VERSION ""

NS_ :

BS_:

BU_: FileEditor Browser FileServer

BO_ 2362179326 PD: 14 Vector__XXX
 SG_ MinimumProductPressure m195 : 32|32@1- (0.1,0) [-2147483648|2147483647] "Pa" Vector__XXX
 SG_ MaximumProductPressure m196 : 32|32@1- (0.1,0) [-2147483648|2147483647] "Pa" Vector__XXX
 SG_ SetpointPumpOutputPressure m197 : 32|32@1- (0.1,0) [-2147483648|2147483647] "Pa" Vector__XXX
 SG_ ActualPumpOutputPressure m198 : 32|32@1- (0.1,0) [-2147483648|2147483647] "Pa" Vector__XXX
 SG_ MinimumPumpOutputPressure m199 : 32|32@1- (0.1,0) [-2147483648|2147483647] "Pa" Vector__XXX
 SG_ MaximumPumpOutputPressure m200 : 32|32@1- (0.1,0) [-2147483648|2147483647] "Pa" Vector__XXX
 SG_ SetpointTankAgitationPressure m201 : 32|32@1- (0.1,0) [-2147483648|2147483647] "Pa" Vector__XXX
 SG_ ActualTankAgitationPressure m202 : 32|32@1- (0.1,0) [-2147483648|2147483647] "Pa" Vector__XXX
 SG_ MinimumTankAgitationPressure m203 : 32|32@1- (0.1,0) [-2147483648|2147483647] "Pa" Vector__XXX
 SG_ MaximumTankAgitationPressure m204 : 32|32@1- (0.1,0) [-2147483648|2147483647] "Pa" Vector__XXX
 SG_ SCTurnOnTime_ m205 : 32|32@1- (1,0) [-2147483648|2147483647] "ms" Vector__XXX
 SG_ SCTurnOffTime m206 : 32|32@1- (1,0) [-2147483648|2147483647] "ms" Vector__XXX
 SG_ WindSpeed m207 : 32|32@1- (1,0) [0|100000000] "mm/s" Vector__XXX
 SG_ WindDirection m208 : 32|32@1- (1,0) [0|359] "°" Vector__XXX
 SG_ AirHumidity m209 : 32|32@1- (1,0) [0|100] "%" Vector__XXX
 SG_ SkyConditions m210 : 32|32@1- (1,0) [-2147483648|2147483647] "" Vector__XXX
 SG_ LastBaleFlakesPerBale m211 : 32|32@1- (1,0) [0|1000] "Amount/Count" Vector__XXX
 SG_ LastBaleAverageMoisture m212 : 32|32@1- (1,0) [0|100000000] "ppm" Vector__XXX
 SG_ LastBaleAverageStrokesPerFlake m213 : 32|32@1- (1,0) [0|1000] "Amount/Count" Vector__XXX
 SG_ LifetimeBaleCount m214 : 32|32@1- (1,0) [0|2147483647] "Amount/Count" Vector__XXX
 SG_ LifetimeWorkingHours m215 : 32|32@1- (0.05,0) [0|2147483647] "h" Vector__XXX
 SG_ ActualBaleHydraulicPressure m216 : 32|32@1- (1,0) [0|2147483647] "Pa" Vector__XXX
 SG_ LastBaleAverageHydraulicPressure m217 : 32|32@1- (1,0) [0|2147483647] "Pa" Vector__XXX
 SG_ SetpointBaleCompressionPlungerLo m218 : 32|32@1- (1,0) [0|2000] "" Vector__XXX
 SG_ ActualBaleCompressionPlungerLoad m219 : 32|32@1- (1,0) [0|2000] "" Vector__XXX
 SG_ LastBaleAverageBaleCompressionPl m220 : 32|32@1- (1,0) [0|2000] "" Vector__XXX
 SG_ LastBaleAppliedPreservative m221 : 32|32@1- (1,0) [0|2147483647] "ml" Vector__XXX
 SG_ LastBaleTagNumber m222 : 32|32@1- (1,0) [0|2147483647] "" Vector__XXX
 SG_ LastBaleMass m223 : 32|32@1- (1,0) [0|2147483647] "g" Vector__XXX
 SG_ DeltaT m224 : 32|32@1- (1,0) [0|1000000] "mK" Vector__XXX
 SG_ SetpointWorkingLength m225 : 32|32@1- (1,0) [-2147483648|2147483647] "mm" Vector__XXX
 SG_ ActualWorkingLength m226 : 32|32@1- (1,0) [-2147483648|2147483647] "mm" Vector__XXX
 SG_ MinimumWorkingLength m227 : 32|32@1- (1,0) [-2147483648|2147483647] "mm" Vector__XXX
 SG_ MaximumWorkingLength m228 : 32|32@1- (1,0) [-2147483648|2147483647] "mm" Vector__XXX
 SG_ ActualNetWeight m229 : 32|32@1- (1,0) [-2147483648|2147483647] "g" Vector__XXX
 SG_ NetWeightState m230 : 32|32@1- (1,0) [0|3] "" Vector__XXX
 SG_ SetpointNetWeight m231 : 32|32@1- (1,0) [-2147483648|2147483647] "g" Vector__XXX
 SG_ ActualGrossWeight m232 : 32|32@1- (1,0) [-2147483648|2147483647] "g" Vector__XXX
 SG_ GrossWeightState m233 : 32|32@1- (1,0) [0|3] "" Vector__XXX
 SG_ MinimumGrossWeight m234 : 32|32@1- (1,0) [-2147483648|2147483647] "g" Vector__XXX
 SG_ MaximumGrossWeight m235 : 32|32@1- (1,0) [-2147483648|2147483647] "g" Vector__XXX
 SG_ ThreshingEngagementTotalTime m236 : 32|32@1- (1,0) [0|2147483647] "s" Vector__XXX
 SG_ ActualHeaderWorkingHeightStatus m237 : 32|32@1- (1,0) [0|3] "" Vector__XXX
 SG_ ActualHeaderRotationalSpeedStatu m238 : 32|32@1- (1,0) [0|3] "" Vector__XXX
 SG_ YieldHoldStatus m239 : 32|32@1- (1,0) [0|3] "" Vector__XXX
 SG_ ActualUnLoadingSystemStatus m240 : 32|32@1- (1,0) [0|771] "" Vector__XXX
 SG_ CropTemperature m241 : 32|32@1- (1,0) [0|1000000] "mK" Vector__XXX
 SG_ SetpointSieveClearance m242 : 32|32@1- (1,0) [0|2147483647] "mm" Vector__XXX
 SG_ ActualSieveClearance m243 : 32|32@1- (1,0) [0|2147483647] "mm" Vector__XXX
 SG_ MinimumSieveClearance m244 : 32|32@1- (1,0) [0|2147483647] "mm" Vector__XXX
 SG_ MaximumSieveClearance m245 : 32|32@1- (1,0) [0|2147483647] "mm" Vector__XXX
 SG_ SetpointChafferClearance m246 : 32|32@1- (1,0) [0|2147483647] "mm" Vector__XXX
 SG_ ActualChafferClearance m247 : 32|32@1- (1,0) [0|2147483647] "mm" Vector__XXX
 SG_ MinimumChafferClearance m248 : 32|32@1- (1,0) [0|2147483647] "mm" Vector__XXX
 SG_ MaximumChafferClearance m249 : 32|32@1- (1,0) [0|2147483647] "mm" Vector__XXX
 SG_ SetpointConcaveClearance m250 : 32|32@1- (1,0) [0|2147483647] "mm" Vector__XXX
 SG_ ActualConcaveClearance m251 : 32|32@1- (1,0) [0|2147483647] "mm" Vector__XXX
 SG_ MinimumConcaveClearance m252 : 32|32@1- (1,0) [0|2147483647] "mm" Vector__XXX
 SG_ MaximumConcaveClearance m253 : 32|32@1- (1,0) [0|2147483647] "mm" Vector__XXX
 SG_ SetpointSeparationFanRotationalS m254 : 32|32@1- (0.001,0) [0|2147483647] "1/s" Vector__XXX
 SG_ ActualSeparationFanRotationalSpe m255 : 32|32@1- (0.001,0) [0|2147483647] "1/s" Vector__XXX
 SG_ MinimumSeparationFanRotationalSp m256 : 32|32@1- (0.001,0) [0|2147483647] "1/s" Vector__XXX
 SG_ MaximumSeparationFanRotationalSp m257 : 32|32@1- (0.001,0) [0|2147483647] "1/s" Vector__XXX
 SG_ HydraulicOilTemperature m258 : 32|32@1- (1,0) [0|2000000] "mK" Vector__XXX
 SG_ YieldLagIgnoreTime m259 : 32|32@1- (1,0) [0|2147483647] "ms" Vector__XXX
 SG_ YieldLeadIgnoreTime m260 : 32|32@1- (1,0) [0|2147483647] "ms" Vector__XXX
 SG_ AverageYieldMassPerTime m261 : 32|32@1- (1,0) [0|2147483647] "mg/s" Vector__XXX
 SG_ AverageCropMoisture m262 : 32|32@1- (1,0) [0|2147483647] "ppm" Vector__XXX
 SG_ AverageYieldMassPerArea m263 : 32|32@1- (1,0) [0|2147483647] "mg/m²" Vector__XXX
 SG_ ConnectorPivotXOffset m264 : 32|32@1- (1,0) [-2147483648|2147483647] "mm" Vector__XXX
 SG_ RemainingArea m265 : 32|32@1- (1,0) [0|2147483647] "m²" Vector__XXX
 SG_ LifetimeApplicationTotalMass m266 : 32|32@1- (1,0) [0|2147483647] "kg" Vector__XXX
 SG_ LifetimeApplicationTotalCount m267 : 32|32@1- (1,0) [0|2147483647] "" Vector__XXX
 SG_ LifetimeYieldTotalVolume m268 : 32|32@1- (1,0) [0|2147483647] "L" Vector__XXX
 SG_ LifetimeYieldTotalMass m269 : 32|32@1- (1,0) [0|2147483647] "kg" Vector__XXX
 SG_ LifetimeYieldTotalCount m270 : 32|32@1- (1,0) [0|2147483647] "" Vector__XXX
 SG_ LifetimeTotalArea m271 : 32|32@1- (1,0) [0|2147483647] "m²" Vector__XXX
 SG_ LifetimeTotalDistance m272 : 32|32@1- (1,0) [0|2147483647] "m" Vector__XXX
 SG_ LifetimeIneffectiveTotalDistance m273 : 32|32@1- (1,0) [0|2147483647] "m" Vector__XXX
 SG_ LifetimeEffectiveTotalTime m274 : 32|32@1- (1,0) [0|2147483647] "s" Vector__XXX
 SG_ LifetimeIneffectiveTotalTime m275 : 32|32@1- (1,0) [0|2147483647] "s" Vector__XXX
 SG_ LifetimeFuelConsumption m276 : 32|32@1- (0.5,0) [0|2147483647] "L" Vector__XXX
 SG_ LifetimeAverageFuelConsumptionPe m277 : 32|32@1- (1,0) [0|2147483647] "mm³/s" Vector__XXX
 SG_ LifetimeAverageFuelConsumpt_0000 m278 : 32|32@1- (1,0) [0|2147483647] "mm³/m²" Vector__XXX
 SG_ LifetimeYieldTotalDryMass m279 : 32|32@1- (1,0) [0|2147483647] "kg" Vector__XXX
 SG_ LifetimeYieldTotalSeedCottonMass m280 : 32|32@1- (1,0) [0|2147483647] "" Vector__XXX
 SG_ LifetimeYieldTotalLintCottonMass m281 : 32|32@1- (1,0) [0|2147483647] "kg" Vector__XXX
 SG_ LifetimeThreshingEngagementTotal m282 : 32|32@1- (1,0) [0|2147483647] "s" Vector__XXX
 SG_ PrecutTotalCount m283 : 32|32@1- (1,0) [0|2147483647] "" Vector__XXX
 SG_ UncutTotalCount m284 : 32|32@1- (1,0) [0|2147483647] "" Vector__XXX
 SG_ LifetimePrecutTotalCount m285 : 32|32@1- (1,0) [0|2147483647] "" Vector__XXX
 SG_ LifetimeUncutTotalCount m286 : 32|32@1- (1,0) [0|2147483647] "" Vector__XXX
 SG_ SetpointWorkState m289 : 32|32@1- (1,0) [0|3] "" Vector__XXX
 SG_ SetpointCondensedWorkState1to16 m290 : 32|32@1+ (1,0) [0|4294967295] "" Vector__XXX
 SG_ SetpointCondensedWorkState17to32 m291 : 32|32@1+ (1,0) [0|4294967295] "" Vector__XXX
 SG_ SetpointCondensedWorkState33to48 m292 : 32|32@1+ (1,0) [0|4294967295] "" Vector__XXX
 SG_ SetpointCondensedWorkState49to64 m293 : 32|32@1+ (1,0) [0|4294967295] "" Vector__XXX
 SG_ SetpointCondensedWorkState65to80 m294 : 32|32@1+ (1,0) [0|4294967295] "" Vector__XXX
 SG_ SetpointCondensedWorkState81to96 m295 : 32|32@1+ (1,0) [0|4294967295] "" Vector__XXX
 SG_ SetpointCondensedWorkState97to11 m296 : 32|32@1+ (1,0) [0|4294967295] "" Vector__XXX
 SG_ SetpointCondensedWorkState113to1 m297 : 32|32@1+ (1,0) [0|4294967295] "" Vector__XXX
 SG_ SetpointCondensedWorkState129to1 m298 : 32|32@1+ (1,0) [0|4294967295] "" Vector__XXX
 SG_ SetpointCondensedWorkState145to1 m299 : 32|32@1+ (1,0) [0|4294967295] "" Vector__XXX
 SG_ SetpointCondensedWorkState161to1 m300 : 32|32@1+ (1,0) [0|4294967295] "" Vector__XXX
 SG_ SetpointCondensedWorkState177to1 m301 : 32|32@1+ (1,0) [0|4294967295] "" Vector__XXX
 SG_ SetpointCondensedWorkState193to2 m302 : 32|32@1+ (1,0) [0|4294967295] "" Vector__XXX
 SG_ SetpointCondensedWorkState209to2 m303 : 32|32@1+ (1,0) [0|4294967295] "" Vector__XXX
 SG_ SetpointCondensedWorkState225to2 m304 : 32|32@1+ (1,0) [0|4294967295] "" Vector__XXX
 SG_ SetpointCondensedWorkState241to2 m305 : 32|32@1+ (1,0) [0|4294967295] "" Vector__XXX
 SG_ TrueRotationPointXOffset m306 : 32|32@1- (1,0) [-2147483648|2147483647] "mm" Vector__XXX
 SG_ TrueRotationPointYOffset m307 : 32|32@1- (1,0) [-2147483648|2147483647] "mm" Vector__XXX
 SG_ ActualPercentageApplicationRate m308 : 32|32@1- (1,0) [0|2147483647] "ppm" Vector__XXX
 SG_ MinimumPercentageApplicationRate m309 : 32|32@1- (1,0) [0|2147483647] "ppm" Vector__XXX
 SG_ MaximumPercentageApplicationRate m310 : 32|32@1- (1,0) [0|2147483647] "ppm" Vector__XXX
 SG_ RelativeYieldPotential m311 : 32|32@1- (1,0) [0|2147483647] "ppm" Vector__XXX
 SG_ MinimumRelativeYieldPotential m312 : 32|32@1- (1,0) [0|2147483647] "ppm" Vector__XXX
 SG_ MaximumRelativeYieldPotential m313 : 32|32@1- (1,0) [0|2147483647] "ppm" Vector__XXX
 SG_ ActualPercentageCropDryMatter m314 : 32|32@1- (1,0) [0|2147483647] "ppm" Vector__XXX
 SG_ AveragePercentageCropDryMatter m315 : 32|32@1- (1,0) [0|2147483647] "ppm" Vector__XXX
 SG_ EffectiveTotalFuelConsumption m316 : 32|32@1- (1,0) [0|2147483647] "ml" Vector__XXX
 SG_ IneffectiveTotalFuelConsumption m317 : 32|32@1- (1,0) [0|2147483647] "ml" Vector__XXX
 SG_ EffectiveTotalDieselExhaustFluid m318 : 32|32@1- (1,0) [0|2147483647] "ml" Vector__XXX
 SG_ IneffectiveTotalDieselExhaustFlu m319 : 32|32@1- (1,0) [0|2147483647] "ml" Vector__XXX
 SG_ LastLoadedWeight m320 : 32|32@1- (1,0) [0|2147483647] "g" Vector__XXX
 SG_ LastUnloadedWeight m321 : 32|32@1- (1,0) [0|2147483647] "g" Vector__XXX
 SG_ PGNBasedData m57342 : 32|32@1- (1,0) [-2147483648|2147483647] "" Vector__XXX
 SG_ RequestDefaultProcessData m57343 : 32|32@1- (1,0) [0|0] "" Vector__XXX
 SG_ ObjectIdOfFaultyObject m9 : 32|16@1+ (1,0) [0|65535] "" Vector__XXX
 SG_ ErrorCodeProcessData1 m13 : 32|1@1+ (1,0) [0|1] "" Vector__XXX
 SG_ StatusTotalsActive m14 : 32|1@1+ (1,0) [0|1] "" Vector__XXX
 SG_ Status_TotalsActive m15 : 32|1@1+ (1,0) [0|1] "" Vector__XXX
 SG_ DateFormatCmd m2 : 32|8@1+ (1,0) [0|255] "" Vector__XXX
 SG_ DataDictionaryVersion m0 : 32|32@1- (1,0) [0|21474800] "" Vector__XXX
 SG_ PeerControlCommand m9M : 32|4@1+ (1,0) [0|5] "" Vector__XXX
 SG_ DecimalSymbolCmd m2 : 30|2@1+ (1,0) [0|3] "" Vector__XXX
 SG_ TimeFormatCmd m2 : 28|2@1+ (1,0) [0|3] "" Vector__XXX
 SG_ ImplementSectionControl m1 : 28|1@1+ (1,0) [0|1] "" Vector__XXX
 SG_ PeerControlAssignment m1 : 27|1@1+ (1,0) [0|1] "" Vector__XXX
 SG_ TC_GEO_DefinitionPositionBasedCo m1 : 26|1@1+ (1,0) [0|1] "" Vector__XXX
 SG_ TimeAndPositionForDataLogging m1 : 25|1@1+ (1,0) [0|1] "" Vector__XXX
 SG_ Documentation m1 : 24|1@1+ (1,0) [0|1] "" Vector__XXX
 SG_ ErrorCodeChangeDesignator m13 : 24|8@1+ (1,0) [0|0] "" Vector__XXX
 SG_ DesignatorLength m12 : 24|8@1+ (1,0) [0|255] "bytes" Vector__XXX
 SG_ ErrorDetailObjectPoolDelete m11 : 16|8@1- (1,0) [0|255] "" Vector__XXX
 SG_ DDI_TI m4 : 16|16@1+ (1,0) [0|65535] "" Vector__XXX
 SG_ DDI_DI m5 : 16|16@1+ (1,0) [0|65535] "" Vector__XXX
 SG_ ErrorDDI m13 : 16|16@1+ (1,0) [0|65535] "" Vector__XXX
 SG_ ParentObjectIdOfFaultyObject m9 : 16|16@1+ (1,0) [0|65535] "" Vector__XXX
 SG_ ReceivedDataSize m7 : 16|32@1+ (1,0) [0|4294967295] "bytes" Vector__XXX
 SG_ DDI m2M : 16|16@1+ (1,0) [0|65535] "" Vector__XXX
 SG_ BootTimeTC m1 : 16|8@1+ (1,0) [0|255] "s" Vector__XXX
 SG_ PeerControlDDI m9 : 16|16@1+ (1,0) [0|65535] "" Vector__XXX
 SG_ ErrorCodeObjPoolActiveResp4 m9 : 11|1@1+ (1,0) [0|0] "" Vector__XXX
 SG_ LanguageCodeCmd m2 : 8|16@1+ (1,0) [0|16383] "" Vector__XXX
 SG_ ErrorCodeObjPoolActiveResp3 m9 : 10|1@1+ (1,0) [0|0] "" Vector__XXX
 SG_ ErrorCodeObjPoolActiveResp2 m9 : 9|1@1+ (1,0) [0|0] "" Vector__XXX
 SG_ StructureLabel m0 : 8|56@1+ (1,0) [0|0] "" Vector__XXX
 SG_ VersionNumberISO11783Part10 m1 : 8|8@1- (1,0) [0|255] "" Vector__XXX
 SG_ RequestTransferDataSize m4 : 8|32@1+ (1,0) [0|4294967295] "bytes" Vector__XXX
 SG_ Status m5 : 8|8@1+ (1,0) [0|1] "" Vector__XXX
 SG_ ErrorCodeObjPoolTransfer m7 : 8|8@1+ (1,0) [0|3] "" Vector__XXX
 SG_ ActivateDeactivateCommand m8 : 8|8@1+ (1,0) [0|255] "" Vector__XXX
 SG_ ErrorCodeObjectPoolDelete m11 : 8|8@1+ (1,0) [0|0] "" Vector__XXX
 SG_ ObjectIdToChange m12 : 8|16@1+ (1,0) [0|65535] "" Vector__XXX
 SG_ ObjectIdChanged m13 : 8|16@1+ (1,0) [0|65535] "" Vector__XXX
 SG_ ErrorCodeObjPoolActiveResp1 m9 : 8|1@1+ (1,0) [0|0] "" Vector__XXX
 SG_ TechnicalDataMsgType m0M : 4|4@1+ (1,0) [0|15] "" Vector__XXX
 SG_ DeviceDescriptionMsgType m1M : 4|4@1+ (1,0) [0|15] "" Vector__XXX
 SG_ ElementNumber m2 : 4|12@1+ (1,0) [0|4095] "" Vector__XXX
 SG_ ErrorElementNumber m13 : 4|12@1+ (1,0) [0|4095] "" Vector__XXX
 SG_ Command M : 0|4@1+ (1,0) [0|15] "" Vector__XXX
 SG_ NumberOfControlChannels m1 : 56|8@1+ (1,0) [0|255] "" Vector__XXX

BO_ 2565799678 ACL: 8 Vector__XXX
 SG_ ReservedBit : 48|1@1+ (1,0) [0|0] "" Vector__XXX
 SG_ ArbitraryAddressCapable : 63|1@1+ (1,0) [0|1] "" Vector__XXX
 SG_ IndustryGroup M : 60|3@1+ (1,0) [0|7] "" Vector__XXX
 SG_ VehicleSystemInstance : 56|4@1+ (1,0) [0|15] "" Vector__XXX
 SG_ VehicleSystem m0 : 49|7@1+ (1,0) [0|127] "" Vector__XXX
 SG_ VehicleSystem5 m5 : 49|7@1+ (1,0) [0|127] "" Vector__XXX
 SG_ VehicleSystem4 m4 : 49|7@1+ (1,0) [0|127] "" Vector__XXX
 SG_ VehicleSystem3 m3 : 49|7@1+ (1,0) [0|127] "" Vector__XXX
 SG_ VehicleSystem2 m2 : 49|7@1+ (1,0) [0|127] "" Vector__XXX
 SG_ VehicleSystem1 m1 : 49|7@1+ (1,0) [0|127] "" Vector__XXX
 SG_ Function : 40|8@1+ (1,0) [0|255] "" Vector__XXX
 SG_ FunctionInstance : 35|5@1+ (1,0) [0|31] "" Vector__XXX
 SG_ ECUInstance : 32|3@1+ (1,0) [0|7] "" Vector__XXX
 SG_ ManufacturerCode : 21|11@1+ (1,0) [0|2047] "" Vector__XXX
 SG_ IdentityNumber : 0|21@1+ (1,0) [0|2097152] "" Vector__XXX

BO_ 2566838526 CA: 9 Vector__XXX
 SG_ AddressAssignment : 64|8@1+ (1,0) [0|255] "" Vector__XXX
 SG_ ArbitraryAddressCapable : 63|1@1+ (1,0) [0|1] "" Vector__XXX
 SG_ IndustryGroup M : 60|3@1+ (1,0) [0|7] "" Vector__XXX
 SG_ VehicleSystemInstance : 56|4@1+ (1,0) [0|15] "" Vector__XXX
 SG_ VehicleSystem1 m1 : 49|7@1+ (1,0) [0|127] "" Vector__XXX
 SG_ VehicleSystem2 m2 : 49|7@1+ (1,0) [0|127] "" Vector__XXX
 SG_ VehicleSystem3 m3 : 49|7@1+ (1,0) [0|127] "" Vector__XXX
 SG_ VehicleSystem4 m4 : 49|7@1+ (1,0) [0|127] "" Vector__XXX
 SG_ VehicleSystem5 m5 : 49|7@1+ (1,0) [0|127] "" Vector__XXX
 SG_ VehicleSystem m0 : 49|7@1+ (1,0) [0|127] "" Vector__XXX
 SG_ Function : 40|8@1+ (1,0) [0|255] "" Vector__XXX
 SG_ FunctionInstance : 35|5@1+ (1,0) [0|31] "" Vector__XXX
 SG_ ECUInstance : 32|3@1+ (1,0) [0|7] "" Vector__XXX
 SG_ ManufacturerCode : 21|11@1+ (1,0) [0|2047] "" Vector__XXX
 SG_ IdentityNumber : 0|21@1+ (1,0) [0|2097152] "" Vector__XXX

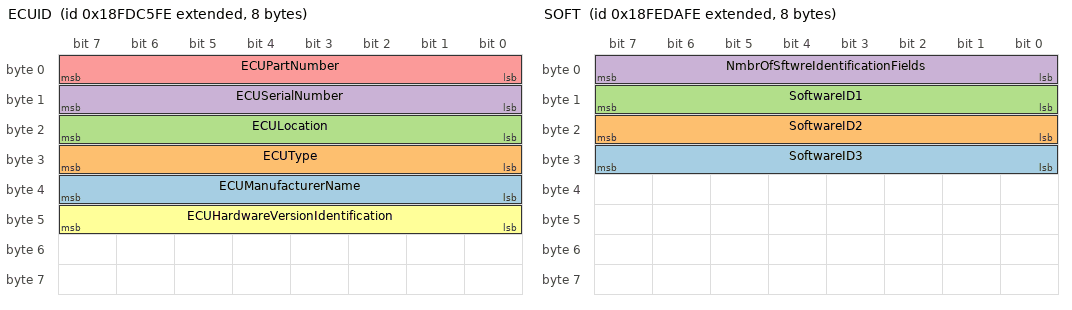
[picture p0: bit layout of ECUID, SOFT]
BO_ 2566768126 ECUID: 8 Vector__XXX
 SG_ ECUManufacturerName : 32|8@1+ (1,0) [0|255] "" Vector__XXX
 SG_ ECUType : 24|8@1+ (1,0) [0|255] "" Vector__XXX
 SG_ ECULocation : 16|8@1+ (1,0) [0|255] "" Vector__XXX
 SG_ ECUSerialNumber : 8|8@1+ (1,0) [0|255] "" Vector__XXX
 SG_ ECUPartNumber : 0|8@1+ (1,0) [0|255] "" Vector__XXX
 SG_ ECUHardwareVersionIdentification : 40|8@1+ (1,0) [0|255] "" Vector__XXX

BO_ 2566839038 SOFT: 8 Vector__XXX
 SG_ SoftwareID3 : 24|8@1+ (1,0) [0|255] "" Vector__XXX
 SG_ SoftwareID2 : 16|8@1+ (1,0) [0|255] "" Vector__XXX
 SG_ SoftwareID1 : 8|8@1+ (1,0) [0|255] "" Vector__XXX
 SG_ NmbrOfSftwreIdentificationFields : 0|8@1+ (1,0) [0|250] "steps" Vector__XXX

BO_ 2566834942 DM1: 22 Vector__XXX
 SG_ DTC5 : 144|32@1+ (1,0) [0|4294967295] "" Vector__XXX
 SG_ DTC4 : 112|32@1+ (1,0) [0|4294967295] "" Vector__XXX
 SG_ DTC3 : 80|32@1+ (1,0) [0|4294967295] "" Vector__XXX
 SG_ DTC2 : 48|32@1+ (1,0) [0|4294967295] "" Vector__XXX
 SG_ DTC1 : 16|32@1+ (1,0) [0|4294967295] "" Vector__XXX

BO_ 2566835198 DM2: 22 Vector__XXX
 SG_ DTC5 : 144|32@1+ (1,0) [0|4294967295] "" Vector__XXX
 SG_ DTC4 : 112|32@1+ (1,0) [0|4294967295] "" Vector__XXX
 SG_ DTC3 : 80|32@1+ (1,0) [0|4294967295] "" Vector__XXX
 SG_ DTC2 : 48|32@1+ (1,0) [0|4294967295] "" Vector__XXX
 SG_ DTC1 : 16|32@1+ (1,0) [0|4294967295] "" Vector__XXX

BO_ 2566734590 ICC: 8 Vector__XXX
 SG_ CertLaboratoryType_FirstDef m0 : 9|3@1+ (1,0) [0|7] "" Vector__XXX
 SG_ TestProtocolRevision_MSBits m1 : 11|2@1+ (1,0) [0|0] "" Vector__XXX
 SG_ MessageRevision M : 47|1@1+ (1,0) [0|0] "" Vector__XXX
 SG_ CertificationReferenceNumber : 48|16@1+ (1,0) [0|65535] "" Vector__XXX
 SG_ CertTypeTaskController m0 : 39|1@1+ (1,0) [0|1] "" Vector__XXX
 SG_ CertTypeTCWorkingSetMaster m0 : 38|1@1+ (1,0) [0|1] "" Vector__XXX
 SG_ CertTypeTCWorkingSetMember m0 : 37|1@1+ (1,0) [0|1] "" Vector__XXX
 SG_ CertTypeFileServer m0 : 36|1@1+ (1,0) [0|1] "" Vector__XXX
 SG_ CertTypeGPSReceiver m0 : 35|1@1+ (1,0) [0|1] "" Vector__XXX
 SG_ CertTypeMinimumECU m0 : 31|1@1+ (1,0) [0|1] "" Vector__XXX
 SG_ CertTypeTECUClass1 m0 : 30|1@1+ (1,0) [0|1] "" Vector__XXX
 SG_ CertTypeTECUClass2 m0 : 29|1@1+ (1,0) [0|1] "" Vector__XXX
 SG_ CertTypeTECUClass3 m0 : 28|1@1+ (1,0) [0|1] "" Vector__XXX
 SG_ CertTypeClass3ECU m0 : 27|1@1+ (1,0) [0|1] "" Vector__XXX
 SG_ CertTypeVirtualTerminal m0 : 26|1@1+ (1,0) [0|1] "" Vector__XXX
 SG_ CertTypeVTWorkingSetMaster m0 : 25|1@1+ (1,0) [0|1] "" Vector__XXX
 SG_ CertTypeVTWorkingSetMember m0 : 24|1@1+ (1,0) [0|1] "" Vector__XXX
 SG_ CertificationLaboratoryID : 13|11@1+ (1,0) [0|2047] "" Vector__XXX
 SG_ CertLaboratoryType_SecondDef m1 : 9|2@1+ (1,0) [0|3] "" Vector__XXX
 SG_ TestProtocolRevision : 6|3@1+ (1,0) [0|7] "" Vector__XXX
 SG_ TestProtocolPublicationYear : 0|6@1+ (1,2000) [2000|2061] "year" Vector__XXX

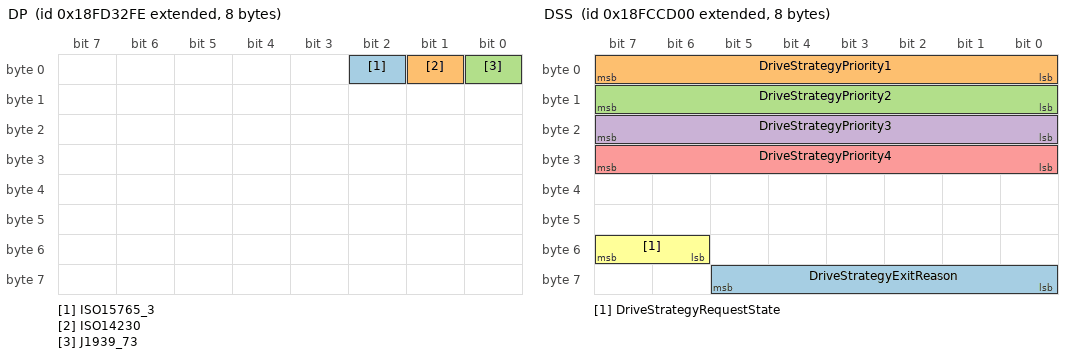
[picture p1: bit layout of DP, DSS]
BO_ 2566730494 DP: 8 Vector__XXX
 SG_ ISO15765_3 : 2|1@1+ (1,0) [0|1] "" Vector__XXX
 SG_ ISO14230 : 1|1@1+ (1,0) [0|1] "" Vector__XXX
 SG_ J1939_73 : 0|1@1+ (1,0) [0|1] "" Vector__XXX

BO_ 2566835454 DM3: 0 Vector__XXX

BO_ 2365391616 IOS: 8 Vector__XXX
 SG_ ImplementOperatingStateCmd : 56|2@1+ (1,0) [0|3] "" Vector__XXX

BO_ 2365391614 AISO: 8 Vector__XXX
 SG_ StopAllImplOpTransitionNum : 48|8@1+ (1,0) [0|0] "" Vector__XXX
 SG_ StopAllImplOpSwitchState : 56|2@1- (1,0) [0|3] "" Vector__XXX

BO_ 2559835902 NM: 8 Vector__XXX
 SG_ ManufacturerCodeQualifierFlag m0 : 8|1@1+ (1,0) [0|1] "" Vector__XXX
 SG_ ECUInstanceQualifierFlag m0 : 9|1@1+ (1,0) [0|1] "" Vector__XXX
 SG_ FunctionInstanceQualifierFlag m0 : 10|1@1+ (1,0) [0|1] "" Vector__XXX
 SG_ FunctionQualifierFlag m0 : 11|1@1+ (1,0) [0|1] "" Vector__XXX
 SG_ VehicleSystemQualifierFlag m0 : 12|1@1+ (1,0) [0|1] "" Vector__XXX
 SG_ VehicleSystemInstanceQualifierFl m0 : 13|1@1+ (1,0) [0|1] "" Vector__XXX
 SG_ IndustryGroupQualifierFlag m0 : 14|1@1+ (1,0) [0|1] "" Vector__XXX
 SG_ ArbitraryAddressCapableQualifier m0 : 15|1@1+ (1,0) [0|1] "" Vector__XXX
 SG_ NMControlModeIndicator M : 16|4@1+ (1,0) [0|15] "" Vector__XXX
 SG_ CommandManufacturerCode m0 : 21|11@1+ (1,0) [0|2047] "" Vector__XXX
 SG_ CommandECUInstance m0 : 32|3@1+ (1,0) [0|7] "" Vector__XXX
 SG_ CommandFunctionInstance m0 : 35|5@1+ (1,0) [0|31] "" Vector__XXX
 SG_ CommandFunction m0 : 40|8@1+ (1,0) [0|255] "" Vector__XXX
 SG_ CommandVehicleSystem m0 : 49|7@1+ (1,0) [0|127] "" Vector__XXX
 SG_ CommandIndustryGroup m0 : 60|3@1+ (1,0) [0|7] "" Vector__XXX
 SG_ CommandVehicleSystemInstance m0 : 56|4@1+ (1,0) [0|15] "" Vector__XXX
 SG_ CommandArbitraryAddressCapable m0 : 63|1@1+ (1,0) [0|1] "" Vector__XXX
 SG_ ErrorCode m4 : 0|8@1+ (1,0) [0|0] "" Vector__XXX
 SG_ NameChecksum m0 : 0|8@1+ (1,0) [0|0] "" Vector__XXX

BO_ 2566843646 VI: 8 Vector__XXX
 SG_ VehicleIdentificationNumber : 0|8@1+ (1,0) [0|255] "per byte" Vector__XXX

BO_ 2566704384 DSS: 8 Vector__XXX
 SG_ DriveStrategyExitReason : 56|6@1+ (1,0) [0|63] "" Vector__XXX
 SG_ DriveStrategyPriority1 : 0|8@1+ (1,0) [0|255] "" Vector__XXX
 SG_ DriveStrategyPriority2 : 8|8@1+ (1,0) [0|255] "" Vector__XXX
 SG_ DriveStrategyPriority3 : 16|8@1+ (1,0) [0|255] "" Vector__XXX
 SG_ DriveStrategyPriority4 : 24|8@1+ (1,0) [0|255] "" Vector__XXX
 SG_ DriveStrategyRequestState : 54|2@1+ (1,0) [0|3] "" Vector__XXX

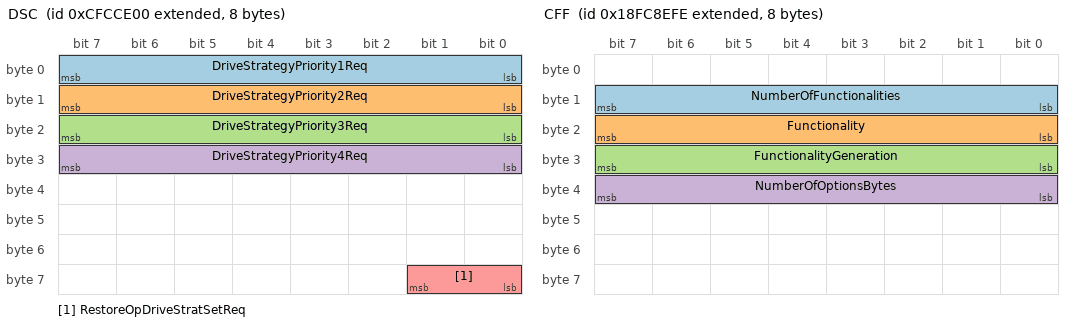
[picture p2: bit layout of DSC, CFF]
BO_ 2365378048 DSC: 8 Vector__XXX
 SG_ DriveStrategyPriority1Req : 0|8@1+ (1,0) [0|255] "" Vector__XXX
 SG_ DriveStrategyPriority2Req : 8|8@1+ (1,0) [0|255] "" Vector__XXX
 SG_ DriveStrategyPriority3Req : 16|8@1+ (1,0) [0|255] "" Vector__XXX
 SG_ DriveStrategyPriority4Req : 24|8@1+ (1,0) [0|255] "" Vector__XXX
 SG_ RestoreOpDriveStratSetReq : 56|2@1+ (1,0) [0|3] "" Vector__XXX

BO_ 2566688510 CFF: 8 Vector__XXX
 SG_ NumberOfFunctionalities : 8|8@1- (1,0) [1|255] "" Vector__XXX
 SG_ Functionality : 16|8@1- (1,0) [0|255] "" Vector__XXX
 SG_ FunctionalityGeneration : 24|8@1- (1,0) [1|255] "" Vector__XXX
 SG_ NumberOfOptionsBytes : 32|8@1- (1,0) [0|255] "" Vector__XXX

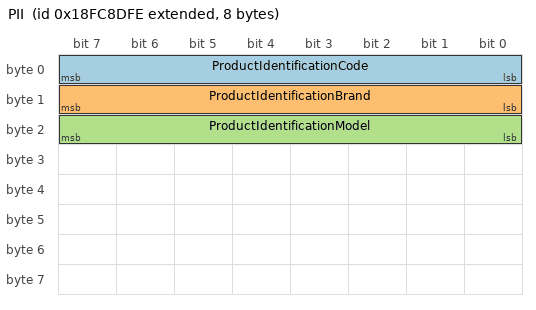
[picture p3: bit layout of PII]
BO_ 2566688254 PII: 8 Vector__XXX
 SG_ ProductIdentificationCode : 0|8@1- (1,0) [0|0] "" Vector__XXX
 SG_ ProductIdentificationBrand : 8|8@1- (1,0) [0|0] "" Vector__XXX
 SG_ ProductIdentificationModel : 16|8@1- (1,0) [0|0] "" Vector__XXX

CM_ SG_ 2362179326 MinimumProductPressure "Minimun Product Pressure in the product flow system at the point of dispensing. ";
CM_ SG_ 2362179326 MaximumProductPressure "Maximum Product Pressure in the product flow system at the point of dispensing.";
CM_ SG_ 2362179326 SetpointPumpOutputPressure "Setpoint Pump Output Pressure to adjust the  pressure at the output of the solution pump.";
CM_ SG_ 2362179326 ActualPumpOutputPressure "Actual Pump Output Pressure measured at the output of the solution pump.";
CM_ SG_ 2362179326 MinimumPumpOutputPressure "Minimum Pump Output Pressure for the output pressure of the solution pump.";
CM_ SG_ 2362179326 MaximumPumpOutputPressure "Maximum Pump Output Pressure for the output pressure of the solution pump.";
CM_ SG_ 2362179326 SetpointTankAgitationPressure "Setpoint Tank Agitation Pressure to adjust the pressure for a stir system in a tank.";
CM_ SG_ 2362179326 ActualTankAgitationPressure "Actual Tank Agitation Pressure measured by the tank stir system.";
CM_ SG_ 2362179326 MinimumTankAgitationPressure "Minimun Tank Agitation Pressure for a stir system in a tank.";
CM_ SG_ 2362179326 MaximumTankAgitationPressure "Maximun Tank Agitation Pressure for a stir system in a tank.";
CM_ SG_ 2362179326 SCTurnOnTime_ "The Section Control Turn On Time defines the overall time lapse 
between the moment the TC sends a turn on section command 
to the working set and the moment this section 
is physically turned on and the product is applied.";
CM_ SG_ 2362179326 SCTurnOffTime "The Section Control Turn Off Time defines the overall time lapse 
between the moment the TC sends a turn off section command 
to the working set and the moment this section is physically turned off.";
CM_ SG_ 2362179326 WindSpeed "Wind speed measured in the treated field 
at the beginning of operations 
or on the application implement during operations.";
CM_ SG_ 2362179326 WindDirection "Wind direction measured in the treated field 
at the beginning of operations 
or on the application implement during operations.";
CM_ SG_ 2362179326 AirHumidity "Ambient humidty measured by a weather station 
in a treated field or on the application implement.";
CM_ SG_ 2362179326 SkyConditions "This DDE is used to define the current sky conditions during operation.";
CM_ SG_ 2362179326 LastBaleFlakesPerBale "The number of flakes in the most recently produced bale.";
CM_ SG_ 2362179326 LastBaleAverageMoisture "The average moisture in the most recently produced bale.";
CM_ SG_ 2362179326 LastBaleAverageStrokesPerFlake "The number of baler plunger compression strokes per flake 
that has entered the bale compression chamber. 
This value is the average valid for the most recently produced bale.";
CM_ SG_ 2362179326 LifetimeBaleCount "The number of bales produced by a machine over its entire lifetime.";
CM_ SG_ 2362179326 LifetimeWorkingHours "The number of working hours of a device element over its entire lifetime.";
CM_ SG_ 2362179326 ActualBaleHydraulicPressure "The actual value of the hydraulic pressure applied 
to the sides of the bale in the bale compression chamber.";
CM_ SG_ 2362179326 LastBaleAverageHydraulicPressure "The average actual value of the hydraulic pressure applied 
to the sides of the bale in the bale compression chamber.";
CM_ SG_ 2362179326 SetpointBaleCompressionPlungerLo "The setpoint bale compression plunger load as a unitless number.";
CM_ SG_ 2362179326 ActualBaleCompressionPlungerLoad "The actual bale compression plunger load as a unitless number.";
CM_ SG_ 2362179326 LastBaleAverageBaleCompressionPl "The average bale compression plunger load for the most recently produced bale.";
CM_ SG_ 2362179326 LastBaleAppliedPreservative "The total preservative applied to the most recently produced bale.";
CM_ SG_ 2362179326 LastBaleTagNumber "The Last Bale Tag Number as a decimal number in the range of 0 to 4294967295.";
CM_ SG_ 2362179326 LastBaleMass "The mass of the bale that has most recently been produced.";
CM_ SG_ 2362179326 DeltaT "The difference between dry bulb temperature and wet bulb temperature measured 
by a weather station in a treated field or on the application equipment.";
CM_ SG_ 2362179326 SetpointWorkingLength "This is the desired working length of the device element during operation.";
CM_ SG_ 2362179326 ActualWorkingLength "Actual Working Length of a Device Element.";
CM_ SG_ 2362179326 MinimumWorkingLength "This is the minimum working length of the device element during operation.";
CM_ SG_ 2362179326 MaximumWorkingLength "This is the maximum working length of the device element during operation.";
CM_ SG_ 2362179326 ActualNetWeight "The Actual Net Weight is the current measured mass by a weighing system.";
CM_ SG_ 2362179326 NetWeightState "The Net Weight State indicates whether the current 
Actual Net Weight value is a reliable value or not.";
CM_ SG_ 2362179326 SetpointNetWeight "The Setpoint Net Weight value is used to prompt 
the weighing system to perform a tare procedure.";
CM_ SG_ 2362179326 ActualGrossWeight "The Actual Gross Weight is the overall 
measured mass by a weighing system.";
CM_ SG_ 2362179326 GrossWeightState "The Gross Weight State indicates whether the current 
Actual Gross Weight value is a reliable value or not.";
CM_ SG_ 2362179326 MinimumGrossWeight "The Minimum Gross Weight may represent the minimum value 
of the effective range of the weighing system.";
CM_ SG_ 2362179326 MaximumGrossWeight "Maximum Gross Weight may represent the maximum value 
of the effective range of the weighing system.";
CM_ SG_ 2362179326 ThreshingEngagementTotalTime "Accumulated time while the threshing mechanism is engaged";
CM_ SG_ 2362179326 ActualHeaderWorkingHeightStatus "Actual status of the header being above or below 
the threshold height for the in-work state.";
CM_ SG_ 2362179326 ActualHeaderRotationalSpeedStatu "Actual status of the header rotational speed 
being above or below the threshold for in-work state.";
CM_ SG_ 2362179326 YieldHoldStatus "Status indicator for the yield measurement system. ";
CM_ SG_ 2362179326 ActualUnLoadingSystemStatus "Actual status of the Unloading and/or Loading system.";
CM_ SG_ 2362179326 CropTemperature "Temperature of harvested crop";
CM_ SG_ 2362179326 SetpointSieveClearance "Setpoint separation distance between Sieve elements";
CM_ SG_ 2362179326 ActualSieveClearance "Actual separation distance between Sieve elements";
CM_ SG_ 2362179326 MinimumSieveClearance "Minimal separation distance between Sieve elements";
CM_ SG_ 2362179326 MaximumSieveClearance "Maximum separation distance between Sieve elements.";
CM_ SG_ 2362179326 SetpointChafferClearance "Setpoint separation distance between Chaffer elements.";
CM_ SG_ 2362179326 ActualChafferClearance "Actual separation distance between Chaffer elements.";
CM_ SG_ 2362179326 MinimumChafferClearance "Minimum separation distance between Chaffer elements.";
CM_ SG_ 2362179326 MaximumChafferClearance "Maximum separation distance between Chaffer elements.";
CM_ SG_ 2362179326 SetpointConcaveClearance "Setpoint separation distance between Concave elements.";
CM_ SG_ 2362179326 ActualConcaveClearance "Actual separation distance between Concave elements.";
CM_ SG_ 2362179326 MinimumConcaveClearance "Minimum separation distance between Concave elements.";
CM_ SG_ 2362179326 MaximumConcaveClearance "Maximum separation distance between Concave elements.";
CM_ SG_ 2362179326 SetpointSeparationFanRotationalS "Setpoint rotational speed of the fan used 
for separating product material from non product material.";
CM_ SG_ 2362179326 ActualSeparationFanRotationalSpe "Actual rotational speed of the fan used 
for separating product material from non product material.";
CM_ SG_ 2362179326 MinimumSeparationFanRotationalSp "Minimum rotational speed of the fan used 
for separating product material from non product material.";
CM_ SG_ 2362179326 MaximumSeparationFanRotationalSp "Maximum rotational speed of the fan used 
for separating product material from non product material.";
CM_ SG_ 2362179326 HydraulicOilTemperature "Temperature of fluid in the hydraulic system.";
CM_ SG_ 2362179326 YieldLagIgnoreTime "Amount of time to ignore yield data, 
starting at the transition from the in-work to the out-of-work state. 
During this time, the yield sensor provides 
inconsistent or unreliable crop flow data.";
CM_ SG_ 2362179326 YieldLeadIgnoreTime "Amount of time to ignore yield data, 
starting at the transition from the out-of-work to the in-work state. 
During this time, the yield sensor provides 
inconsistent or unreliable crop flow data.";
CM_ SG_ 2362179326 AverageYieldMassPerTime "Average Yield expressed as mass per unit time, 
not corrected for the reference moisture percentage DDI 184. 
This value is the average for a Task and may be reported as a total.";
CM_ SG_ 2362179326 AverageCropMoisture "Average Moisture of the harvested crop. 
This value is the average for a Task and may be reported as a total.";
CM_ SG_ 2362179326 AverageYieldMassPerArea "This Average Yield Mass Per Area is the mass that includes the average crop moisture (DDI 262) i";
CM_ SG_ 2362179326 ConnectorPivotXOffset "X direction offset of a connector pivot point relative to DRP";
CM_ SG_ 2362179326 RemainingArea "Remaining Area of a field";
CM_ SG_ 2362179326 LifetimeApplicationTotalMass "Entire Application Total Count of the device lifetime";
CM_ SG_ 2362179326 LifetimeApplicationTotalCount "Entire Application Total Count of the device lifetime";
CM_ SG_ 2362179326 LifetimeYieldTotalVolume "Entire Yield Total Volume of the device lifetime";
CM_ SG_ 2362179326 LifetimeYieldTotalMass "Entire Yield Total Mass of the device lifetime";
CM_ SG_ 2362179326 LifetimeYieldTotalCount "Entire Yield Total Count of the device lifetime";
CM_ SG_ 2362179326 LifetimeTotalArea "Entire Total Area of the device lifetime";
CM_ SG_ 2362179326 LifetimeTotalDistance "Entire Total Area of the device lifetime";
CM_ SG_ 2362179326 LifetimeIneffectiveTotalDistance "Entire Ineffective Total Distance of the device lifetime";
CM_ SG_ 2362179326 LifetimeEffectiveTotalTime "Entire Ineffective Total Distance of the device lifetime";
CM_ SG_ 2362179326 LifetimeIneffectiveTotalTime "Entire Ineffective Total Time of the device lifetime";
CM_ SG_ 2362179326 LifetimeFuelConsumption "Entire Fuel Consumption of the device lifetime";
CM_ SG_ 2362179326 LifetimeAverageFuelConsumptionPe "Entire Average Fuel Consumption per Time of the device lifetime";
CM_ SG_ 2362179326 LifetimeAverageFuelConsumpt_0000 "Entire Average Fuel Consumption per Area of the device lifetime";
CM_ SG_ 2362179326 LifetimeYieldTotalDryMass "Entire Yield Total Dry Mass of the device lifetime";
CM_ SG_ 2362179326 LifetimeYieldTotalSeedCottonMass "Entire Yield Total Seed Cotton Mass of the device lifetime";
CM_ SG_ 2362179326 LifetimeYieldTotalLintCottonMass "Entire Yield Total Lint Cotton Mass of the device lifetime";
CM_ SG_ 2362179326 LifetimeThreshingEngagementTotal "Entire Threshing Engagement Total Time of the device lifetime";
CM_ SG_ 2362179326 PrecutTotalCount "The total number of pre-cutted product units produced by a device during an operation";
CM_ SG_ 2362179326 UncutTotalCount "The total number of un-cutted product units produced by a device during an operation";
CM_ SG_ 2362179326 LifetimePrecutTotalCount "Entire Precut Total Count of the device lifetime";
CM_ SG_ 2362179326 LifetimeUncutTotalCount "Entire Uncut Total Count of the device lifetime";
CM_ SG_ 2362179326 SetpointWorkState "The Setpoint Work State DDI is the control command counterparts to the Work State DDI (141)";
CM_ SG_ 2362179326 SetpointCondensedWorkState1to16 "The Setpoint Condensed Work State DDIs are the control command counterparts to the Condensed Work States DDIs (161 – 176)";
CM_ SG_ 2362179326 SetpointCondensedWorkState17to32 "The Setpoint Condensed Work State DDIs are the control command counterparts to the Condensed Work States DDIs (161 – 176)";
CM_ SG_ 2362179326 SetpointCondensedWorkState33to48 "The Setpoint Condensed Work State DDIs are the control command counterparts to the Condensed Work States DDIs (161 – 176)";
CM_ SG_ 2362179326 SetpointCondensedWorkState49to64 "The Setpoint Condensed Work State DDIs are the control command counterparts to the Condensed Work States DDIs (161 – 176)";
CM_ SG_ 2362179326 SetpointCondensedWorkState65to80 "The Setpoint Condensed Work State DDIs are the control command counterparts to the Condensed Work States DDIs (161 – 176)";
CM_ SG_ 2362179326 SetpointCondensedWorkState81to96 "The Setpoint Condensed Work State DDIs are the control command counterparts to the Condensed Work States DDIs (161 – 176)";
CM_ SG_ 2362179326 SetpointCondensedWorkState97to11 "The Setpoint Condensed Work State DDIs are the control command counterparts to the Condensed Work States DDIs (161 – 176)";
CM_ SG_ 2362179326 SetpointCondensedWorkState113to1 "The Setpoint Condensed Work State DDIs are the control command counterparts to the Condensed Work States DDIs (161 – 176)";
CM_ SG_ 2362179326 SetpointCondensedWorkState129to1 "The Setpoint Condensed Work State DDIs are the control command counterparts to the Condensed Work States DDIs (161 – 176)";
CM_ SG_ 2362179326 SetpointCondensedWorkState145to1 "The Setpoint Condensed Work State DDIs are the control command counterparts to the Condensed Work States DDIs (161 – 176)";
CM_ SG_ 2362179326 SetpointCondensedWorkState161to1 "The Setpoint Condensed Work State DDIs are the control command counterparts to the Condensed Work States DDIs (161 – 176)";
CM_ SG_ 2362179326 SetpointCondensedWorkState177to1 "The Setpoint Condensed Work State DDIs are the control command counterparts to the Condensed Work States DDIs (161 – 176)";
CM_ SG_ 2362179326 SetpointCondensedWorkState193to2 "The Setpoint Condensed Work State DDIs are the control command counterparts to the Condensed Work States DDIs (161 – 176)";
CM_ SG_ 2362179326 SetpointCondensedWorkState209to2 "The Setpoint Condensed Work State DDIs are the control command counterparts to the Condensed Work States DDIs (161 – 176)";
CM_ SG_ 2362179326 SetpointCondensedWorkState225to2 "The Setpoint Condensed Work State DDIs are the control command counterparts to the Condensed Work States DDIs (161 – 176)";
CM_ SG_ 2362179326 SetpointCondensedWorkState241to2 "The Setpoint Condensed Work State DDIs are the control command counterparts to the Condensed Work States DDIs (161 – 176)";
CM_ SG_ 2362179326 TrueRotationPointXOffset "X direction offset of the device rotation point relative to the DRP";
CM_ SG_ 2362179326 TrueRotationPointYOffset "Y direction offset of the device rotation point relative to the DRP";
CM_ SG_ 2362179326 ActualPercentageApplicationRate "Actual Application Rate expressed as percentage";
CM_ SG_ 2362179326 MinimumPercentageApplicationRate "Actual Application Rate expressed as percentage";
CM_ SG_ 2362179326 MaximumPercentageApplicationRate "Maximum Application Rate expressed as percentage";
CM_ SG_ 2362179326 RelativeYieldPotential "Relative yield potential provided by a FMIS or a sensor or entered by the operator for a certain task expressed as percentage";
CM_ SG_ 2362179326 MinimumRelativeYieldPotential "Minimum potential yield expressed as percentage";
CM_ SG_ 2362179326 MaximumRelativeYieldPotential "Maximum potential yield expressed as percentage";
CM_ SG_ 2362179326 ActualPercentageCropDryMatter "Actual Percentage Crop Dry Matter expressed as parts per million";
CM_ SG_ 2362179326 AveragePercentageCropDryMatter "Average Percentage Crop Dry Matter expressed as parts per million";
CM_ SG_ 2362179326 EffectiveTotalFuelConsumption "Accumulated total fuel consumption in working position";
CM_ SG_ 2362179326 IneffectiveTotalFuelConsumption "Accumulated total fuel consumption in non working position";
CM_ SG_ 2362179326 EffectiveTotalDieselExhaustFluid "Accumulated total Diesel Exhaust Fluid consumption in working position";
CM_ SG_ 2362179326 IneffectiveTotalDieselExhaustFlu "Accumulated total Diesel Exhaust Fluid consumption in non working position";
CM_ SG_ 2362179326 LastLoadedWeight "Last loaded Weight value specified as mass";
CM_ SG_ 2362179326 LastUnloadedWeight "Last unloaded Weight value specified as mass";
CM_ SG_ 2362179326 PGNBasedData "This DDI is used in the XML files to identify PGN based data";
CM_ SG_ 2362179326 RequestDefaultProcessData "Request Default Process Data.";
CM_ SG_ 2362179326 DataDictionaryVersion "This DDE is used to specify which version of the Data Dictionary is being used.";
CM_ SG_ 2362179326 DDI_TI "Data Dictionary Identifier";
CM_ SG_ 2362179326 DDI_DI "Data Dictionary Identifier";
CM_ SG_ 2362179326 ErrorDDI "Data Dictionary Identifier";
CM_ SG_ 2362179326 DDI "Data Dictionary Identifier";
CM_ SG_ 2362179326 BootTimeTC "Maximum number of seconds from a power cycle to transmission of first Task Controller Status message";
CM_ SG_ 2362179326 PeerControlDDI "Data Dictionary Identifier";
CM_ SG_ 2362179326 ElementNumber "Device Element Number";
CM_ SG_ 2362179326 ErrorElementNumber "Device Element Number";
CM_ SG_ 2362179326 Command "Process Data Command";
CM_ SG_ 2362179326 NumberOfControlChannels "Number of control channels for position based control";
CM_ BO_ 2565799678 "Address Claimed";
CM_ SG_ 2565799678 ReservedBit "The reserved bit shall be set to zero.";
CM_ BO_ 2566838526 "Commanded Address";
CM_ SG_ 2566838526 AddressAssignment "The source address that is to be assigned to the CA that has the NAME corresponding to the one conveyed in the first eight bytes of this Commanded Address message.";
CM_ BO_ 2566768126 "ECU Identification Information";
CM_ SG_ 2566768126 ECULocation "The location of the ECU within a network.";
CM_ SG_ 2566768126 ECUSerialNumber "The serial number of the physical ECU.";
CM_ SG_ 2566768126 ECUPartNumber "The part number of the physical ECU.";
CM_ SG_ 2566768126 ECUHardwareVersionIdentification "The part number of the physical ECU.";
CM_ BO_ 2566839038 "Software Identification";
CM_ SG_ 2566839038 SoftwareID3 "Software ID";
CM_ SG_ 2566839038 SoftwareID2 "Software ID";
CM_ SG_ 2566839038 SoftwareID1 "Software ID";
CM_ SG_ 2566839038 NmbrOfSftwreIdentificationFields "Number of software identification designators represented in the software identification parameter group.";
CM_ BO_ 2566834942 "Active diagnostic trouble codes";
CM_ SG_ 2566834942 DTC5 "Diagnostic Trouble Code";
CM_ SG_ 2566834942 DTC4 "Diagnostic Trouble Code";
CM_ SG_ 2566834942 DTC3 "Diagnostic Trouble Code";
CM_ SG_ 2566834942 DTC2 "Diagnostic Trouble Code";
CM_ SG_ 2566834942 DTC1 "Diagnostic Trouble Code";
CM_ BO_ 2566835198 "Previously active diagnostic trouble codes";
CM_ SG_ 2566835198 DTC5 "Diagnostic Trouble Code";
CM_ SG_ 2566835198 DTC4 "Diagnostic Trouble Code";
CM_ SG_ 2566835198 DTC3 "Diagnostic Trouble Code";
CM_ SG_ 2566835198 DTC2 "Diagnostic Trouble Code";
CM_ SG_ 2566835198 DTC1 "Diagnostic Trouble Code";
CM_ BO_ 2566734590 "ISOBUS compliance certification";
CM_ SG_ 2566734590 CertLaboratoryType_FirstDef "Approving body for the certification laboratory.";
CM_ SG_ 2566734590 MessageRevision "This parameter distinguishes the format of the ISOBUS Compliance Certification message in the second 
edition from the format in the third and later editions.";
CM_ SG_ 2566734590 CertificationReferenceNumber "ISOBUS Compliance certification reference number";
CM_ SG_ 2566734590 CertTypeTaskController "ISOBUS Compliance certification type - Task Controller";
CM_ SG_ 2566734590 CertTypeTCWorkingSetMaster "ISOBUS Compliance certification type - TC working set master";
CM_ SG_ 2566734590 CertTypeTCWorkingSetMember "ISOBUS Compliance certification type - TC working set member";
CM_ SG_ 2566734590 CertTypeFileServer "ISOBUS Compliance certification type - File server";
CM_ SG_ 2566734590 CertTypeGPSReceiver "ISOBUS Compliance certification type - GPS receiver";
CM_ SG_ 2566734590 CertTypeMinimumECU "ISOBUS Compliance certification type - Minimum ECU";
CM_ SG_ 2566734590 CertTypeTECUClass1 "ISOBUS Compliance certification type - TECU Class 1";
CM_ SG_ 2566734590 CertTypeTECUClass2 "ISOBUS Compliance certification type - TECU Class 2";
CM_ SG_ 2566734590 CertTypeTECUClass3 "ISOBUS Compliance certification type - TECU Class 3";
CM_ SG_ 2566734590 CertTypeClass3ECU "ISOBUS Compliance certification type - Class 3 ECU";
CM_ SG_ 2566734590 CertTypeVirtualTerminal "ISOBUS Compliance certification type - Virtual terminal";
CM_ SG_ 2566734590 CertTypeVTWorkingSetMaster "ISOBUS Compliance certification type - VT working set master";
CM_ SG_ 2566734590 CertTypeVTWorkingSetMember "ISOBUS Compliance certification type - VT working set member";
CM_ SG_ 2566734590 CertificationLaboratoryID "ISOBUS Compliance certification laboratory ID";
CM_ SG_ 2566734590 CertLaboratoryType_SecondDef "Approving body for the certification laboratory.";
CM_ SG_ 2566734590 TestProtocolRevision "ISOBUS compliance certificate revision";
CM_ SG_ 2566734590 TestProtocolPublicationYear "ISOBUS compliance certification year";
CM_ BO_ 2566730494 "ECU diagnostic protocol";
CM_ SG_ 2566730494 ISO15765_3 "ISO 15765-3 (UDS on CAN)";
CM_ SG_ 2566730494 ISO14230 "ISO 14230 (KWP 2000 over K line)";
CM_ SG_ 2566730494 J1939_73 "J1939-73";
CM_ BO_ 2566835454 "Diagnostic data clear/reset of previously active DTCs.";
CM_ BO_ 2365391616 "Implement operating state command";
CM_ BO_ 2365391614 " All implements stop operations switch state";
CM_ SG_ 2365391614 StopAllImplOpTransitionNum "This parameter indicates the number of transitions from Permit (01) to Stop (00) since power up of 
the Stop all implement operations parameter. The parameter resets to zero on the next transition after 
reporting the maximum value.";
CM_ BO_ 2566843646 "Byte: 1-n Vehicle Identification Number 
Delimiter (ASCII “*”)";
CM_ SG_ 2566843646 VehicleIdentificationNumber "Vehicle Identification Number (VIN) as assigned by the vehicle manufacturer.";
CM_ BO_ 2566704384 "Message sent from the tractor to the implement to indicate the current status, of the drive strategy priority 
structure, which indicates the priority of the multiple powertrain functions. ";
CM_ SG_ 2566704384 DriveStrategyExitReason "Parameter used to indicate why the drive strategy subsystem cannot currently accept remote commands or 
has most recently stopped accepting remote commands.";
CM_ SG_ 2566704384 DriveStrategyPriority1 "This parameter indicates the current Tractor drive strategy priority structure, which determines the balance 
between  fuel  economy/consumption  and  the  torque  reserve  of  the  engine.  This  parameter  indicates  the 
highest priority. ";
CM_ SG_ 2566704384 DriveStrategyPriority2 "This parameter indicates the current Tractor drive strategy priority structure, which determines the balance 
between  fuel  economy/consumption  and  the  torque  reserve  of  the  engine.  This  parameter  indicates 
 the second to highest priority. ";
CM_ SG_ 2566704384 DriveStrategyPriority3 "This parameter indicates the current Tractor drive strategy priority structure, which determines the balance 
between  fuel  economy/consumption  and  the  torque  reserve  of  the  engine.  This  parameter  indicates 
 the third to highest priority. ";
CM_ SG_ 2566704384 DriveStrategyPriority4 "This parameter indicates the current Tractor drive strategy priority structure, which determines the balance 
between  fuel  economy/consumption  and  the  torque  reserve  of  the  engine.  This  parameter  indicates  the 
lowest priority. ";
CM_ SG_ 2566704384 DriveStrategyRequestState "This  parmeter  reports  the  tractor's  state  associated  with  Drive  Strategy  requests  that  are 
transient/temporary/one-shot.";
CM_ SG_ 2365378048 DriveStrategyPriority1Req "This parameter used to request an alteration to the tractor drive strategy priority structure, which determines 
the  balance  between  fuel  economy/consumption  and  the  torque  reserve  of  the  engine - the highest priority request.";
CM_ SG_ 2365378048 DriveStrategyPriority2Req "This parameter used to request an alteration to the tractor drive strategy priority structure, which determines 
the  balance  between  fuel  economy/consumption  and  the  torque  reserve  of  the  engine - the second to highest priority request.";
CM_ SG_ 2365378048 DriveStrategyPriority3Req "This parameter used to request an alteration to the tractor drive strategy priority structure, which determines 
the  balance  between  fuel  economy/consumption  and  the  torque  reserve  of  the  engine - the third to highest priority request.";
CM_ SG_ 2365378048 DriveStrategyPriority4Req "This parameter used to request an alteration to the tractor drive strategy priority structure, which determines 
the  balance  between  fuel  economy/consumption  and  the  torque  reserve  of  the  engine - the lowest priority request.  ";
CM_ SG_ 2365378048 RestoreOpDriveStratSetReq "This parameter requests the drive strategy subsystem to restore the settings for drive strategy to the state 
before automation was ended. ";
CM_ BO_ 2566688510 "This message identifies all the functionalities, functionality generation and functionality options, supported by 
control functions.";
CM_ SG_ 2566688510 Functionality "This parameter reports which functionalities are supported by a control function connected to the ISO 11783 
network. ";
CM_ SG_ 2566688510 FunctionalityGeneration "This parameter reports the generation of the functionality provided by a control function connected to the ISO 11783 network.";
CM_ SG_ 2566688510 NumberOfOptionsBytes "This parameter reports the number of bytes that follow to report which options are supported by a functionality 
provided  by  a  control  function  connected  to  the  ISO  11783  network.";
CM_ BO_ 2566688254 "Product Identification Information: Each control function of a product shall respond with the same product identification information when it 
receives the Request PGN message for this PGN.";
CM_ SG_ 2566688254 ProductIdentificationCode "The Product Identification Code as assigned by the manufacturer correspondents with the number on the type 
plate of a product.";
CM_ SG_ 2566688254 ProductIdentificationBrand "Specifies  the  brand  of  a  product.  
The  combination  of  the  Product Identification Code and the Product Identification Brand shall make the product unique in the world.";
CM_ SG_ 2566688254 ProductIdentificationModel "The Product Identification Model specifies a unique product within a Brand. ";
BA_DEF_ SG_  "DDI" INT 0 65535;
BA_DEF_ BO_  "SingleFrame" INT 0 1;
BA_DEF_ BO_  "VFrameFormat" ENUM  "StandardCAN","ExtendedCAN","reserved","J1939PG","vector_leerstring";
BA_DEF_ BO_  "GenMsgSendType" ENUM  "cyclic","NotUsed","IfActive","NotUsed","NotUsed","NotUsed","NotUsed","NotUsed","noMsgSendType","vector_leerstring";
BA_DEF_ BO_  "GenMsgCycleTime" INT 0 3600000;
BA_DEF_ BO_  "GenMsgRequestable" INT 0 1;
BA_DEF_ BO_  "GenMsgCycleTimeFast" INT 0 3600000;
BA_DEF_ SG_  "SPN" INT 0 524287;
BA_DEF_ SG_  "GenSigSendType" ENUM  "Cyclic","OnWrite","OnWriteWithRepetition","OnChange","OnChangeWithRepetition","IfActive","IfActiveWithRepetition","NoSigSendType";
BA_DEF_ SG_  "SigType" ENUM  "Default","Range","RangeSigned","ASCII","Discrete","Control","ReferencePGN","DTC","StringDelimiter","StringLength","StringLengthControl","MessageCounter","MessageChecksum";
BA_DEF_ SG_  "GenSigStartValue" INT -2147483648 2147483647;
BA_DEF_ SG_  "SystemSignalLongSymbol" STRING ;
BA_DEF_DEF_  "DDI" 0;
BA_DEF_DEF_  "SingleFrame" 1;
BA_DEF_DEF_  "VFrameFormat" "J1939PG";
BA_DEF_DEF_  "GenMsgSendType" "noMsgSendType";
BA_DEF_DEF_  "GenMsgCycleTime" 0;
BA_DEF_DEF_  "GenMsgRequestable" 1;
BA_DEF_DEF_  "GenMsgCycleTimeFast" 0;
BA_DEF_DEF_  "SPN" 0;
BA_DEF_DEF_  "GenSigSendType" "NoSigSendType";
BA_DEF_DEF_  "SigType" "Default";
BA_DEF_DEF_  "GenSigStartValue" 0;
BA_DEF_DEF_  "SystemSignalLongSymbol" "";
BA_ "GenMsgCycleTime" BO_ 2566704384 500;
BA_ "GenMsgSendType" BO_ 2566704384 0;
BA_ "GenMsgCycleTimeFast" BO_ 2365378048 100;
BA_ "GenMsgCycleTime" BO_ 2365378048 500;
BA_ "GenMsgSendType" BO_ 2365378048 0;
BA_ "DDI" SG_ 2362179326 MinimumProductPressure 195;
BA_ "DDI" SG_ 2362179326 MaximumProductPressure 196;
BA_ "DDI" SG_ 2362179326 SetpointPumpOutputPressure 197;
BA_ "DDI" SG_ 2362179326 ActualPumpOutputPressure 198;
BA_ "DDI" SG_ 2362179326 MinimumPumpOutputPressure 199;
BA_ "DDI" SG_ 2362179326 MaximumPumpOutputPressure 200;
BA_ "DDI" SG_ 2362179326 SetpointTankAgitationPressure 201;
BA_ "DDI" SG_ 2362179326 ActualTankAgitationPressure 202;
BA_ "DDI" SG_ 2362179326 MinimumTankAgitationPressure 203;
BA_ "DDI" SG_ 2362179326 MaximumTankAgitationPressure 204;
BA_ "DDI" SG_ 2362179326 SCTurnOnTime_ 205;
BA_ "DDI" SG_ 2362179326 SCTurnOffTime 206;
BA_ "DDI" SG_ 2362179326 WindSpeed 207;
BA_ "DDI" SG_ 2362179326 WindDirection 208;
BA_ "DDI" SG_ 2362179326 AirHumidity 209;
BA_ "DDI" SG_ 2362179326 SkyConditions 210;
BA_ "DDI" SG_ 2362179326 LastBaleFlakesPerBale 211;
BA_ "DDI" SG_ 2362179326 LastBaleAverageMoisture 212;
BA_ "DDI" SG_ 2362179326 LastBaleAverageStrokesPerFlake 213;
BA_ "DDI" SG_ 2362179326 LifetimeBaleCount 214;
BA_ "DDI" SG_ 2362179326 LifetimeWorkingHours 215;
BA_ "DDI" SG_ 2362179326 ActualBaleHydraulicPressure 216;
BA_ "DDI" SG_ 2362179326 LastBaleAverageHydraulicPressure 217;
BA_ "DDI" SG_ 2362179326 SetpointBaleCompressionPlungerLo 218;
BA_ "SystemSignalLongSymbol" SG_ 2362179326 SetpointBaleCompressionPlungerLo "SetpointBaleCompressionPlungerLoad";
BA_ "DDI" SG_ 2362179326 ActualBaleCompressionPlungerLoad 219;
BA_ "DDI" SG_ 2362179326 LastBaleAverageBaleCompressionPl 220;
BA_ "SystemSignalLongSymbol" SG_ 2362179326 LastBaleAverageBaleCompressionPl "LastBaleAverageBaleCompressionPlungerLoad";
BA_ "DDI" SG_ 2362179326 LastBaleAppliedPreservative 221;
BA_ "DDI" SG_ 2362179326 LastBaleTagNumber 222;
BA_ "DDI" SG_ 2362179326 LastBaleMass 223;
BA_ "DDI" SG_ 2362179326 DeltaT 224;
BA_ "DDI" SG_ 2362179326 SetpointWorkingLength 225;
BA_ "DDI" SG_ 2362179326 ActualWorkingLength 226;
BA_ "DDI" SG_ 2362179326 MinimumWorkingLength 227;
BA_ "DDI" SG_ 2362179326 MaximumWorkingLength 228;
BA_ "DDI" SG_ 2362179326 ActualNetWeight 229;
BA_ "DDI" SG_ 2362179326 NetWeightState 230;
BA_ "DDI" SG_ 2362179326 SetpointNetWeight 231;
BA_ "DDI" SG_ 2362179326 ActualGrossWeight 232;
BA_ "DDI" SG_ 2362179326 GrossWeightState 233;
BA_ "DDI" SG_ 2362179326 MinimumGrossWeight 234;
BA_ "DDI" SG_ 2362179326 MaximumGrossWeight 235;
BA_ "DDI" SG_ 2362179326 ThreshingEngagementTotalTime 236;
BA_ "DDI" SG_ 2362179326 ActualHeaderWorkingHeightStatus 237;
BA_ "DDI" SG_ 2362179326 ActualHeaderRotationalSpeedStatu 238;
BA_ "SystemSignalLongSymbol" SG_ 2362179326 ActualHeaderRotationalSpeedStatu "ActualHeaderRotationalSpeedStatus";
BA_ "DDI" SG_ 2362179326 YieldHoldStatus 239;
BA_ "DDI" SG_ 2362179326 ActualUnLoadingSystemStatus 240;
BA_ "DDI" SG_ 2362179326 CropTemperature 241;
BA_ "DDI" SG_ 2362179326 SetpointSieveClearance 242;
BA_ "DDI" SG_ 2362179326 ActualSieveClearance 243;
BA_ "DDI" SG_ 2362179326 MinimumSieveClearance 244;
BA_ "DDI" SG_ 2362179326 MaximumSieveClearance 245;
BA_ "DDI" SG_ 2362179326 SetpointChafferClearance 246;
BA_ "DDI" SG_ 2362179326 ActualChafferClearance 247;
BA_ "DDI" SG_ 2362179326 MinimumChafferClearance 248;
BA_ "DDI" SG_ 2362179326 MaximumChafferClearance 249;
BA_ "DDI" SG_ 2362179326 SetpointConcaveClearance 250;
BA_ "DDI" SG_ 2362179326 ActualConcaveClearance 251;
BA_ "DDI" SG_ 2362179326 MinimumConcaveClearance 252;
BA_ "DDI" SG_ 2362179326 MaximumConcaveClearance 253;
BA_ "DDI" SG_ 2362179326 SetpointSeparationFanRotationalS 254;
BA_ "SystemSignalLongSymbol" SG_ 2362179326 SetpointSeparationFanRotationalS "SetpointSeparationFanRotationalSpeed";
BA_ "DDI" SG_ 2362179326 ActualSeparationFanRotationalSpe 255;
BA_ "SystemSignalLongSymbol" SG_ 2362179326 ActualSeparationFanRotationalSpe "ActualSeparationFanRotationalSpeed";
BA_ "DDI" SG_ 2362179326 MinimumSeparationFanRotationalSp 256;
BA_ "SystemSignalLongSymbol" SG_ 2362179326 MinimumSeparationFanRotationalSp "MinimumSeparationFanRotationalSpeed";
BA_ "DDI" SG_ 2362179326 MaximumSeparationFanRotationalSp 257;
BA_ "SystemSignalLongSymbol" SG_ 2362179326 MaximumSeparationFanRotationalSp "MaximumSeparationFanRotationalSpeed";
BA_ "DDI" SG_ 2362179326 HydraulicOilTemperature 258;
BA_ "DDI" SG_ 2362179326 YieldLagIgnoreTime 259;
BA_ "DDI" SG_ 2362179326 YieldLeadIgnoreTime 260;
BA_ "DDI" SG_ 2362179326 AverageYieldMassPerTime 261;
BA_ "DDI" SG_ 2362179326 AverageCropMoisture 262;
BA_ "DDI" SG_ 2362179326 AverageYieldMassPerArea 263;
BA_ "DDI" SG_ 2362179326 ConnectorPivotXOffset 264;
BA_ "DDI" SG_ 2362179326 RemainingArea 265;
BA_ "DDI" SG_ 2362179326 LifetimeApplicationTotalMass 266;
BA_ "DDI" SG_ 2362179326 LifetimeApplicationTotalCount 267;
BA_ "DDI" SG_ 2362179326 LifetimeYieldTotalVolume 268;
BA_ "DDI" SG_ 2362179326 LifetimeYieldTotalMass 269;
BA_ "DDI" SG_ 2362179326 LifetimeYieldTotalCount 270;
BA_ "DDI" SG_ 2362179326 LifetimeTotalArea 271;
BA_ "DDI" SG_ 2362179326 LifetimeTotalDistance 272;
BA_ "DDI" SG_ 2362179326 LifetimeIneffectiveTotalDistance 273;
BA_ "DDI" SG_ 2362179326 LifetimeEffectiveTotalTime 274;
BA_ "DDI" SG_ 2362179326 LifetimeIneffectiveTotalTime 275;
BA_ "DDI" SG_ 2362179326 LifetimeFuelConsumption 276;
BA_ "DDI" SG_ 2362179326 LifetimeAverageFuelConsumptionPe 277;
BA_ "SystemSignalLongSymbol" SG_ 2362179326 LifetimeAverageFuelConsumptionPe "LifetimeAverageFuelConsumptionPerTime";
BA_ "DDI" SG_ 2362179326 LifetimeAverageFuelConsumpt_0000 278;
BA_ "SystemSignalLongSymbol" SG_ 2362179326 LifetimeAverageFuelConsumpt_0000 "LifetimeAverageFuelConsumptionPerArea";
BA_ "DDI" SG_ 2362179326 LifetimeYieldTotalDryMass 279;
BA_ "DDI" SG_ 2362179326 LifetimeYieldTotalSeedCottonMass 280;
BA_ "DDI" SG_ 2362179326 LifetimeYieldTotalLintCottonMass 281;
BA_ "DDI" SG_ 2362179326 LifetimeThreshingEngagementTotal 282;
BA_ "SystemSignalLongSymbol" SG_ 2362179326 LifetimeThreshingEngagementTotal "LifetimeThreshingEngagementTotalTime";
BA_ "DDI" SG_ 2362179326 PrecutTotalCount 283;
BA_ "DDI" SG_ 2362179326 UncutTotalCount 284;
BA_ "DDI" SG_ 2362179326 LifetimePrecutTotalCount 285;
BA_ "DDI" SG_ 2362179326 LifetimeUncutTotalCount 286;
BA_ "DDI" SG_ 2362179326 SetpointWorkState 289;
BA_ "DDI" SG_ 2362179326 SetpointCondensedWorkState1to16 290;
BA_ "DDI" SG_ 2362179326 SetpointCondensedWorkState17to32 291;
BA_ "DDI" SG_ 2362179326 SetpointCondensedWorkState33to48 292;
BA_ "DDI" SG_ 2362179326 SetpointCondensedWorkState49to64 293;
BA_ "DDI" SG_ 2362179326 SetpointCondensedWorkState65to80 294;
BA_ "DDI" SG_ 2362179326 SetpointCondensedWorkState81to96 295;
BA_ "DDI" SG_ 2362179326 SetpointCondensedWorkState97to11 296;
BA_ "SystemSignalLongSymbol" SG_ 2362179326 SetpointCondensedWorkState97to11 "SetpointCondensedWorkState97to112";
BA_ "DDI" SG_ 2362179326 SetpointCondensedWorkState113to1 297;
BA_ "SystemSignalLongSymbol" SG_ 2362179326 SetpointCondensedWorkState113to1 "SetpointCondensedWorkState113to128";
BA_ "DDI" SG_ 2362179326 SetpointCondensedWorkState129to1 298;
BA_ "SystemSignalLongSymbol" SG_ 2362179326 SetpointCondensedWorkState129to1 "SetpointCondensedWorkState129to144";
BA_ "DDI" SG_ 2362179326 SetpointCondensedWorkState145to1 299;
BA_ "SystemSignalLongSymbol" SG_ 2362179326 SetpointCondensedWorkState145to1 "SetpointCondensedWorkState145to160";
BA_ "DDI" SG_ 2362179326 SetpointCondensedWorkState161to1 300;
BA_ "SystemSignalLongSymbol" SG_ 2362179326 SetpointCondensedWorkState161to1 "SetpointCondensedWorkState161to176";
BA_ "DDI" SG_ 2362179326 SetpointCondensedWorkState177to1 301;
BA_ "SystemSignalLongSymbol" SG_ 2362179326 SetpointCondensedWorkState177to1 "SetpointCondensedWorkState177to192";
BA_ "DDI" SG_ 2362179326 SetpointCondensedWorkState193to2 302;
BA_ "SystemSignalLongSymbol" SG_ 2362179326 SetpointCondensedWorkState193to2 "SetpointCondensedWorkState193to208";
BA_ "DDI" SG_ 2362179326 SetpointCondensedWorkState209to2 303;
BA_ "SystemSignalLongSymbol" SG_ 2362179326 SetpointCondensedWorkState209to2 "SetpointCondensedWorkState209to224";
BA_ "DDI" SG_ 2362179326 SetpointCondensedWorkState225to2 304;
BA_ "SystemSignalLongSymbol" SG_ 2362179326 SetpointCondensedWorkState225to2 "SetpointCondensedWorkState225to240";
BA_ "DDI" SG_ 2362179326 SetpointCondensedWorkState241to2 305;
BA_ "SystemSignalLongSymbol" SG_ 2362179326 SetpointCondensedWorkState241to2 "SetpointCondensedWorkState241to256";
BA_ "DDI" SG_ 2362179326 TrueRotationPointXOffset 306;
BA_ "DDI" SG_ 2362179326 TrueRotationPointYOffset 307;
BA_ "DDI" SG_ 2362179326 ActualPercentageApplicationRate 308;
BA_ "DDI" SG_ 2362179326 MinimumPercentageApplicationRate 309;
BA_ "DDI" SG_ 2362179326 MaximumPercentageApplicationRate 310;
BA_ "DDI" SG_ 2362179326 RelativeYieldPotential 311;
BA_ "DDI" SG_ 2362179326 MinimumRelativeYieldPotential 312;
BA_ "DDI" SG_ 2362179326 MaximumRelativeYieldPotential 313;
BA_ "DDI" SG_ 2362179326 ActualPercentageCropDryMatter 314;
BA_ "DDI" SG_ 2362179326 AveragePercentageCropDryMatter 315;
BA_ "DDI" SG_ 2362179326 EffectiveTotalFuelConsumption 316;
BA_ "DDI" SG_ 2362179326 IneffectiveTotalFuelConsumption 317;
BA_ "DDI" SG_ 2362179326 EffectiveTotalDieselExhaustFluid 318;
BA_ "SystemSignalLongSymbol" SG_ 2362179326 EffectiveTotalDieselExhaustFluid "EffectiveTotalDieselExhaustFluidConsumption";
BA_ "DDI" SG_ 2362179326 IneffectiveTotalDieselExhaustFlu 319;
BA_ "SystemSignalLongSymbol" SG_ 2362179326 IneffectiveTotalDieselExhaustFlu "IneffectiveTotalDieselExhaustFluidConsumption";
BA_ "DDI" SG_ 2362179326 LastLoadedWeight 320;
BA_ "DDI" SG_ 2362179326 LastUnloadedWeight 321;
BA_ "DDI" SG_ 2362179326 PGNBasedData 57342;
BA_ "DDI" SG_ 2362179326 RequestDefaultProcessData 57343;
BA_ "SPN" SG_ 2362179326 DateFormatCmd 2412;
BA_ "SigType" SG_ 2362179326 DateFormatCmd 1;
BA_ "SPN" SG_ 2362179326 DecimalSymbolCmd 2411;
BA_ "SigType" SG_ 2362179326 DecimalSymbolCmd 4;
BA_ "SPN" SG_ 2362179326 TimeFormatCmd 2413;
BA_ "SigType" SG_ 2362179326 TimeFormatCmd 4;
BA_ "GenSigStartValue" SG_ 2362179326 ImplementSectionControl 1;
BA_ "GenSigStartValue" SG_ 2362179326 PeerControlAssignment 1;
BA_ "GenSigStartValue" SG_ 2362179326 TC_GEO_DefinitionPositionBasedCo 1;
BA_ "SystemSignalLongSymbol" SG_ 2362179326 TC_GEO_DefinitionPositionBasedCo "TC_GEO_DefinitionPositionBasedControl";
BA_ "GenSigStartValue" SG_ 2362179326 TimeAndPositionForDataLogging 1;
BA_ "GenSigStartValue" SG_ 2362179326 Documentation 1;
BA_ "GenSigStartValue" SG_ 2362179326 BootTimeTC 255;
BA_ "SPN" SG_ 2362179326 LanguageCodeCmd 2410;
BA_ "SigType" SG_ 2362179326 LanguageCodeCmd 3;
BA_ "GenSigStartValue" SG_ 2362179326 NumberOfControlChannels 255;
BA_ "SPN" SG_ 2565799678 ArbitraryAddressCapable 2844;
BA_ "SPN" SG_ 2565799678 IndustryGroup 2846;
BA_ "SPN" SG_ 2565799678 VehicleSystemInstance 2843;
BA_ "SPN" SG_ 2565799678 Function 2841;
BA_ "SPN" SG_ 2565799678 FunctionInstance 2839;
BA_ "SPN" SG_ 2565799678 ECUInstance 2840;
BA_ "SigType" SG_ 2565799678 ManufacturerCode 1;
BA_ "SPN" SG_ 2565799678 ManufacturerCode 2838;
BA_ "SPN" SG_ 2565799678 IdentityNumber 2837;
BA_ "SigType" SG_ 2566838526 AddressAssignment 1;
BA_ "SPN" SG_ 2566838526 AddressAssignment 2847;
BA_ "SPN" SG_ 2566838526 ArbitraryAddressCapable 2844;
BA_ "SPN" SG_ 2566838526 IndustryGroup 2846;
BA_ "SPN" SG_ 2566838526 VehicleSystemInstance 2843;
BA_ "SPN" SG_ 2566838526 Function 2841;
BA_ "SPN" SG_ 2566838526 FunctionInstance 2839;
BA_ "SPN" SG_ 2566838526 ECUInstance 2840;
BA_ "SigType" SG_ 2566838526 ManufacturerCode 1;
BA_ "SPN" SG_ 2566838526 ManufacturerCode 2838;
BA_ "SPN" SG_ 2566838526 IdentityNumber 2837;
BA_ "SPN" SG_ 2566768126 ECUManufacturerName 4304;
BA_ "SigType" SG_ 2566768126 ECUManufacturerName 8;
BA_ "SigType" SG_ 2566768126 ECUType 8;
BA_ "SPN" SG_ 2566768126 ECUType 2904;
BA_ "SigType" SG_ 2566768126 ECULocation 8;
BA_ "SPN" SG_ 2566768126 ECULocation 2903;
BA_ "SigType" SG_ 2566768126 ECUSerialNumber 8;
BA_ "SPN" SG_ 2566768126 ECUSerialNumber 2902;
BA_ "SigType" SG_ 2566768126 ECUPartNumber 8;
BA_ "SPN" SG_ 2566768126 ECUPartNumber 2901;
BA_ "SigType" SG_ 2566768126 ECUHardwareVersionIdentification 8;
BA_ "SigType" SG_ 2566839038 SoftwareID3 8;
BA_ "SPN" SG_ 2566839038 SoftwareID3 234;
BA_ "SigType" SG_ 2566839038 SoftwareID2 8;
BA_ "SPN" SG_ 2566839038 SoftwareID2 234;
BA_ "SigType" SG_ 2566839038 SoftwareID1 8;
BA_ "SPN" SG_ 2566839038 SoftwareID1 234;
BA_ "SigType" SG_ 2566839038 NmbrOfSftwreIdentificationFields 1;
BA_ "SPN" SG_ 2566839038 NmbrOfSftwreIdentificationFields 965;
BA_ "SigType" SG_ 2566834942 DTC5 7;
BA_ "SigType" SG_ 2566834942 DTC4 7;
BA_ "SigType" SG_ 2566834942 DTC3 7;
BA_ "SigType" SG_ 2566834942 DTC2 7;
BA_ "SigType" SG_ 2566834942 DTC1 7;
BA_ "SigType" SG_ 2566835198 DTC5 7;
BA_ "SigType" SG_ 2566835198 DTC4 7;
BA_ "SigType" SG_ 2566835198 DTC3 7;
BA_ "SigType" SG_ 2566835198 DTC2 7;
BA_ "SigType" SG_ 2566835198 DTC1 7;
BA_ "SPN" SG_ 2566734590 CertLaboratoryType_FirstDef 4315;
BA_ "SPN" SG_ 2566734590 MessageRevision 7446;
BA_ "SPN" SG_ 2566734590 CertificationReferenceNumber 4330;
BA_ "SPN" SG_ 2566734590 CertTypeTaskController 4325;
BA_ "SPN" SG_ 2566734590 CertTypeTCWorkingSetMaster 4326;
BA_ "SPN" SG_ 2566734590 CertTypeTCWorkingSetMember 4327;
BA_ "SPN" SG_ 2566734590 CertTypeFileServer 4328;
BA_ "SPN" SG_ 2566734590 CertTypeGPSReceiver 4329;
BA_ "SPN" SG_ 2566734590 CertTypeMinimumECU 4317;
BA_ "SPN" SG_ 2566734590 CertTypeTECUClass1 4318;
BA_ "SPN" SG_ 2566734590 CertTypeTECUClass2 4319;
BA_ "SPN" SG_ 2566734590 CertTypeTECUClass3 4320;
BA_ "SPN" SG_ 2566734590 CertTypeClass3ECU 4321;
BA_ "SPN" SG_ 2566734590 CertTypeVirtualTerminal 4322;
BA_ "SPN" SG_ 2566734590 CertTypeVTWorkingSetMaster 4323;
BA_ "SPN" SG_ 2566734590 CertTypeVTWorkingSetMember 4324;
BA_ "SPN" SG_ 2566734590 CertificationLaboratoryID 4316;
BA_ "SPN" SG_ 2566734590 CertLaboratoryType_SecondDef 4315;
BA_ "SPN" SG_ 2566734590 TestProtocolRevision 4314;
BA_ "SPN" SG_ 2566734590 TestProtocolPublicationYear 4313;
BA_ "SPN" SG_ 2365391616 ImplementOperatingStateCmd 5139;
BA_ "SPN" SG_ 2365391614 StopAllImplOpTransitionNum 7443;
BA_ "SPN" SG_ 2365391614 StopAllImplOpSwitchState 5140;
BA_ "SystemSignalLongSymbol" SG_ 2559835902 VehicleSystemInstanceQualifierFl "VehicleSystemInstanceQualifierFlag";
BA_ "SystemSignalLongSymbol" SG_ 2559835902 ArbitraryAddressCapableQualifier "ArbitraryAddressCapableQualifierFlag";
BA_ "SigType" SG_ 2566843646 VehicleIdentificationNumber 8;
BA_ "SPN" SG_ 2566843646 VehicleIdentificationNumber 237;
BA_ "SPN" SG_ 2566704384 DriveStrategyExitReason 5732;
BA_ "SPN" SG_ 2566704384 DriveStrategyPriority1 5727;
BA_ "SPN" SG_ 2566704384 DriveStrategyPriority2 5728;
BA_ "SPN" SG_ 2566704384 DriveStrategyPriority3 5729;
BA_ "SPN" SG_ 2566704384 DriveStrategyPriority4 5730;
BA_ "SPN" SG_ 2566704384 DriveStrategyRequestState 5731;
BA_ "SPN" SG_ 2365378048 DriveStrategyPriority1Req 5733;
BA_ "SPN" SG_ 2365378048 DriveStrategyPriority2Req 5734;
BA_ "SPN" SG_ 2365378048 DriveStrategyPriority3Req 5735;
BA_ "SPN" SG_ 2365378048 DriveStrategyPriority4Req 5736;
BA_ "SPN" SG_ 2365378048 RestoreOpDriveStratSetReq 5737;
BA_ "GenSigStartValue" SG_ 2566688510 NumberOfFunctionalities 1;
BA_ "GenSigStartValue" SG_ 2566688510 FunctionalityGeneration 1;
BA_ "SPN" SG_ 2566688254 ProductIdentificationCode 6699;
BA_ "SigType" SG_ 2566688254 ProductIdentificationCode 8;
BA_ "SPN" SG_ 2566688254 ProductIdentificationBrand 6701;
BA_ "SigType" SG_ 2566688254 ProductIdentificationBrand 8;
BA_ "SPN" SG_ 2566688254 ProductIdentificationModel 6701;
BA_ "SigType" SG_ 2566688254 ProductIdentificationModel 8;
VAL_ 2362179326 ErrorCodeProcessData1 1 "CommandNotSupported" 0 "NoError" ;
VAL_ 2362179326 DateFormatCmd 5 "yyyyddmm" 4 "yyyymmdd" 3 "mmddyyyy" 2 "mmyyyydd" 1 "ddyyyymm" 0 "ddmmyyyy" ;
VAL_ 2362179326 PeerControlCommand 0 "Assign Receiver" 1 "UnassignReceiver" 2 "Receiver Ackowledge" 3 "Assign Transmitter" 4 "UnassignTransmitter" 5 "Transmitter Acknowledge" ;
VAL_ 2362179326 DecimalSymbolCmd 3 "NoAction" 1 "PointIsUsed" 0 "CommaIsUsed" ;
VAL_ 2362179326 TimeFormatCmd 3 "NoAction" 1 "Hour12" 0 "Hour24" ;
VAL_ 2362179326 ImplementSectionControl 0 "NotSupported" 1 "Supported" ;
VAL_ 2362179326 PeerControlAssignment 0 "NotSupported" 1 "Supported" ;
VAL_ 2362179326 TC_GEO_DefinitionPositionBasedCo 0 "NotSupported" 1 "Supported" ;
VAL_ 2362179326 TimeAndPositionForDataLogging 0 "NotSupported" 1 "Supported" ;
VAL_ 2362179326 Documentation 0 "NotSupported" 1 "Supported" ;
VAL_ 2362179326 ErrorCodeChangeDesignator 0 "Success" 1 "Error" ;
VAL_ 2362179326 ErrorDetailObjectPoolDelete 255 "NotAvailable" 1 "ServerCannotCheckObjectPoolRef" 0 "ObjectPoolIsReferencedByTaskData" ;
VAL_ 2362179326 DDI 57343 "RequestDefaultProcessData" 57342 "PGNBasedData" 521 "GNSSInstallationType" 520 "ActualCanopyHeight" 519 "LastBaleLifetimeCount" 518 "ActualTramlineCondensedWorkState1to16" 517 "SetpointTramlineCondensedWorkState1to16" 516 "TramlineOverdosingRate" 515 "TramlineControlState" 514 "GNSSQuality" 513 "GuidanceLineDeviation" 512 "GuidanceLineSwathWidth" 511 "TrackNumberToTheLeft" 510 "TrackNumberToTheRight" 509 "ActualTrackNumber" 508 "UniqueABGuidanceReferenceLineID" 507 "TramlineSequenceNumber" 506 "SetpointTramlineControlLevel" 505 "TramlineControlLevel" 504 "MaximumEngineTorque" 503 "MinimumEngineTorque" 502 "ActualEngineTorque" 501 "SetpointEngineTorque" 500 "LastEventPartnerIDDeviceClass" 499 "LastEventPartnerIDManufacturerIDCode" 498 "LastEventPartnerIDType" 497 "LastEventPartnerID_Byte13to16" 496 "LastEventPartnerID_Byte9to12" 495 "LastEventPartnerID_Byte5to8" 494 "LastEventPartnerID_Byte1to4" 493 "LifetimeEngineHours" 492 "TotalEngineHours" 491 "FuelPercentageLevel" 490 "MaximumFuelTankContent" 489 "MaximumDieselExhaustFluidTankContent" 488 "DieselExhaustFluidTankPercentageLevel" 486 "MaximumEngineSpeed" 485 "MinimumEngineSpeed" 484 "ActualEngineSpeed" 483 "SetpointEngineSpeed" 482 "LastBaleNumberofSubbales" 481 "SetpointNumberofSubbales" 480 "MaximumFlakeSize" 479 "MinimumFlakeSize" 478 "SetpointFlakeSize" 477 "MaximumBaleHydraulicPressure" 476 "MinimumBaleHydraulicPressure" 475 "SetpointBaleHydraulicPressure" 474 "MaximumLengthofCut" 473 "Minimumlengthofcut" 472 "SetpointLengthofCut" 467 "ActualPercentageContent" 466 "Actualrelativeconnectorangle" 465 "LifetimeHaulCounter" 464 "HaulCounter" 463 "LastunloadedCount" 462 "LastloadedCount" 461 "LifetimeUnloadedTotalCount" 460 "LifetimeLoadedTotalCount" 459 "UnloadedTotalCount" 458 "LoadedTotalCount" 457 "LastunloadedVolume" 456 "LastloadedVolume" 455 "LifetimeUnloadedTotalVolume" 454 "LifetimeloadedTotalVolume" 453 "UnloadedTotalVolume" 452 "LoadedTotalVolume" 451 "MaximumApplicationRateofDryMatter" 450 "MinimumApplicationRateofDryMatter" 449 "ActualApplicationRateofDryMatter" 448 "SetpointApplicationRateofDryMatter" 447 "MaximumApplicationRateofPotassium" 446 "MinimumApplicationRateofPotassium" 445 "ActualApplicationRateofPotassium" 444 "SetpointApplicationRateofPotassium" 443 "MaximumApplicationRateofPhosphor" 442 "MinimumApplicationRateofPhosphor" 441 "ActualApplicationRateofPhosphor" 440 "SetpointApplicationRateofPhosphor" 439 "MaximumApplicationRateofAmmonium" 438 "MinimumApplicationRateofAmmonium" 437 "ActualApplicationRateofAmmonium" 436 "SetpointApplicationRateofAmmonium" 435 "MaximumApplicationRateofNitrogen" 434 "MinimumApplicationRateofNitrogen" 433 "ActualApplicationRateofNitrogen" 432 "SetpointApplicationRateofNitrogen" 431 "LifetimeUnloadedTotalMass" 430 "LifetimeLoadedTotalMass" 429 "UnloadedTotalMass" 428 "LoadedTotalMass" 427 "ActualDownforceasForce" 426 "SetpointDownforceasForce" 425 "SetpointMaximumAllowedSeedSpacingDeviation" 424 "AverageCoefficientofVariationofSeedSpacingPercentage" 423 "ActualCoefficientofVariationofSeedSpacingPercentage" 422 "AverageSeedSpacingDeviation" 421 "ActualSeedSpacingDeviation" 420 "AverageSeedMultiplePercentage" 419 "ActualSeedMultiplePercentage" 418 "AverageSeedSkipPercentage" 417 "ActualSeedSkipPercentage" 416 "AverageSeedSingulationPercentage" 415 "ActualSeedSingulationPercentage" 414 "LifetimeAverageDieselExhaustFluidConsumptionperArea" 413 "LifetimeAverageDieselExhaustFluidConsumptionperTime" 412 "LifetimeDieselExhaustFluidConsumption" 411 "InstantaneousDieselExhaustFluidConsumptionperArea" 410 "InstantaneousDieselExhaustFluidConsumptionperTime" 409 "TotalDieselExhaustFluidConsumption" 408 "AverageCropContamination" 407 "AverageProteinContent" 406 "ActualProteinContent" 405 "ActualapplicationofDryMatter" 404 "ActualapplicationofPotassium" 403 "ActualapplicationofPhosphor" 402 "ActualapplicationofAmmonium" 401 "ActualApplicationofNitrogen" 400 "SpeedSource" 399 "MaximumSpeed" 398 "MinimumSpeed" 397 "ActualSpeed" 396 "SetpointSpeed" 395 "ActualDieselExhaustFluidTankContent" 394 "ActualFuelTankContent" 393 "MaximumRevolutionsPerTime" 392 "MinimumRevolutionsPerTime" 391 "DefaultRevolutionsPerTime" 390 "ActualRevolutionsPerTime" 389 "SetpointRevolutionsspecifiedascountpertime" 388 "TotalRevolutionsinCompleteRevolutions" 387 "TotalRevolutionsinFractionalRevolutions" 386 "ActualAtmosphericPressure" 385 "MSLAtmosphericPressure" 384 "ApparentWindSpeed" 383 "ApparentWindDirection" 382 "CondensedSectionOverrideState241to256" 381 "CondensedSectionOverrideState225to240" 380 "CondensedSectionOverrideState209to224" 379 "CondensedSectionOverrideState193to208" 378 "CondensedSectionOverrideState177to192" 377 "CondensedSectionOverrideState161to176" 376 "CondensedSectionOverrideState145to160" 375 "CondensedSectionOverrideState129to144" 374 "CondensedSectionOverrideState113to128" 373 "CondensedSectionOverrideState97to112" 372 "CondensedSectionOverrideState81to96" 371 "CondensedSectionOverrideState65to80" 370 "CondensedSectionOverrideState49to64" 369 "CondensedSectionOverrideState33to48" 368 "CondensedSectionOverrideState17to32" 367 "CondensedSectionOverrideState1to16" 366 "ActualDownforcePressure" 365 "SetpointDownforcePressure" 364 "ActualFlakeSize" 363 "LastBaleDryMass" 362 "TotalBaleLength" 361 "LastBaleDensity" 360 "LastBaleSize" 359 "AverageDryYieldMassPerArea" 358 "AverageDryYieldMassPerTime" 357 "TotalApplicationofDryMatter" 356 "TotalApplicationofPotassium" 355 "TotalApplicationofPhosphor" 354 "TotalApplicationofAmmonium" 353 "TotalApplicationofNitrogen" 352 "ApplicationTotalMassingram[g]" 351 "ApplicationTotalVolumein[ml]" 350 "FunctionorOperationTechnique" 349 "NozzleDriftReduction" 348 "MaximumSwathingWidth" 347 "MinimumSwathingWidth" 346 "ActualSwathingWidth" 345 "SetpointSwathingWidth" 344 "MaximumGrainKernelCrackerGap" 343 "MinimumGrainKernelCrackerGap" 342 "ActualGrainKernelCrackerGap" 341 "SetpointGrainKernelCrackerGap" 340 "EffectiveTotalUnloadingTime" 339 "EffectiveTotalLoadingTime" 338 "LifetimeRearPTOHours" 337 "LifetimeFrontPTOhours" 336 "RearPTOhours" 335 "FrontPTOhours" 334 "OperatingHoursSinceLastSharpening" 333 "MaximumCuttingdrumspeed" 332 "MinimumCuttingdrumspeed" 331 "ActualCuttingdrumspeed" 330 "SetpointCuttingdrumspeed" 329 "MaximumHeaderSpeed" 328 "MinimumHeaderSpeed" 327 "ActualHeaderSpeed" 326 "SetpointHeaderSpeed" 325 "LifetimeApplicationTotalVolume" 324 "ChopperEngagementTotalTime" 323 "UnloadIdentificationNumber" 322 "LoadIdentificationNumber" 321 "LastunloadedWeight" 320 "LastloadedWeight" 319 "IneffectiveTotalDieselExhaustFluidConsumption" 318 "EffectiveTotalDieselExhaustFluidConsumption" 317 "IneffectiveTotalFuelConsumption" 316 "EffectiveTotalFuelConsumption" 315 "AveragePercentageCropDryMatter" 314 "ActualPercentageCropDryMatter" 313 "MaximumRelativeYieldPotential" 312 "MinimumRelativeYieldPotential" 311 "RelativeYieldPotential" 310 "MaximumPercentageApplicationRate" 309 "MinimumPercentageApplicationRate" 308 "ActualPercentageApplicationRate" 307 "TrueRotationPointYtoOffset" 306 "TrueRotationPointXtoOffset" 305 "SetpointCondensedWorkState241to256" 304 "SetpointCondensedWorkState225to240" 303 "SetpointCondensedWorkState209to224" 302 "SetpointCondensedWorkState193to208" 301 "SetpointCondensedWorkState177to192" 300 "SetpointCondensedWorkState161to176" 299 "SetpointCondensedWorkState145to160" 298 "SetpointCondensedWorkState129to144" 297 "SetpointCondensedWorkState113to128" 296 "SetpointCondensedWorkState97to112" 295 "SetpointCondensedWorkState81to96" 294 "SetpointCondensedWorkState65to80" 293 "SetpointCondensedWorkState49to64" 292 "SetpointCondensedWorkState33to48" 291 "SetpointCondensedWorkState17to32" 290 "SetpointCondensedWorkState1to16" 289 "SetpointWorkState" 288 "ActualPrescriptionMode" 287 "SetpointPrescriptionMode" 286 "LifetimeUncutTotalCount" 285 "LifetimePrecutTotalCount" 284 "UncutTotalCount" 283 "PrecutTotalCount" 282 "LifetimeThreshingEngagementTotalTime" 281 "LifetimeYieldTotalLintCottonMass" 280 "LifetimeYieldTotalSeedCottonMass" 279 "LifetimeYieldTotalDryMass" 278 "LifetimeAverageFuelConsumptionperArea" 277 "LifetimeAverageFuelConsumptionperTime" 276 "LifetimeFuelConsumption" 275 "LifetimeIneffectiveTotalTime" 274 "LifetimeEffectiveTotalTime" 273 "LifetimeIneffectiveTotalDistance" 272 "LifetimeEffectiveTotalDistance" 271 "LifetimeTotalArea" 270 "LifetimeYieldTotalCount" 269 "LifetimeYieldTotalMass" 268 "LifetimeYieldTotalVolume" 267 "LifetimeApplicationTotalCount" 266 "LifetimeApplicationTotalMass" 265 "RemainingArea" 264 "ConnectorPivotXtoOffset" 263 "AverageYieldMassPerArea" 262 "AverageCropMoisture" 261 "AverageYieldMassPerTime" 260 "YieldLeadIgnoreTime" 259 "YieldLagIgnoreTime" 258 "HydraulicOilTemperature" 257 "MaximumSeparationFanRotationalSpeed" 256 "MinimumSeparationFanRotationalSpeed" 255 "ActualSeparationFanRotationalSpeed" 254 "SetpointSeparationFanRotationalSpeed" 253 "MaximumConcaveClearance" 252 "MinimumConcaveClearance" 251 "ActualConcaveClearance" 250 "SetpointConcaveClearance" 249 "MaximumChafferClearance" 248 "MinimumChafferClearance" 247 "ActualChafferClearance" 246 "SetpointChafferClearance" 245 "MaximumSieveClearance" 244 "MinimumSieveClearance" 243 "ActualSieveClearance" 242 "SetpointSieveClearance" 241 "CropTemperature" 240 "ActualUnLoadingSystemStatus" 239 "YieldHoldStatus" 238 "ActualHeaderRotationalSpeedStatus" 237 "ActualHeaderWorkingHeightStatus" 236 "ThresherEngagementTotalTime" 235 "MaximumGrossWeight" 234 "MinimumGrossWeight" 233 "GrossWeightState" 232 "ActualGrossWeight" 231 "SetpointNetWeight" 230 "NetWeightState" 229 "ActualNetWeight" 228 "MaximumWorkingLength" 227 "MinimumWorkingLength" 226 "ActualWorkingLength" 225 "SetpointWorkingLength" 224 "DeltaT" 223 "LastBaleMass" 222 "LastBaleTagNumber" 221 "LastBaleAppliedPreservative" 220 "LastBaleAverageBaleCompressionPlungerLoad" 219 "ActualBaleCompressionPlungerLoad" 218 "SetpointBaleCompressionPlungerLoad" 217 "LastBaleAverageHydraulicPressure" 216 "ActualBaleHydraulicPressure" 215 "LifetimeWorkingHours" 214 "LifetimeBaleCount" 213 "LastBaleAverageStrokesperFlake" 212 "LastBaleAverageMoisture" 211 "LastBaleFlakesperBale" 210 "Skyconditions" 209 "AirHumidity" 208 "Winddirection" 207 "Windspeed" 206 "SCTurnOffTime" 205 "SCTurnOnTime" 204 "MaximumTankAgitationPressure" 203 "MinimumTankAgitationPressure" 202 "ActualTankAgitationPressure" 201 "SetpointTankAgitationPressure" 200 "MaximumPumpOutputPressure" 199 "MinimumPumpOutputPressure" 198 "ActualPumpOutputPressure" 197 "SetpointPumpOutputPressure" 196 "MaximumProductPressure" 195 "MinimumProductPressure" 194 "ActualProductPressure" 193 "SetpointProductPressure" 192 "Ambienttemperature" 191 "LintTurnoutPercentage" 190 "YieldTotalLintCottonMass" 189 "YieldTotalSeedCottonMass" 188 "LintCottonMassPerTimeYield" 187 "SeedCottonMassPerTimeYield" 186 "LintCottonMassPerAreaYield" 185 "SeedCottonMassPerAreaYield" 184 "ReferenceMoistureForDryMass" 183 "YieldTotalDryMass" 182 "DryMassPerTimeYield" 181 "DryMassPerAreaYield" 180 "DeviceReferencePointDRPtoGrounddistance" 179 "ActualCulturalPractice" 178 "ElementTypeInstance" 177 "Actuallengthofcut" 176 "ActualCondensedWorkState241to256" 175 "ActualCondensedWorkState225to240" 174 "ActualCondensedWorkState209to224" 173 "ActualCondensedWorkState193to208" 172 "ActualCondensedWorkState177to192" 171 "ActualCondensedWorkState161to176" 170 "ActualCondensedWorkState145to160" 169 "ActualCondensedWorkState129to144" 168 "ActualCondensedWorkState113to128" 167 "ActualCondensedWorkState97to112" 166 "ActualCondensedWorkState81to96" 165 "ActualCondensedWorkState65to80" 164 "ActualCondensedWorkState49to64" 163 "ActualCondensedWorkState33to48" 162 "ActualCondensedWorkState17to32" 161 "ActualCondensedWorkState1to16" 160 "SectionControlState" 159 "NumberofSubtoUnitsperSection" 158 "PrescriptionControlState" 157 "ConnectorType" 156 "PhysicalObjectHeight" 155 "PhysicalObjectWidth" 154 "PhysicalObjectLength" 153 "ActualNormalizedDifferenceVegetativeIndexNDVI" 151 "InstantaneousAreaPerTimeCapacity" 150 "InstantaneousFuelConsumptionperArea" 149 "InstantaneousFuelConsumptionperTime" 148 "TotalFuelConsumption" 147 "LogCount" 146 "PitchAngle" 145 "RollAngle" 144 "YawAngle" 143 "PhysicalActualValueTimeLatency" 142 "PhysicalSetpointTimeLatency" 141 "ActualWorkState" 140 "SetpointPercentageApplicationRate" 139 "DeviceCountCapacity" 138 "DeviceMassCapacity" 137 "DeviceVolumeCapacity" 136 "DeviceElementOffsetZ" 135 "DeviceElementOffsetY" 134 "DeviceElementOffsetX" 133 "AuxiliaryValveInvertPorts" 132 "AuxiliaryValveProgressivityRetract" 131 "AuxiliaryValveProgressivityExtend" 130 "AuxiliaryValveFloatThreshold" 129 "AuxiliaryValveRampRetractDown" 128 "AuxiliaryValveRampRetractUp" 127 "AuxiliaryValveRampExtendDown" 126 "AuxiliaryValveRampExtendUp" 125 "AuxiliaryValveScalingRetract" 124 "AuxiliaryValveScalingExtend" 123 "ProductDensityVolumePerCount" 122 "ProductDensityMassPerCount" 121 "ProductDensityMassPerVolume" 120 "IneffectiveTotalTime" 119 "EffectiveTotalTime" 118 "IneffectiveTotalDistance" 117 "EffectiveTotalDistance" 116 "TotalArea" 115 "MaximumBaleSize" 114 "MinimumBaleSize" 113 "DefaultBaleSize" 112 "ActualBaleSize" 111 "SetpointBaleSize" 110 "MaximumBaleHeight" 109 "MinimumBaleHeight" 108 "DefaultBaleHeight" 107 "ActualBaleHeight" 106 "SetpointBaleHeight" 105 "MaximumBaleWidth" 104 "MinimumBaleWidth" 103 "DefaultBaleWidth" 102 "ActualBaleWidth" 101 "SetpointBaleWidth" 100 "CropContamination" 99 "CropMoisture" 98 "PercentageCropLoss" 97 "CountPerTimeCropLoss" 96 "MassPerTimeCropLoss" 95 "VolumePerTimeCropLoss" 94 "CountPerAreaCropLoss" 93 "MassPerAreaCropLoss" 92 "VolumePerAreaCropLoss" 91 "YieldTotalCount" 90 "YieldTotalMass" 89 "YieldTotalVolume" 88 "CountPerTimeYield" 87 "MassPerTimeYield" 86 "VolumePerTimeYield" 85 "CountPerAreaYield" 84 "MassPerAreaYield" 83 "VolumePerAreaYield" 82 "ApplicationTotalCount" 81 "ApplicationTotalMassin[kg]" 80 "ApplicationTotalVolumein[L]" 79 "MaximumCountContent" 78 "ActualCountContent" 77 "SetpointCountContent" 76 "MaximumMassContent" 75 "ActualMassContent" 74 "SetpointMassContent" 73 "MaximumVolumeContent" 72 "ActualVolumeContent" 71 "SetpointVolumeContent" 70 "MaximumWorkingWidth" 69 "MinimumWorkingWidth" 68 "DefaultWorkingWidth" 67 "ActualWorkingWidth" 66 "SetpointWorkingWidth" 65 "MaximumWorkingHeight" 64 "MinimumWorkingHeight" 63 "DefaultWorkingHeight" 62 "ActualWorkingHeight" 61 "SetpointWorkingHeight" 60 "MaximumSeedingDepth" 59 "MinimumSeedingDepth" 58 "DefaultSeedingDepth" 57 "ActualSeedingDepth" 56 "SetpointSeedingDepth" 55 "MaximumTillageDepth" 54 "MinimumTillageDepth" 53 "DefaultTillageDepth" 52 "ActualTillageDepth" 51 "SetpointTillageDepth" 50 "MaximumCountPerTimeApplicationRate" 49 "MinimumCountPerTimeApplicationRate" 48 "DefaultCountPerTimeApplicationRate" 47 "ActualCountPerTimeApplicationRate" 46 "SetpointCountPerTimeApplicationRate" 45 "MaximumMassPerTimeApplicationRate" 44 "MinimumMassPerTimeApplicationRate" 43 "DefaultMassPerTimeApplicationRate" 42 "ActualMassPerTimeApplicationRate" 41 "SetpointMassPerTimeApplicationRate" 40 "MaximumVolumePerTimeApplicationRate" 39 "MinimumVolumePerTimeApplicationRate" 38 "DefaultVolumePerTimeApplicationRate" 37 "ActualVolumePerTimeApplicationRate" 36 "SetpointVolumePerTimeApplicationRate" 35 "MaximumVolumePerMassApplicationRate" 34 "MinimumVolumePerMassApplicationRate" 33 "DefaultVolumePerMassApplicationRate" 32 "ActualVolumePerMassApplicationRate" 31 "SetpointVolumePerMassApplicationRate" 30 "MaximumMassPerMassApplicationRate" 29 "MinimumMassPerMassApplicationRate" 28 "DefaultMassPerMassApplicationRate" 27 "ActualMassPerMassApplicationRate" 26 "SetpointMassPerMassApplicationRate" 25 "MaximumVolumePerVolumeApplicationRate" 24 "MinimumVolumePerVolumeApplicationRate" 23 "DefaultVolumePerVolumeApplicationRate" 22 "ActualVolumePerVolumeApplicationRate" 21 "SetpointVolumePerVolumeApplicationRate" 20 "MaximumSpacingApplicationRate" 19 "MinimumSpacingApplicationRate" 18 "DefaultSpacingApplicationRate" 17 "ActualSpacingApplicationRate" 16 "SetpointSpacingApplicationRate" 15 "MaximumCountPerAreaApplicationRate" 14 "MinimumCountPerAreaApplicationRate" 13 "DefaultCountPerAreaApplicationRate" 12 "ActualCountPerAreaApplicationRate" 11 "SetpointCountPerAreaApplicationRate" 10 "MaximumMassPerAreaApplicationRate" 9 "MinimumMassPerAreaApplicationRate" 8 "DefaultMassPerAreaApplicationRate" 7 "ActualMassPerAreaApplicationRate" 6 "SetpointMassPerAreaApplicationRate" 5 "MaximumVolumePerAreaApplicationRate" 4 "MinimumVolumePerAreaApplicationRate" 3 "DefaultVolumePerAreaApplicationRate" 2 "ActualVolumePerAreaApplicationRate" 1 "SetpointVolumePerAreaApplicationRate" 0 "DataDictionaryVersion" ;
VAL_ 2362179326 ErrorCodeObjPoolActiveResp4 0 "NoError" 1 "DifferentDDOPWithSameLabelExists" ;
VAL_ 2362179326 ErrorCodeObjPoolActiveResp3 0 "NoError" 1 "GeneralError" ;
VAL_ 2362179326 ErrorCodeObjPoolActiveResp2 0 "NoError" 1 "TaskControllerRanOutOfMemory" ;
VAL_ 2362179326 Status 0 "EnoughMemoryAvailable" 1 "NotEnoughMemoryAvailable" ;
VAL_ 2362179326 ErrorCodeObjPoolTransfer 0 "NoError" 1 "TaskControllerRanOutOfMemory" 2 "GeneralError" ;
VAL_ 2362179326 ActivateDeactivateCommand 0 "ObjectPoolDeactivation" 255 "ObjectPoolActivation" ;
VAL_ 2362179326 ErrorCodeObjectPoolDelete 0 "Success" 1 "Error" ;
VAL_ 2362179326 ErrorCodeObjPoolActiveResp1 0 "NoError" 1 "ErrorsInTheObjectPool" ;
VAL_ 2362179326 TechnicalDataMsgType 0 "ParameterRequestVersion" 1 "ParameterVersion" ;
VAL_ 2362179326 DeviceDescriptionMsgType 0 "RequestStructureLabel" 1 "StructureLabel" 2 "RequestLocalizationLabel" 3 "LocalizationLabel" 4 "RequestObjectPoolTransfer" 5 "RequestObjectPoolTransferResp" 6 "ObjectPoolTransfer" 7 "ObjectPoolTransferResponse" 8 "ObjectPoolActivate" 9 "ObjectPoolActivateResponse" 10 "ObjectPoolDelete" 11 "ObjectPoolDeleteResponse" 12 "ChangeDesignator" 13 "ChangeDesignatorResponse" ;
VAL_ 2362179326 Command 15 "ClientTask" 14 "TaskControllerStatus" 13 "PDACK" 8 "ChangeThreshold" 7 "MaxWithinThreshold" 6 "MinWithinThreshold" 5 "DistanceInterval" 4 "TimeInterval" 3 "ValueCommand" 2 "RequestValue" 1 "DeviceDescription" 0 "TechnicalData" 9 "PeerControlAssignment" 10 "SetValueAndAcknowledge" ;
VAL_ 2565799678 IndustryGroup 7 "Reserved for SAE" 5 "IndustrialProcessCtrlStationary" 4 "Marine" 3 "Construction" 2 "Agricultural and Forestry" 1 "On-Highway" 0 "Global" ;
VAL_ 2565799678 VehicleSystem 127 "Not Available" 0 "Non-specific System" ;
VAL_ 2565799678 VehicleSystem5 0 "Ind. Process Control Stationary" 127 "Not Available" ;
VAL_ 2565799678 VehicleSystem4 0 "Non-specific System" 127 "Not Available" 10 "System Tools" 20 "Safety Systems" 25 "Inter/Intranetwork Device" 30 "Electrical Distribution" 40 "Steering and Control Surfaces" 50 "Propulsion" 60 "Navigation" 70 "Communications" 80 "Instrumentation/General Systems (deprecate)" 90 "Internal Environment" 100 "Deck, Cargo and Fishing Equipment" 35 "Electrical Generation" 75 "Sensor Communication Interface" 85 "External Environment" 120 "Display" 125 "Entertainment" ;
VAL_ 2565799678 VehicleSystem3 0 "Non-specific System" 127 "Not Available" 1 "Skid Steer Loader" 2 "Articulated Dump Truck" 3 "Backhoe" 4 "Crawler" 5 "Excavator" 6 "Forklift" 7 "Four Wheel Drive Loader" 8 "Grader" ;
VAL_ 2565799678 VehicleSystem2 0 "Non-specific System" 127 "Not Available" 1 "Tractor" 2 "Tillage" 3 "Secondary Tillage" 4 "Planters/Seeders" 5 "Fertilizers" 6 "Sprayers" 7 "Harvesters" 8 "Root Harvesters" 9 "Forage" 10 "Irrigation" 11 "Transport/Trailer" 12 "Farm Yard Operations" 13 "Powered Auxiliary Device" 14 "Special Crops" 15 "Earth Work" 16 "Skidder" 17 "Sensor Systems" 19 "Timber Harvesters" 20 "Forwarders" 21 "Timber loaders" 22 "Timber Processing Machines" 23 "Mulchers" 24 "Utility Vehicles" 25 "Slurry Applicators" ;
VAL_ 2565799678 VehicleSystem1 0 "Non-specific System" 127 "Not Available" 1 "Tractor" 2 "Trailer" ;
VAL_ 2565799678 Function 43 "Transmission Display" 44 "Exhaust Emission Control" 45 "Vehicle Dynamic Stability Control" 46 "Oil Sensor Unit" 47 "Information System Controller" 48 "Ramp Control" 49 "Clutch/Converter Control" 50 "Auxiliary Heater" 51 "Forward-Looking Collision Warning System" 52 "Chassis Controller" 53 "Alternator/Charging System" 54 "Communications Unit, Cellular" 55 "Communications Unit, Satellite" 56 "Communications Unit, Radio" 57 "Steering Column Unit" 58 "Fan Drive Control" 59 "Starter" 60 "Cab Display" 61 "File Server/Printer" 62 "On-Board Diagnostic Unit" 63 "Engine Valve Controller" 64 "Endurance Braking" 65 "Gas Flow Measurement" 66 "I/O Controller" 67 "Electrical System Controller" 68 "Aftertreatment system gas measurement" 69 "Engine Emission Aftertreatement System" 70 "Auxiliary Regeneration Device" 71 "Transfer Case Control" 72 "Coolant Valve Controller" 73 "Rollover Detection Control" 74 "Lubrication System" 75 "Supplemental Fan" 76 "Temperature Sensor" 77 "Fuel Properties Sensor" 78 "Fire Suppression System" 79 "Power Systems Manager" 80 "Electric Powertrain" 81 "Hydraulic Powertrain" 82 "File Server" 83 "Printer" 84 "Start Aid Device" 85 "Engine Injection Control Module" 86 "Reserved" 87 "Reserved" 88 "Reserved" 89 "Reserved" 90 "Reserved" 91 "Reserved" 92 "Reserved" 93 "Reserved" 94 "Reserved" 95 "Reserved" 96 "Reserved" 97 "Reserved" 98 "Reserved" 99 "Reserved" 100 "Reserved" 0 "Engine" 1 "Auxiliary Power Unit (APU)" 2 "Electric Propulsion Control" 3 "Transmission" 4 "Battery Pack Monitor" 5 "Shift Control/Console" 6 "Power TakeOff - (Main or Rear)" 7 "Axle - Steering" 8 "Axle - Drive" 9 "Brakes - System Controller" 10 "Brakes - Steer Axle" 11 "Brakes - Drive Axle" 12 "Retarder - Engine" 13 "Retarder - Driveline" 14 "Cruise Control" 15 "Fuel System" 16 "Steering Controller" 17 "Suspension - Steer Axle" 18 "Suspension - Drive Axle" 19 "Instrument Cluster" 20 "Trip Recorder" 21 "Cab Climate Control" 22 "Aerodynamic Control" 23 "Vehicle Navigation" 24 "Vehicle Security" 25 "Network Interconnect ECU" 26 "Body Controller" 27 "Power TakeOff (Secondary or Front)" 28 "Off Vehicle Gateway" 29 "Virtual Terminal (in cab)" 30 "Management Computer" 31 "Propulsion Battery Charger" 32 "Headway Controller" 33 "System Monitor" 34 "Hydraulic Pump Controller" 35 "Suspension - System Controller" 36 "Pneumatic - System Controller" 37 "Cab Controller" 38 "Tire Pressure Control" 39 "Ignition Control Module" 40 "Seat Control" 41 "Lighting - Operator Controls" 42 "Water Pump Control" 101 "Reserved" 102 "Reserved" 103 "Reserved" 104 "Reserved" 105 "Reserved" 106 "Reserved" 107 "Reserved" 108 "Reserved" 109 "Reserved" 110 "Reserved" 111 "Reserved" 112 "Reserved" 113 "Reserved" 114 "Reserved" 115 "Reserved" 116 "Reserved" 117 "Reserved" 118 "Reserved" 119 "Reserved" 120 "Reserved" 121 "Reserved" 122 "Reserved" 123 "Reserved" 124 "Reserved" 125 "Reserved" 126 "Reserved" 127 "Reserved" 128 "Non Virtual Terminal Display" 129 "Operator Controls" 130 "Task Controller" 131 "Position Control" 132 "Machine Control" 133 "Foreign Object Detection" 134 "Tractor ECU" 135 "Sequence Control Master" 136 "Product Dosing" 137 "Product Treatment" 138 "Reserved" 139 "Data Logger" 140 "Decision Support" 141 "Lighting Controller" 142 "TIM Server" 255 "Not Available" ;
VAL_ 2565799678 ManufacturerCode 1863 "Thomas G. Faria Co." 1862 "Sanshin" 1861 "Vector North America " 1860 "MMP" 1859 "Kvasar AB" 1858 "Litton" 1857 "Simrad" 1856 "Trimble" 1855 "Furuno USA" 1854 "Northstar Technologies" 1853 "Japan Radio Co" 1852 "Navionics" 1851 "RayMarine" 1850 "Teleflex" 786 "Johnson Matthey Battery Systems" 785 "Fischer Panda GmbH" 784 "CM Automotive Systems, Inc." 783 "Loup Electronics Inc." 782 "AVR bvba" 781 "Poly-Planar LLC" 780 "AVID Technology Ltd" 779 "RLC Electronic Systems" 778 "Seakeeper Inc." 777 "Ocean Signal Ltd" 776 "HMI Systems LLC" 775 "ZIEHL-ABEGG Automotive GmbH" 774 "Taisho Corporation" 773 "Clarion Corporation of America" 772 "Blink Marine" 771 "Shaw Development, LLC" 770 "MONOSEM" 769 "Trombetta" 768 "Flores Automation, LLC" 767 "Alliance Wireless Technologies Inc." 766 "Epec Oy" 765 "GIGAVAC" 764 "Bednar FMT s.r.o." 763 "AT-Systems BVBA" 762 "ROJ s.r.l." 761 "MITA OLEODINAMICA S.p.A." 760 "Bernecker + Rainer Industrie Elektronik GmbH" 759 "Hydro-Gear" 758 "Banner Engineering Corp." 757 "IMPCO Technologies" 756 "Maschio Gaspardo S.P.A." 755 "Firefly Integrations" 754 "Parker Hannifin Corp., Automation Group" 753 "AIROD Technologies" 752 "Deep Sea Electronics Plc" 751 "Pacific Track" 750 "Joskin SA" 749 "Chart Inc." 748 "ISOTTA" 747 "Agratronix" 746 "SureFire Ag Systems, Inc." 745 "Cidra Corporate Services Inc." 744 "Woosung Engineering Co., Ltd." 743 "Daemyung Elevator Co., Ltd." 742 "EROAD" 741 "Carling Technologies" 740 "e-Traction" 739 "LXNAV d.o.o." 738 "Blue Ink Technologies" 737 "Balluff GmbH" 736 "Terex Aerial Work Platforms - Genie" 735 "AEM Performance Electronics" 734 "REAPsystems" 733 "Intendia S.L." 732 "Gefran S.p.A." 731 "Modine Manufacturing Company" 730 "BERTHOUD AGRICOLE" 729 "Liebherr" 728 "Streumaster / Panien" 727 "Dhoot Transmission Pvt Ltd." 726 "MIDORI PRECISIONS" 725 "Hitachi Construction Machinery Co., Ltd." 724 "Electronic Applications, Inc." 723 "Jabil Inc." 722 "Contelec AG" 721 "Hypro" 720 "WITZ Corporation" 719 "Cojali S. L." 718 "Micronet Inc" 717 "Yacht Devices Ltd" 716 "Eaton Control & Power Conversion Division (CPCD)" 715 "Autonnic Research Ltd" 714 "Kobashi Kogyo Co., Ltd." 713 "US Hybrid Corporation" 712 "LOR Manufacturing Company Inc." 711 "DAS Co., LTD" 710 "Greentronics Ltd." 709 "Marquardt GmbH" 708 "Lars Thrane A/S" 707 "Rochester Gauges Inc" 706 "Shanghai Diesel Engine Corporation Limited" 705 "SVAB Hydraulik AB" 704 "JL Audio, Inc." 703 "Hydro Tab Marine Engineering" 702 "Weichai Power Co., Ltd." 701 "BigRoad Inc." 700 "K-Tec Earthmovers Inc." 699 "Harman International Industries" 698 "Scorpion Technologies Ltd." 697 "Ålö AB" 696 "DRS Network & Imaging Systems, LLC (DRS Technologies)" 695 "Weldon Technologies" 694 "GasTOPS Ltd." 693 "Agility Fuel Solutions (formerly Agility Fuel Systems)" 692 "Tanhay Corporation" 691 "Digitroll Agricultural Electronics" 690 "LINAK A/S" 689 "Aarcomm Systems Inc" 688 "Rockford Corp" 687 "Flight Systems, Inc." 686 "Taigene Electric Machinery Corp." 685 "ANEDO Ltd." 684 "KEB" 683 "Fosen Elektro" 682 "Eckelmann AG" 681 "BEDIA Motorentechnik GmbH & Co. KG" 680 "AMVAC Chemical Corporation" 679 "Cimco Marine AB" 678 "KeepTruckin, Inc." 677 "DSA Daten- und Systemtechnik GmbH" 676 "Danfoss IXA A/S" 675 "Kawasaki Motors Corp., USA" 674 "Yara International ASA" 673 "Caruelle Nicolas" 672 "OPTIMA Concept" 671 "Innovative Controls Inc." 670 "STEMCO LP" 669 "Quantum Fuel Systems Technologies Worldwide, Inc" 668 "MacDon Industries Ltd." 667 "Bartec" 666 "Schaeffler Technologies AG & Co., KG" 665 "Gebr. Bode GmbH & Co. KG" 664 "Level Developments Ltd" 663 "Delta Systems, Inc" 662 "Kissling Elektrotechnik GmbH" 661 "SPAL Automotive S.r.l." 660 "Auto-Gaz Centrum" 659 "Data Panel Corp." 658 "Shenzhen Jiuzhou Himunication Technology Co., Ltd" 657 "Terzo Power Systems" 656 "PRO SOLUS do Brasil" 655 "Genge & Thoma AG" 654 "Kohler Power Systems, Detroit Engine Development Center (DEDC)" 653 "AEV, spol. s r. o." 652 "MicroControl GmbH & Co. KG" 651 "Takakita Co, Ltd." 650 "Seiko Epson Corp." 649 "Control-Q BV" 648 "OJSC Ekran" 647 "Siloking" 646 "Veenhuis Machines BV" 645 "esd electronic system design gmbh" 644 "KUS USA" 643 "Bogballe A/S" 642 "Moog / Aspen Motion Technologies" 641 "Diverse Yacht Services" 640 "Power Solutions International" 639 "Startec s.r.l." 638 "KVH Industries, Inc." 637 "Bavaria Yachtbau GmbH" 636 "Divelbiss Corporation" 635 "Argo Tractors S.p.A." 634 "Rocky Research" 633 "TORC Robotics" 632 "Pepperl+Fuchs GmbH" 631 "Reltima" 630 "SmartDrive Systems Inc." 629 "Agri Info Design, Ltd." 524 "Vomax Instrumentation Pty. Ltd." 523 "Reggio Emilia Innovazione" 522 "Nebraska Tractor Test Laboratory" 521 "Clever Devices Ltd." 520 "Trapeze" 519 "Peeters Landbouwmachines b.v." 518 "Transas USA Inc." 517 "Noland Engineering" 516 "AVAT Automation GmbH" 515 "GINAF Trucks Nederland B.V." 514 "DISTek Integration, Inc." 513 "FarmscanAg" 512 "Inpower LLC" 511 "Sulky" 510 "Marinesoft Co. Ltd" 509 "MOTORTECH GmbH" 508 "Transtech Innovations" 507 "ISOBUS Test Center" 506 "IHI STAR Machinery Corporation" 505 "Yetter Farm Equipment" 504 "Vesper Marine" 503 "Naviop S.R.L." 502 "Attwood Corporation" 501 "Agrotronix S.A." 500 "Oxbo International Corporation" 499 "LCJ Capteurs" 498 "Innovative Design Solutions, Inc." 497 "SENTRON Sistemas Embarcados" 496 "W. Gessmann GmbH" 495 "HOLMER Maschinenbau GmbH" 494 "Synerject" 493 "Watcheye" 492 "Inergy Automotive Systems" 491 "Penny and Giles Ltd" 490 "QuikQ" 489 "Appareo Systems, LLC" 488 "The Charles Machine Works, Inc." 487 "DSE Test Solutions A/S" 486 "Westport Innovations Inc." 485 "MATT automotive" 484 "Headsight Inc." 483 "Valeo" 482 "Tricon Electronics" 481 "Chetco Digital Instruments" 480 "EnerDel, Inc." 479 "Vapor Bus International" 478 "OceanSat BV" 477 "OilQuick AB" 476 "Hummingbird Marine Electronics" 475 "GME" 474 "Persen Technologies Inc." 473 "Boss Industries, Inc." 472 "Tenneco Inc." 471 "Sea Cross Marine AB" 628 "Falck Schmidt Defence Systems" 627 "Radio Ocean" 626 "AVL DiTEST GmbH" 625 "Global MRV Inc." 624 "Blackbox Machine Control Pty Ltd" 623 "Xirgo Technologies" 622 "Floyd Bell Inc" 621 "Hagie Manufacturing Company" 620 "Sevcon Ltd." 619 "Right Weigh Load Scales" 618 "Evrard SA" 617 "Zero Emission Vehicles" 616 "SMART-TEC s.r.o." 615 "Networkfleet, Verizon Telematics" 614 "ARLT Technologies GmbH" 613 "HKS Co., Ltd." 612 "Samwon IT" 611 "Esterline" 610 "Trail Tech" 609 "Walvoil S.p.A." 608 "Gale Banks Engineering" 607 "Knappco/Civacon" 606 "Intellian Technologies" 605 "Aventics GmbH" 604 "Indexator Rototilt Systems AB" 603 "Kereval" 602 "Nomad Digital Ltd." 601 "Navitas Systems" 600 "Aquatic AV" 599 "Spudnik Equipment Co, LLC" 598 "ABB Turbo Systems Ltd" 597 "Hydac Filter Systems GmbH" 596 "Brunelco Electronic Innovators B.V." 595 "CustomWare" 594 "Kongsberg Automotive" 593 "Sensata Technologies" 592 "tecsis GmbH" 591 "United States Coast Guard" 590 "ARGO-HYTOS GMBH" 589 "MICO, Inc." 588 "Vignal Systems" 587 "JCA Electronics" 586 "Suzuki Motor Corp" 585 "Industrial Electronic Controls" 584 "CarMedialab GmbH" 583 "Yachtcontrol" 582 "Innovative Software Engineering" 581 "Väderstad - Verken AB" 580 "San Jose Technology, Inc." 579 "KVH Industries, Inc." 578 "advanSea" 577 "Denchi Power Ltd  (formerly ABSL Power Solutions Limited)" 576 "Vectia" 575 "Lytx" 574 "Vishay Precision Group" 573 "Orolia Ltd" 572 "Fasse Valves" 571 "Marinecraft Co., Ltd." 570 "frenzel + berg electronic GmbH & Co. KG" 569 "LORD MicroStrain Sensing Systems" 568 "Makersan Ltd. Co." 567 "Lithiumstart LLC" 566 "Geode Technology, Inc." 565 "Micro-Trak Systems, Inc." 564 "Auto Power Electronic" 563 "LOHR Sistemas Eletronicos LTDA" 562 "Bombardier Transportation GmbH" 561 "b-plus GmbH" 560 "Iowa State University, Agricultural and Biosystems Engineering" 559 "Four Peaks Navigation" 558 "Davis Instruments Corp." 557 "Rockson Automation GmbH" 556 "Doosan Infracore Norway" 555 "Sasaki Corporation" 554 "iris-GmbH infrared & intelligent sensors" 553 "KIB Electronics" 552 "Matsuyama Plow Mfg Co, Ltd" 551 "Wexler CSD Ltd." 550 "SUN-A Corporation" 549 "ROAD Deutschland GmbH" 548 "TM4 Inc." 547 "Thomson Linear LLC" 546 "Maruyama Mfg Co, Inc." 545 "GS Hydraulics" 544 "Au Group Electronics" 543 "BAUER Maschinen GmbH" 542 "Dinamica Generale s.p.a." 541 "Total Fire Systems, Inc." 540 "Dinex A/S" 539 "Mobileview" 538 "Crop Ventures, Inc." 537 "Schrader Electronics Ltd." 536 "SSI Technologies" 535 "MOTORPAL, a.s." 534 "Webasto Thermo & Comfort SE" 533 "Doran Manufacturing, LLC" 532 "Onwa Marine Electronics Co Ltd." 531 "Genge & Thoma AG" 530 "NMEA" 529 "National Instruments Korea" 528 "Hoganas AB, Electric Drive Systems" 527 "GKN Walterscheid GmbH" 526 "LOFA Industries, Inc" 525 "Rust Sales INC" 470 "SI-TEX Marine Electronics" 469 "RA Consulting GmbH" 468 "Tyco Fire Protection Products" 467 "Lely Industries N.V." 466 "Veethree Electronics and Marine LLC" 465 "Ashcroft Inc" 464 "Leach International Corporation" 463 "PROBOTIQ" 462 "IHI Shibaura Machinery Corporation" 461 "HAWE Hydraulik SE" 460 "San Giorgio S.E.I.N." 459 "Alltek Marine Electronics Corp" 458 "Control Solutions, Inc." 457 "RUSELPROM-ElectricDrive Ltd" 456 "General Kinetics" 455 "ADZ NAGANO GmbH" 454 "NGK Spark Plug Co. Ltd" 453 "Cooper Bussmann" 452 "WIKA Alexander Wiegand SE & Co. KG" 451 "Parker Hannifin Corp" 450 "Dycor Technologies Ltd." 449 "Polaris Industries Inc" 448 "Stanadyne Corporation, Electronics Systems" 447 "Great Plains Mfg." 446 "CertTech, L.L.C." 445 "KAT MECHATRONIC, Electronic Product Division" 444 "ITT Power Solutions" 443 "SignalQuest, Inc." 442 "Horsch Maschinen GmbH" 441 "PTG Reifendruckregelsysteme GmbH" 440 "Cummins Power Generation" 439 "Hyundai Heavy Industries" 438 "Comar Systems Ltd" 437 "Digital Yacht Limited" 436 "Kinze Manufacturing" 435 "Zunhammer GmbH" 434 "Stored Energy Systems" 433 "Rowe Electronics" 432 "S&A Systems, Inc." 431 "Tohatsu Corporation" 430 "Auteq Telematica S.A." 429 "Rota Engineering Ltd." 425 "Methode Electronics Inc, MDI" 424 "Odyne LLC" 423 "BSM Wireless, Inc." 422 "True Heading AB" 421 "Vertex Standard Co, Ltd" 420 "Vermeer Corporation, ACS Group" 419 "Fusion Electronics Ltd" 418 "Intellistick Inc" 417 "KZValve" 416 "Kubota Corporation" 415 "Valid Manufacturing Ltd." 414 "Cattron Group International" 413 "Datapross Nijbroek bv" 412 "WebTech Wireless Inc." 411 "Hy-Drive Technologies Ltd." 410 "COBO S.p.A. Divisione 3B6" 409 "Transfluid S.r.L." 408 "Corvus Energy Ltd." 407 "Comtech Mobile Datacom" 406 "Vecima Networks Inc." 405 "Wema System AS" 404 "Com Nav Marine Ltd" 403 "Trackwell ADS, Inc." 402 "Simma Software, Inc." 401 "Torqeedo GmbH" 400 "Livorsi Marine" 399 "ISEKI & Co., Ltd." 398 "Hilite International" 397 "Sanyo-kiki Co Ltd." 396 "Beyond Measure" 395 "GENTEC S.R.L." 394 "Capi 2 Nederland BV" 393 "Harvest Tec, Inc" 392 "Tianyuan Technology Co Ltd." 391 "Electronic Design for Industry, Inc" 390 "Partech Inc." 389 "Benchmark Electronics, Minnesota Division" 388 "Innomatix, LLC" 387 "Orscheln Products, LLC" 386 "JLG Automation BVBA" 385 "Johnson Outdoor Marine Electronics" 384 "Camano Light" 383 "MCL Industries" 382 "National Agriculture and Food Research Organization" 381 "B & G" 380 "Suntech International Ltd." 379 "Yamabiko Corporation" 378 "Glendinning Marine Products" 377 "ifm electronic gmbh" 376 "Quake Global" 375 "Williams Controls Inc." 374 "Northern Lights, Inc." 373 "Electronic Design Inc." 372 "Delphi" 371 "Heinzmann GmbH & Co. KG" 370 "Rolls-Royce Marine AS" 369 "Power Torque Engineering Ltd" 368 "HANSENHOF_electronic" 367 "Fliegl Agrartechnik" 366 "Viewnyx Corp." 365 "Digi-Star, LLC" 364 "OEM Controls Inc." 363 "BEI Duncan" 362 "Poettinger Landtechnik GmbH (formerly Alois Poettinger Maschinenfabrik GmbH)" 361 "InMach" 360 "HJS Emission Technology GmbH & Co KG   (formerly HJS Fahrzeugtechnik GmbH & Co KG)" 359 "Ludwig Bergmann GmbH" 358 "Victron Energy BV" 357 "Hardi International A/S" 356 "Fischer Panda Generators, Inc" 355 "Mastervolt International B.V." 354 "Junkkari OY" 353 "Hegemon Electronics, Inc." 352 "SAME DEUTZ-FAHR GROUP S.p.A." 351 "Thrane & Thrane" 350 "Noris Marine Systems GmbH & Co KG" 349 "Suonentieto" 348 "Amazonen Werke H. Dreyer" 347 "Honeywell" 346 "Control Solutions" 345 "Korean Maritime University" 344 "Parvus Corporation" 343 "Baumer Group" 342 "THOMAS MAGNETE GmbH" 341 "Boning GmbH & Co" 340 "Continental AG" 339 "Competence Center ISOBUS e.V." 338 "GRAF-SYTECO" 337 "Carraro S.p.A." 336 "APE s.r.o." 335 "Evo Electric Ltd" 334 "Takata-Petri AG" 333 "Hadley Products Corporation" 332 "HWH Corporation" 331 "Horton, Inc." 330 "Kidde Aerospace and Defense" 329 "Deif A/S" 328 "Qwerty Electronik AB" 327 "Sonceboz SA" 326 "Akron Brass Company" 325 "ASM Automation Sensorik Messtechnik GmbH" 324 "Snap-on Diagnostics" 323 "Mobileye Vision Technologies Ltd." 322 "MICHENKA s.r.o." 321 "Ultra Electronics, Electrics" 320 "Miedema Landbouwwerktuigenfabriek B.V." 319 "Cadec Global" 318 "SAT Plan" 317 "Navtronics Bvba" 263 "IMMI" 262 "HydraForce, Inc" 261 "Red Dot Corporation" 260 "Reichhardt GmbH Steuerungstechnik" 259 "Jetter AG" 258 "ARAG" 257 "Honda Motor Co., Ltd" 256 "Tyco Electronics AMP" 255 "MEAS France" 254 "GE Sensing" 253 "Mobile Control Systems" 252 "Sensor-Technik Wiedemann GmbH" 251 "German Agricultural Society, Test Center (DLG)" 250 "Kuhn Group" 249 "Schaltbau GmbH" 248 "Cooper Standard Automotive Active Systems Group" 247 "ePULSE" 246 "Class 1, Inc" 245 "Capstan Ag Systems, Inc." 244 "Techno-Matic" 243 "eRide, Inc." 242 "Kokusandenki Co. Ltd" 241 "Schneider Automation SAS" 240 "Vanair Mfg" 239 "May & Scofield Ltd" 238 "ZF Friedrichshafen AG" 237 "Agtron Enterprises Inc" 236 "NORAC Systems International Inc" 235 "SailorMade Marine Telemetry - Tetra Technology Ltd." 234 "Mondial electronic GmbH" 233 "Yacht Monitoring Solutions Inc." 232 "TSD Integrated Controls" 231 "Topcon Positioning Systems, Inc." 230 "Saucon Technologies" 229 "Garmin International Inc." 228 "Unused (formerly ZF Marine Electronics)" 227 "Lykketronic A/S" 226 "Monaco Coach Corporation" 225 "SKF" 224 "EMMI Network, S.L." 223 "Vaueo Retarder Co., Ltd." 222 "Generac Power Systems, Inc." 221 "SiE" 220 "Beede Electrical Instrument Company, Inc" 219 "Cat OEM Solutions" 218 "Gits Manufacturing Company" 217 "RM Michaelides Software & Elektronik GmbH" 216 "Paneltronics Inc." 215 "Aetna Engineering/Fireboy-Xintex" 214 "MC elettronica Srl" 164 "MTU Friedrichshafen GmbH (formerly DaimlerChrysler Off-Highway)" 163 "BRP Inc." 162 "Axiomatic Technologies" 161 "Offshore Systems (UK) Ltd" 160 "Nido" 159 "NTech Industries Inc" 158 "Firestone Industrial Products Company" 157 "ISSPRO Inc." 156 "ITT Industries - Cannon" 155 "Vetronix Corporation" 154 "Westerbeke Corporation" 153 "Woodward, Industrial Controls Division" 152 "elobau GmbH & Co. KG" 151 "Raven Industries, Inc." 150 "Fleetguard" 149 "Holset" 148 "Blue Water Data, Inc." 147 "Nautibus electronic GmbH" 146 "Maxima Technologies" 145 "MurCal Controls" 144 "Mercury Marine" 143 "W. Gmeiner GmbH & Co." 142 "TRW Automotive (Commercial Steering Systems)" 141 "Thales Navigation Ltd." 140 "Lowrance Electronics, Inc." 139 "Caterpillar Trimble Control Technologies (CTCT), LLC" 138 "Georg Fritzmeier GmbH & Co. KG" 137 "Maretron" 136 "Komatsu Ltd" 135 "Airmar Technology Corporation" 134 "Iris Technology Ltd" 133 "Bucher Schoerling GmbH" 132 "Mulag-Fahrzeugwerk" 131 "ITT Industries" 130 "Nido - Universal Machines B.V." 129 "OMNEX Control Systems Inc." 128 "Gerhard Duecker GmbH & Co. KG" 127 "Holland USA" 126 "Driver Tech" 125 "Nevada Automotive Test Center" 124 "Hydac Electronic" 123 "Basler Electric" 122 "FG Wilson (Engineering) Limited" 121 "HED (Hydro Electronic Devices, Inc.)" 120 "RDS Technology Ltd" 119 "IntegriNautics  " 118 "Intron GmbH" 117 "HUSCO International" 116 "BEELINE Technologies" 115 "NACCO Materials Handling Group, Inc." 114 "EControls, Inc." 113 "Stress-Tek, Inc." 112 "MECALAC" 111 "Maschinenfabrik Bernard Krone GmbH" 110 "EPIQ Sensor-Nite" 109 "TeeJet Technologies Denmark (formerly LH Technologies ApS)" 108 "WTK-Elecktronik GmbH" 107 "Grimme Landmaschinen GmbH & Co. KG" 106 "BAE Systems Controls, Inc." 105 "Kiepe Elektrik GmbH & Co. KG" 104 "CLAAS KGaA mbH (formerly CLAAS Selbstfahrende Erntemaschinen GmbH)" 103 "CLAAS E-Systems KGaA mbH & Co. KG (formerly CLAAS Agrosystems GmbH & Co. KG)" 102 "AGCO (formerly AGCO GmbH & Co.)" 101 "Sensoria" 100 "VDO Technik AG" 99 "International Transmissions Ltd (ITL)" 98 "Mueller-Elektronik GmbH & Co" 97 "Ag Leader Technology, Inc." 96 "Mech@tronic IT GmbH" 95 "Pacific Insight Electronics Corp." 94 "CNH Industrial N.V. (formerly CNH Global N.V.)" 93 "Perkins Engines Company Ltd." 92 "Ag-Chem Equipment Co., Inc." 91 "BSG Bodensee Steuergeraete GmbH" 90 "Knorr-Bremse SfN GmbH" 89 "Kverneland Group, Electronics Division" 88 "Satloc Precision GPS" 87 "J.C. Bamford Excavators Ltd (JCB)" 86 "C. E. Niehoff & Company" 85 "Kohler Co" 84 "New Holland UK Limited" 83 "Bendix VORAD Technologies (formerly Eaton VORAD Technologies)" 82 "Bobcat/Ingersoll-Rand (formerly Melroe/Ingersoll-Rand)" 81 "Fire Research Corp." 80 "Twin Disc, Inc." 79 "Daimler Benz AG - Engine Division (PBM)" 78 "Frank W. Murphy Manufacturing, Inc" 77 "Deere Power Systems Group" 76 "unused (formerly Deere & Co, Construction Division)" 75 "Deere & Co, Agricultural Division" 74 "Eaton Axle-Brake Division" 73 "LeTourneau, Inc." 72 "Sisu Corporation" 71 "Vansco Electronics Ltd." 70 "Flex-coil Limited" 69 "Trimble Navigation" 316 "ITT Flow Control" 315 "Icom Incorporated" 314 "CSM GmbH" 313 "Ilmor Engineering, Inc." 312 "Lectronix, Inc." 311 "Patrick Power Products" 310 "TECNORD srl" 309 "Krauss-Maffei Wegmann GmbH & Co. KG" 308 "Cyntrx" 307 "MAS Technologies" 306 "Sleipner Motor AB" 305 "NovAtel Inc" 304 "EmpirBus AB" 303 "CTS Corporation" 302 "Nissin Kogyo Co., LTD" 301 "Parker Hannifin (UK) Ltd FDE group" 300 "Systron Donner Automotive" 299 "Rauch" 298 "Holley Performance" 297 "Zonar Systems Inc" 296 "micro dynamics GmbH" 295 "BEP Marine" 294 "Grayhill Inc." 293 "Spyder Controls Corp." 292 "IKUSI - Angel Iglesias S.A." 291 "Groeneveld Transport Efficiency BV" 290 "Kuebler GmbH" 289 "Watlow" 288 "Mitsubishi FUSO Truck & Bus Corp." 287 "NTech Industries, Inc" 286 "Coelmo srl" 285 "Sea Recovery Corp" 284 "Mobile Tech Chile" 283 "CWF Hamilton & Co Ltd" 282 "Medallion Instrumentation Systems" 281 "Precision Governors LLC" 280 "Leica Geosystems Pty Ltd" 279 "Geometris LP" 278 "Takata Electronics" 277 "LHP Telematics" 276 "Aqua-Hot Heating Systems" 275 "Navico Egersund AS" 274 "LTW Technology Co., LTD" 273 "Active Research Limited" 272 "Gross Mechanical Laboratories, Inc" 271 "Cole Hersee" 270 "Tennant" 269 "Saft America Inc.,  Space & Defense Division" 268 "Accurate Technologies" 267 "Red Lion Controls, Inc" 266 "International Thermal Research Ltd" 265 "MTS Sensor Technologie GmbH" 264 "Autolync" 213 "CNH Belgium N.V." 212 "Sure Power Industries, Inc" 211 "DNA Group" 210 "Iteris, Inc." 209 "Bell Equip. Co. SA (PTY) LTD" 208 "Drew Technologies, Inc" 207 "Otto Engineering" 206 "port GmbH" 205 "SmarTire Systems Inc" 204 "The Morey Corporation" 203 "MILtronik GmbH" 202 "Curtis Instruments, Inc" 201 "Disenos y Tecnologia S.A." 200 "MGM Brakes" 199 "Actia Corp" 198 "Mystic Valley Communications" 197 "Mechron Power Systems" 196 "LEMKEN GmbH & Co KG" 195 "General Engine Products" 194 "TriMark Corporation" 193 "Jeppesen Marine" 192 "Floscan" 191 "XRS Corporation (formerly XATA Corporation)" 190 "Hella KGaA Hueck & Co" 189 "QUALCOMM" 188 "EMP Corp" 187 "Air-Weigh" 186 "Altronic, Inc" 185 "Beede Electrical Instrument Company" 184 "EIA Electronics" 183 "KDS Controls, Inc" 182 "Vehicle Systems Engineering B.V." 181 "Coretronics, Inc." 180 "Smart Power Systems" 179 "TeeJet Technologies Springfield (formerly Midwest Technologies Illinois, LLC)" 178 "Continental Automotive GmbH (formerly Siemens VDO Automotive AG)" 177 "Diagnostic Systems Associates" 176 "Moritz Aerospace" 175 "Veris Technologies, Inc." 174 "AB Volvo Penta" 173 "Ryeso, Inc." 172 "Yanmar Co., Ltd. (formerly Yanmar Marine USA)" 171 "Wachendorff Elektronik GmbH & Co. KG" 170 "Computronics Corporation Ltd." 169 "Marlin Technologies Inc." 168 "Xantrex" 167 "JLG Industries Inc" 166 "John Deere Electronic Solutions (formerly Phoenix International)" 165 "CPAC Systems AB" 68 "Scania" 67 "John Deere Coffeyville Works (formerly Funk Manufacturing Company)" 66 "John Deere Construction Equipment Division" 65 "MAN Nutzfahrzeuge AG" 64 "Unused (formerly SpectraPrecision Laserplane, then SpectraPhysics)" 63 "ZF Industries Inc." 62 "Wabco" 61 "Volvo Truck Corp." 60 "Volvo Trucks North America Inc." 59 "VES Inc." 58 "SPX Corporation, OTC Div" 57 "Danfoss  (formerly Sauer Sundstrand Co, then Sauer-Danfoss Co)" 56 "SAIC" 55 "Ryder System Inc." 54 "Meritor Wabco" 53 "Continental Automotive Systems US, Inc. (formerly Rockwell Land Transportation)" 52 "Meritor Automotive, Inc. (formerly Rockwell Automotive)" 51 "Robert Bosch GmbH" 50 "Robert Bosch Corp" 49 "RE America Inc." 48 "Pollak Alphabet" 47 "Phillips Semiconductor" 46 "Noregon Systems, Inc  (formerly Parasoft Computing Solutions)" 45 "PACCAR" 44 "Nippondenso Co. Ltd." 43 "International Truck and Engine Corporation - Vehicle Electronics (formerly Navistar Intl Trans Corp.)" 42 "International Truck and Engine Corporation - Engine Electronics  (formerly Navistar Intl Trans Co., Engine Electronics)" 41 "Motorola Inc." 40 "Motorola AIEG Inc." 39 "Microfirm Inc." 38 "Micro Processor Systems Inc." 37 "Mack Trucks Inc." 36 "Lucas Ind." 35 "Kenworth Truck Co." 34 "Kelsey Hayes Co." 33 "John Deere" 32 "Jacobs Vehicle Systems" 31 "J Pollak Corp" 30 "Isuzu Motors Ltd" 29 "Hino Motors Ltd." 28 "Grote Ind. Inc." 27 "GMC" 26 "General Motors Corp, Service Technology Grp" 25 "Daimler Trucks North America LLC (formerly Freightliner LLC)" 24 "Ford Motor Co., Vehicle Controls" 23 "Ford Motor Co., Heavy Truck" 22 "Ford Motor Co., Electronic Concepts & Systems" 21 "Echlin Inc., Midland Brake Inc." 20 "Eaton Ltd" 19 "Eaton Corp. Trucking Info Services" 18 "Eaton Corp, Transmission Div." 17 "Eaton Corp, Corp Res & Dev" 16 "Eaton Corp" 15 "DICKEY-john Corporation" 14 "Detroit Diesel Corporation" 13 "Delco Electronics" 12 "Deere & Company, Precision Farming" 11 "Dearborn Group Inc." 10 "Cummins Inc (formerly Cummins Engine Co)" 9 "Chrysler Corp." 8 "Caterpillar Inc." 7 "Case Corp." 6 "Berifors Electronics AB" 5 "AMP Inc." 4 "Ametek-Dixson" 3 "Ametek, US Gauge Division" 2 "Allison Transmission, Inc." 1 "Bendix Commercial Vehicle Systems LLC (formerly Allied Signal Inc.)" 0 "Reserved" ;
VAL_ 2566838526 IndustryGroup 7 "NotAvailable" 5 "Reserved" 4 "Marine" 3 "Construction" 2 "AgriculturalAndForestry" 1 "OnHighway" 0 "Global" ;
VAL_ 2566838526 VehicleSystem1 0 "Non-specific System" 127 "Not Available" 1 "Tractor" 2 "Trailer" ;
VAL_ 2566838526 VehicleSystem2 0 "Non-specific System" 127 "Not Available" 1 "Tractor" 2 "Tillage" 3 "Secondary Tillage" 4 "Planters/Seeders" 5 "Fertilizers" 6 "Sprayers" 7 "Harvesters" 8 "Root Harvesters" 9 "Forage" 10 "Irrigation" 11 "Transport/Trailer" 12 "Farm Yard Operations" 13 "Powered Auxiliary Device" 14 "Special Crops" 15 "Earth Work" 16 "Skidder" 17 "Sensor Systems" 19 "Timber Harvesters" 20 "Forwarders" 21 "Timber loaders" 22 "Timber Processing Machines" 23 "Mulchers" 24 "Utility Vehicles" 25 "Slurry Applicators" ;
VAL_ 2566838526 VehicleSystem3 0 "Non-specific System" 127 "Not Available" 1 "Skid Steer Loader" 2 "Articulated Dump Truck" 3 "Backhoe" 4 "Crawler" 5 "Excavator" 6 "Forklift" 7 "Four Wheel Drive Loader" 8 "Grader" ;
VAL_ 2566838526 VehicleSystem4 0 "Non-specific System" 127 "Not Available" 10 "System Tools" 20 "Safety Systems" 25 "Inter/Intranetwork Device" 30 "Electrical Distribution" 40 "Steering and Control Surfaces" 50 "Propulsion" 60 "Navigation" 70 "Communications" 80 "Instrumentation/General Systems (deprecate)" 90 "Internal Environment" 100 "Deck, Cargo and Fishing Equipment" 35 "Electrical Generation" 75 "Sensor Communication Interface" 85 "External Environment" 120 "Display" 125 "Entertainment" ;
VAL_ 2566838526 VehicleSystem5 0 "Ind. Process Control Stationary" 127 "Not Available" ;
VAL_ 2566838526 VehicleSystem 127 "Not Available" 0 "Non-specific System" ;
VAL_ 2566838526 Function 43 "Transmission Display" 44 "Exhaust Emission Control" 45 "Vehicle Dynamic Stability Control" 46 "Oil Sensor Unit" 47 "Information System Controller" 48 "Ramp Control" 49 "Clutch/Converter Control" 50 "Auxiliary Heater" 51 "Forward-Looking Collision Warning System" 52 "Chassis Controller" 53 "Alternator/Charging System" 54 "Communications Unit, Cellular" 55 "Communications Unit, Satellite" 56 "Communications Unit, Radio" 57 "Steering Column Unit" 58 "Fan Drive Control" 59 "Starter" 60 "Cab Display" 61 "File Server/Printer" 62 "On-Board Diagnostic Unit" 63 "Engine Valve Controller" 64 "Endurance Braking" 65 "Gas Flow Measurement" 66 "I/O Controller" 67 "Electrical System Controller" 68 "Aftertreatment system gas measurement" 69 "Engine Emission Aftertreatement System" 70 "Auxiliary Regeneration Device" 71 "Transfer Case Control" 72 "Coolant Valve Controller" 73 "Rollover Detection Control" 74 "Lubrication System" 75 "Supplemental Fan" 76 "Temperature Sensor" 77 "Fuel Properties Sensor" 78 "Fire Suppression System" 79 "Power Systems Manager" 80 "Electric Powertrain" 81 "Hydraulic Powertrain" 82 "File Server" 83 "Printer" 84 "Start Aid Device" 85 "Engine Injection Control Module" 86 "Reserved" 87 "Reserved" 88 "Reserved" 89 "Reserved" 90 "Reserved" 91 "Reserved" 92 "Reserved" 93 "Reserved" 94 "Reserved" 95 "Reserved" 96 "Reserved" 97 "Reserved" 98 "Reserved" 99 "Reserved" 100 "Reserved" 0 "Engine" 1 "Auxiliary Power Unit (APU)" 2 "Electric Propulsion Control" 3 "Transmission" 4 "Battery Pack Monitor" 5 "Shift Control/Console" 6 "Power TakeOff - (Main or Rear)" 7 "Axle - Steering" 8 "Axle - Drive" 9 "Brakes - System Controller" 10 "Brakes - Steer Axle" 11 "Brakes - Drive Axle" 12 "Retarder - Engine" 13 "Retarder - Driveline" 14 "Cruise Control" 15 "Fuel System" 16 "Steering Controller" 17 "Suspension - Steer Axle" 18 "Suspension - Drive Axle" 19 "Instrument Cluster" 20 "Trip Recorder" 21 "Cab Climate Control" 22 "Aerodynamic Control" 23 "Vehicle Navigation" 24 "Vehicle Security" 25 "Network Interconnect ECU" 26 "Body Controller" 27 "Power TakeOff (Secondary or Front)" 28 "Off Vehicle Gateway" 29 "Virtual Terminal (in cab)" 30 "Management Computer" 31 "Propulsion Battery Charger" 32 "Headway Controller" 33 "System Monitor" 34 "Hydraulic Pump Controller" 35 "Suspension - System Controller" 36 "Pneumatic - System Controller" 37 "Cab Controller" 38 "Tire Pressure Control" 39 "Ignition Control Module" 40 "Seat Control" 41 "Lighting - Operator Controls" 42 "Water Pump Control" 101 "Reserved" 102 "Reserved" 103 "Reserved" 104 "Reserved" 105 "Reserved" 106 "Reserved" 107 "Reserved" 108 "Reserved" 109 "Reserved" 110 "Reserved" 111 "Reserved" 112 "Reserved" 113 "Reserved" 114 "Reserved" 115 "Reserved" 116 "Reserved" 117 "Reserved" 118 "Reserved" 119 "Reserved" 120 "Reserved" 121 "Reserved" 122 "Reserved" 123 "Reserved" 124 "Reserved" 125 "Reserved" 126 "Reserved" 127 "Reserved" 128 "Non Virtual Terminal Display" 129 "Operator Controls" 130 "Task Controller" 131 "Position Control" 132 "Machine Control" 133 "Foreign Object Detection" 134 "Tractor ECU" 135 "Sequence Control Master" 136 "Product Dosing" 137 "Product Treatment" 138 "Reserved" 139 "Data Logger" 140 "Decision Support" 141 "Lighting Controller" 142 "TIM Server" 255 "Not Available" ;
VAL_ 2566838526 ManufacturerCode 1863 "Thomas G. Faria Co." 1862 "Sanshin" 1861 "Vector North America " 1860 "MMP" 1859 "Kvasar AB" 1858 "Litton" 1857 "Simrad" 1856 "Trimble" 1855 "Furuno USA" 1854 "Northstar Technologies" 1853 "Japan Radio Co" 1852 "Navionics" 1851 "RayMarine" 1850 "Teleflex" 786 "Johnson Matthey Battery Systems" 785 "Fischer Panda GmbH" 784 "CM Automotive Systems, Inc." 783 "Loup Electronics Inc." 782 "AVR bvba" 781 "Poly-Planar LLC" 780 "AVID Technology Ltd" 779 "RLC Electronic Systems" 778 "Seakeeper Inc." 777 "Ocean Signal Ltd" 776 "HMI Systems LLC" 775 "ZIEHL-ABEGG Automotive GmbH" 774 "Taisho Corporation" 773 "Clarion Corporation of America" 772 "Blink Marine" 771 "Shaw Development, LLC" 770 "MONOSEM" 769 "Trombetta" 768 "Flores Automation, LLC" 767 "Alliance Wireless Technologies Inc." 766 "Epec Oy" 765 "GIGAVAC" 764 "Bednar FMT s.r.o." 763 "AT-Systems BVBA" 762 "ROJ s.r.l." 761 "MITA OLEODINAMICA S.p.A." 760 "Bernecker + Rainer Industrie Elektronik GmbH" 759 "Hydro-Gear" 758 "Banner Engineering Corp." 757 "IMPCO Technologies" 756 "Maschio Gaspardo S.P.A." 755 "Firefly Integrations" 754 "Parker Hannifin Corp., Automation Group" 753 "AIROD Technologies" 752 "Deep Sea Electronics Plc" 751 "Pacific Track" 750 "Joskin SA" 749 "Chart Inc." 748 "ISOTTA" 747 "Agratronix" 746 "SureFire Ag Systems, Inc." 745 "Cidra Corporate Services Inc." 744 "Woosung Engineering Co., Ltd." 743 "Daemyung Elevator Co., Ltd." 742 "EROAD" 741 "Carling Technologies" 740 "e-Traction" 739 "LXNAV d.o.o." 738 "Blue Ink Technologies" 737 "Balluff GmbH" 736 "Terex Aerial Work Platforms - Genie" 735 "AEM Performance Electronics" 734 "REAPsystems" 733 "Intendia S.L." 732 "Gefran S.p.A." 731 "Modine Manufacturing Company" 730 "BERTHOUD AGRICOLE" 729 "Liebherr" 728 "Streumaster / Panien" 727 "Dhoot Transmission Pvt Ltd." 726 "MIDORI PRECISIONS" 725 "Hitachi Construction Machinery Co., Ltd." 724 "Electronic Applications, Inc." 723 "Jabil Inc." 722 "Contelec AG" 721 "Hypro" 720 "WITZ Corporation" 719 "Cojali S. L." 718 "Micronet Inc" 717 "Yacht Devices Ltd" 716 "Eaton Control & Power Conversion Division (CPCD)" 715 "Autonnic Research Ltd" 714 "Kobashi Kogyo Co., Ltd." 713 "US Hybrid Corporation" 712 "LOR Manufacturing Company Inc." 711 "DAS Co., LTD" 710 "Greentronics Ltd." 709 "Marquardt GmbH" 708 "Lars Thrane A/S" 707 "Rochester Gauges Inc" 706 "Shanghai Diesel Engine Corporation Limited" 705 "SVAB Hydraulik AB" 704 "JL Audio, Inc." 703 "Hydro Tab Marine Engineering" 702 "Weichai Power Co., Ltd." 701 "BigRoad Inc." 700 "K-Tec Earthmovers Inc." 699 "Harman International Industries" 698 "Scorpion Technologies Ltd." 697 "Ålö AB" 696 "DRS Network & Imaging Systems, LLC (DRS Technologies)" 695 "Weldon Technologies" 694 "GasTOPS Ltd." 693 "Agility Fuel Solutions (formerly Agility Fuel Systems)" 692 "Tanhay Corporation" 691 "Digitroll Agricultural Electronics" 690 "LINAK A/S" 689 "Aarcomm Systems Inc" 688 "Rockford Corp" 687 "Flight Systems, Inc." 686 "Taigene Electric Machinery Corp." 685 "ANEDO Ltd." 684 "KEB" 683 "Fosen Elektro" 682 "Eckelmann AG" 681 "BEDIA Motorentechnik GmbH & Co. KG" 680 "AMVAC Chemical Corporation" 679 "Cimco Marine AB" 678 "KeepTruckin, Inc." 677 "DSA Daten- und Systemtechnik GmbH" 676 "Danfoss IXA A/S" 675 "Kawasaki Motors Corp., USA" 674 "Yara International ASA" 673 "Caruelle Nicolas" 672 "OPTIMA Concept" 671 "Innovative Controls Inc." 670 "STEMCO LP" 669 "Quantum Fuel Systems Technologies Worldwide, Inc" 668 "MacDon Industries Ltd." 667 "Bartec" 666 "Schaeffler Technologies AG & Co., KG" 665 "Gebr. Bode GmbH & Co. KG" 664 "Level Developments Ltd" 663 "Delta Systems, Inc" 662 "Kissling Elektrotechnik GmbH" 661 "SPAL Automotive S.r.l." 660 "Auto-Gaz Centrum" 659 "Data Panel Corp." 658 "Shenzhen Jiuzhou Himunication Technology Co., Ltd" 657 "Terzo Power Systems" 656 "PRO SOLUS do Brasil" 655 "Genge & Thoma AG" 654 "Kohler Power Systems, Detroit Engine Development Center (DEDC)" 653 "AEV, spol. s r. o." 652 "MicroControl GmbH & Co. KG" 651 "Takakita Co, Ltd." 650 "Seiko Epson Corp." 649 "Control-Q BV" 648 "OJSC Ekran" 647 "Siloking" 646 "Veenhuis Machines BV" 645 "esd electronic system design gmbh" 644 "KUS USA" 643 "Bogballe A/S" 642 "Moog / Aspen Motion Technologies" 641 "Diverse Yacht Services" 640 "Power Solutions International" 639 "Startec s.r.l." 638 "KVH Industries, Inc." 637 "Bavaria Yachtbau GmbH" 636 "Divelbiss Corporation" 635 "Argo Tractors S.p.A." 634 "Rocky Research" 633 "TORC Robotics" 632 "Pepperl+Fuchs GmbH" 631 "Reltima" 630 "SmartDrive Systems Inc." 629 "Agri Info Design, Ltd." 524 "Vomax Instrumentation Pty. Ltd." 523 "Reggio Emilia Innovazione" 522 "Nebraska Tractor Test Laboratory" 521 "Clever Devices Ltd." 520 "Trapeze" 519 "Peeters Landbouwmachines b.v." 518 "Transas USA Inc." 517 "Noland Engineering" 516 "AVAT Automation GmbH" 515 "GINAF Trucks Nederland B.V." 514 "DISTek Integration, Inc." 513 "FarmscanAg" 512 "Inpower LLC" 511 "Sulky" 510 "Marinesoft Co. Ltd" 509 "MOTORTECH GmbH" 508 "Transtech Innovations" 507 "ISOBUS Test Center" 506 "IHI STAR Machinery Corporation" 505 "Yetter Farm Equipment" 504 "Vesper Marine" 503 "Naviop S.R.L." 502 "Attwood Corporation" 501 "Agrotronix S.A." 500 "Oxbo International Corporation" 499 "LCJ Capteurs" 498 "Innovative Design Solutions, Inc." 497 "SENTRON Sistemas Embarcados" 496 "W. Gessmann GmbH" 495 "HOLMER Maschinenbau GmbH" 494 "Synerject" 493 "Watcheye" 492 "Inergy Automotive Systems" 491 "Penny and Giles Ltd" 490 "QuikQ" 489 "Appareo Systems, LLC" 488 "The Charles Machine Works, Inc." 487 "DSE Test Solutions A/S" 486 "Westport Innovations Inc." 485 "MATT automotive" 484 "Headsight Inc." 483 "Valeo" 482 "Tricon Electronics" 481 "Chetco Digital Instruments" 480 "EnerDel, Inc." 479 "Vapor Bus International" 478 "OceanSat BV" 477 "OilQuick AB" 476 "Hummingbird Marine Electronics" 475 "GME" 474 "Persen Technologies Inc." 473 "Boss Industries, Inc." 472 "Tenneco Inc." 471 "Sea Cross Marine AB" 628 "Falck Schmidt Defence Systems" 627 "Radio Ocean" 626 "AVL DiTEST GmbH" 625 "Global MRV Inc." 624 "Blackbox Machine Control Pty Ltd" 623 "Xirgo Technologies" 622 "Floyd Bell Inc" 621 "Hagie Manufacturing Company" 620 "Sevcon Ltd." 619 "Right Weigh Load Scales" 618 "Evrard SA" 617 "Zero Emission Vehicles" 616 "SMART-TEC s.r.o." 615 "Networkfleet, Verizon Telematics" 614 "ARLT Technologies GmbH" 613 "HKS Co., Ltd." 612 "Samwon IT" 611 "Esterline" 610 "Trail Tech" 609 "Walvoil S.p.A." 608 "Gale Banks Engineering" 607 "Knappco/Civacon" 606 "Intellian Technologies" 605 "Aventics GmbH" 604 "Indexator Rototilt Systems AB" 603 "Kereval" 602 "Nomad Digital Ltd." 601 "Navitas Systems" 600 "Aquatic AV" 599 "Spudnik Equipment Co, LLC" 598 "ABB Turbo Systems Ltd" 597 "Hydac Filter Systems GmbH" 596 "Brunelco Electronic Innovators B.V." 595 "CustomWare" 594 "Kongsberg Automotive" 593 "Sensata Technologies" 592 "tecsis GmbH" 591 "United States Coast Guard" 590 "ARGO-HYTOS GMBH" 589 "MICO, Inc." 588 "Vignal Systems" 587 "JCA Electronics" 586 "Suzuki Motor Corp" 585 "Industrial Electronic Controls" 584 "CarMedialab GmbH" 583 "Yachtcontrol" 582 "Innovative Software Engineering" 581 "Väderstad - Verken AB" 580 "San Jose Technology, Inc." 579 "KVH Industries, Inc." 578 "advanSea" 577 "Denchi Power Ltd  (formerly ABSL Power Solutions Limited)" 576 "Vectia" 575 "Lytx" 574 "Vishay Precision Group" 573 "Orolia Ltd" 572 "Fasse Valves" 571 "Marinecraft Co., Ltd." 570 "frenzel + berg electronic GmbH & Co. KG" 569 "LORD MicroStrain Sensing Systems" 568 "Makersan Ltd. Co." 567 "Lithiumstart LLC" 566 "Geode Technology, Inc." 565 "Micro-Trak Systems, Inc." 564 "Auto Power Electronic" 563 "LOHR Sistemas Eletronicos LTDA" 562 "Bombardier Transportation GmbH" 561 "b-plus GmbH" 560 "Iowa State University, Agricultural and Biosystems Engineering" 559 "Four Peaks Navigation" 558 "Davis Instruments Corp." 557 "Rockson Automation GmbH" 556 "Doosan Infracore Norway" 555 "Sasaki Corporation" 554 "iris-GmbH infrared & intelligent sensors" 553 "KIB Electronics" 552 "Matsuyama Plow Mfg Co, Ltd" 551 "Wexler CSD Ltd." 550 "SUN-A Corporation" 549 "ROAD Deutschland GmbH" 548 "TM4 Inc." 547 "Thomson Linear LLC" 546 "Maruyama Mfg Co, Inc." 545 "GS Hydraulics" 544 "Au Group Electronics" 543 "BAUER Maschinen GmbH" 542 "Dinamica Generale s.p.a." 541 "Total Fire Systems, Inc." 540 "Dinex A/S" 539 "Mobileview" 538 "Crop Ventures, Inc." 537 "Schrader Electronics Ltd." 536 "SSI Technologies" 535 "MOTORPAL, a.s." 534 "Webasto Thermo & Comfort SE" 533 "Doran Manufacturing, LLC" 532 "Onwa Marine Electronics Co Ltd." 531 "Genge & Thoma AG" 530 "NMEA" 529 "National Instruments Korea" 528 "Hoganas AB, Electric Drive Systems" 527 "GKN Walterscheid GmbH" 526 "LOFA Industries, Inc" 525 "Rust Sales INC" 470 "SI-TEX Marine Electronics" 469 "RA Consulting GmbH" 468 "Tyco Fire Protection Products" 467 "Lely Industries N.V." 466 "Veethree Electronics and Marine LLC" 465 "Ashcroft Inc" 464 "Leach International Corporation" 463 "PROBOTIQ" 462 "IHI Shibaura Machinery Corporation" 461 "HAWE Hydraulik SE" 460 "San Giorgio S.E.I.N." 459 "Alltek Marine Electronics Corp" 458 "Control Solutions, Inc." 457 "RUSELPROM-ElectricDrive Ltd" 456 "General Kinetics" 455 "ADZ NAGANO GmbH" 454 "NGK Spark Plug Co. Ltd" 453 "Cooper Bussmann" 452 "WIKA Alexander Wiegand SE & Co. KG" 451 "Parker Hannifin Corp" 450 "Dycor Technologies Ltd." 449 "Polaris Industries Inc" 448 "Stanadyne Corporation, Electronics Systems" 447 "Great Plains Mfg." 446 "CertTech, L.L.C." 445 "KAT MECHATRONIC, Electronic Product Division" 444 "ITT Power Solutions" 443 "SignalQuest, Inc." 442 "Horsch Maschinen GmbH" 441 "PTG Reifendruckregelsysteme GmbH" 440 "Cummins Power Generation" 439 "Hyundai Heavy Industries" 438 "Comar Systems Ltd" 437 "Digital Yacht Limited" 436 "Kinze Manufacturing" 435 "Zunhammer GmbH" 434 "Stored Energy Systems" 433 "Rowe Electronics" 432 "S&A Systems, Inc." 431 "Tohatsu Corporation" 430 "Auteq Telematica S.A." 429 "Rota Engineering Ltd." 425 "Methode Electronics Inc, MDI" 424 "Odyne LLC" 423 "BSM Wireless, Inc." 422 "True Heading AB" 421 "Vertex Standard Co, Ltd" 420 "Vermeer Corporation, ACS Group" 419 "Fusion Electronics Ltd" 418 "Intellistick Inc" 417 "KZValve" 416 "Kubota Corporation" 415 "Valid Manufacturing Ltd." 414 "Cattron Group International" 413 "Datapross Nijbroek bv" 412 "WebTech Wireless Inc." 411 "Hy-Drive Technologies Ltd." 410 "COBO S.p.A. Divisione 3B6" 409 "Transfluid S.r.L." 408 "Corvus Energy Ltd." 407 "Comtech Mobile Datacom" 406 "Vecima Networks Inc." 405 "Wema System AS" 404 "Com Nav Marine Ltd" 403 "Trackwell ADS, Inc." 402 "Simma Software, Inc." 401 "Torqeedo GmbH" 400 "Livorsi Marine" 399 "ISEKI & Co., Ltd." 398 "Hilite International" 397 "Sanyo-kiki Co Ltd." 396 "Beyond Measure" 395 "GENTEC S.R.L." 394 "Capi 2 Nederland BV" 393 "Harvest Tec, Inc" 392 "Tianyuan Technology Co Ltd." 391 "Electronic Design for Industry, Inc" 390 "Partech Inc." 389 "Benchmark Electronics, Minnesota Division" 388 "Innomatix, LLC" 387 "Orscheln Products, LLC" 386 "JLG Automation BVBA" 385 "Johnson Outdoor Marine Electronics" 384 "Camano Light" 383 "MCL Industries" 382 "National Agriculture and Food Research Organization" 381 "B & G" 380 "Suntech International Ltd." 379 "Yamabiko Corporation" 378 "Glendinning Marine Products" 377 "ifm electronic gmbh" 376 "Quake Global" 375 "Williams Controls Inc." 374 "Northern Lights, Inc." 373 "Electronic Design Inc." 372 "Delphi" 371 "Heinzmann GmbH & Co. KG" 370 "Rolls-Royce Marine AS" 369 "Power Torque Engineering Ltd" 368 "HANSENHOF_electronic" 367 "Fliegl Agrartechnik" 366 "Viewnyx Corp." 365 "Digi-Star, LLC" 364 "OEM Controls Inc." 363 "BEI Duncan" 362 "Poettinger Landtechnik GmbH (formerly Alois Poettinger Maschinenfabrik GmbH)" 361 "InMach" 360 "HJS Emission Technology GmbH & Co KG   (formerly HJS Fahrzeugtechnik GmbH & Co KG)" 359 "Ludwig Bergmann GmbH" 358 "Victron Energy BV" 357 "Hardi International A/S" 356 "Fischer Panda Generators, Inc" 355 "Mastervolt International B.V." 354 "Junkkari OY" 353 "Hegemon Electronics, Inc." 352 "SAME DEUTZ-FAHR GROUP S.p.A." 351 "Thrane & Thrane" 350 "Noris Marine Systems GmbH & Co KG" 349 "Suonentieto" 348 "Amazonen Werke H. Dreyer" 347 "Honeywell" 346 "Control Solutions" 345 "Korean Maritime University" 344 "Parvus Corporation" 343 "Baumer Group" 342 "THOMAS MAGNETE GmbH" 341 "Boning GmbH & Co" 340 "Continental AG" 339 "Competence Center ISOBUS e.V." 338 "GRAF-SYTECO" 337 "Carraro S.p.A." 336 "APE s.r.o." 335 "Evo Electric Ltd" 334 "Takata-Petri AG" 333 "Hadley Products Corporation" 332 "HWH Corporation" 331 "Horton, Inc." 330 "Kidde Aerospace and Defense" 329 "Deif A/S" 328 "Qwerty Electronik AB" 327 "Sonceboz SA" 326 "Akron Brass Company" 325 "ASM Automation Sensorik Messtechnik GmbH" 324 "Snap-on Diagnostics" 323 "Mobileye Vision Technologies Ltd." 322 "MICHENKA s.r.o." 321 "Ultra Electronics, Electrics" 320 "Miedema Landbouwwerktuigenfabriek B.V." 319 "Cadec Global" 318 "SAT Plan" 317 "Navtronics Bvba" 263 "IMMI" 262 "HydraForce, Inc" 261 "Red Dot Corporation" 260 "Reichhardt GmbH Steuerungstechnik" 259 "Jetter AG" 258 "ARAG" 257 "Honda Motor Co., Ltd" 256 "Tyco Electronics AMP" 255 "MEAS France" 254 "GE Sensing" 253 "Mobile Control Systems" 252 "Sensor-Technik Wiedemann GmbH" 251 "German Agricultural Society, Test Center (DLG)" 250 "Kuhn Group" 249 "Schaltbau GmbH" 248 "Cooper Standard Automotive Active Systems Group" 247 "ePULSE" 246 "Class 1, Inc" 245 "Capstan Ag Systems, Inc." 244 "Techno-Matic" 243 "eRide, Inc." 242 "Kokusandenki Co. Ltd" 241 "Schneider Automation SAS" 240 "Vanair Mfg" 239 "May & Scofield Ltd" 238 "ZF Friedrichshafen AG" 237 "Agtron Enterprises Inc" 236 "NORAC Systems International Inc" 235 "SailorMade Marine Telemetry - Tetra Technology Ltd." 234 "Mondial electronic GmbH" 233 "Yacht Monitoring Solutions Inc." 232 "TSD Integrated Controls" 231 "Topcon Positioning Systems, Inc." 230 "Saucon Technologies" 229 "Garmin International Inc." 228 "Unused (formerly ZF Marine Electronics)" 227 "Lykketronic A/S" 226 "Monaco Coach Corporation" 225 "SKF" 224 "EMMI Network, S.L." 223 "Vaueo Retarder Co., Ltd." 222 "Generac Power Systems, Inc." 221 "SiE" 220 "Beede Electrical Instrument Company, Inc" 219 "Cat OEM Solutions" 218 "Gits Manufacturing Company" 217 "RM Michaelides Software & Elektronik GmbH" 216 "Paneltronics Inc." 215 "Aetna Engineering/Fireboy-Xintex" 214 "MC elettronica Srl" 164 "MTU Friedrichshafen GmbH (formerly DaimlerChrysler Off-Highway)" 163 "BRP Inc." 162 "Axiomatic Technologies" 161 "Offshore Systems (UK) Ltd" 160 "Nido" 159 "NTech Industries Inc" 158 "Firestone Industrial Products Company" 157 "ISSPRO Inc." 156 "ITT Industries - Cannon" 155 "Vetronix Corporation" 154 "Westerbeke Corporation" 153 "Woodward, Industrial Controls Division" 152 "elobau GmbH & Co. KG" 151 "Raven Industries, Inc." 150 "Fleetguard" 149 "Holset" 148 "Blue Water Data, Inc." 147 "Nautibus electronic GmbH" 146 "Maxima Technologies" 145 "MurCal Controls" 144 "Mercury Marine" 143 "W. Gmeiner GmbH & Co." 142 "TRW Automotive (Commercial Steering Systems)" 141 "Thales Navigation Ltd." 140 "Lowrance Electronics, Inc." 139 "Caterpillar Trimble Control Technologies (CTCT), LLC" 138 "Georg Fritzmeier GmbH & Co. KG" 137 "Maretron" 136 "Komatsu Ltd" 135 "Airmar Technology Corporation" 134 "Iris Technology Ltd" 133 "Bucher Schoerling GmbH" 132 "Mulag-Fahrzeugwerk" 131 "ITT Industries" 130 "Nido - Universal Machines B.V." 129 "OMNEX Control Systems Inc." 128 "Gerhard Duecker GmbH & Co. KG" 127 "Holland USA" 126 "Driver Tech" 125 "Nevada Automotive Test Center" 124 "Hydac Electronic" 123 "Basler Electric" 122 "FG Wilson (Engineering) Limited" 121 "HED (Hydro Electronic Devices, Inc.)" 120 "RDS Technology Ltd" 119 "IntegriNautics  " 118 "Intron GmbH" 117 "HUSCO International" 116 "BEELINE Technologies" 115 "NACCO Materials Handling Group, Inc." 114 "EControls, Inc." 113 "Stress-Tek, Inc." 112 "MECALAC" 111 "Maschinenfabrik Bernard Krone GmbH" 110 "EPIQ Sensor-Nite" 109 "TeeJet Technologies Denmark (formerly LH Technologies ApS)" 108 "WTK-Elecktronik GmbH" 107 "Grimme Landmaschinen GmbH & Co. KG" 106 "BAE Systems Controls, Inc." 105 "Kiepe Elektrik GmbH & Co. KG" 104 "CLAAS KGaA mbH (formerly CLAAS Selbstfahrende Erntemaschinen GmbH)" 103 "CLAAS E-Systems KGaA mbH & Co. KG (formerly CLAAS Agrosystems GmbH & Co. KG)" 102 "AGCO (formerly AGCO GmbH & Co.)" 101 "Sensoria" 100 "VDO Technik AG" 99 "International Transmissions Ltd (ITL)" 98 "Mueller-Elektronik GmbH & Co" 97 "Ag Leader Technology, Inc." 96 "Mech@tronic IT GmbH" 95 "Pacific Insight Electronics Corp." 94 "CNH Industrial N.V. (formerly CNH Global N.V.)" 93 "Perkins Engines Company Ltd." 92 "Ag-Chem Equipment Co., Inc." 91 "BSG Bodensee Steuergeraete GmbH" 90 "Knorr-Bremse SfN GmbH" 89 "Kverneland Group, Electronics Division" 88 "Satloc Precision GPS" 87 "J.C. Bamford Excavators Ltd (JCB)" 86 "C. E. Niehoff & Company" 85 "Kohler Co" 84 "New Holland UK Limited" 83 "Bendix VORAD Technologies (formerly Eaton VORAD Technologies)" 82 "Bobcat/Ingersoll-Rand (formerly Melroe/Ingersoll-Rand)" 81 "Fire Research Corp." 80 "Twin Disc, Inc." 79 "Daimler Benz AG - Engine Division (PBM)" 78 "Frank W. Murphy Manufacturing, Inc" 77 "Deere Power Systems Group" 76 "unused (formerly Deere & Co, Construction Division)" 75 "Deere & Co, Agricultural Division" 74 "Eaton Axle-Brake Division" 73 "LeTourneau, Inc." 72 "Sisu Corporation" 71 "Vansco Electronics Ltd." 70 "Flex-coil Limited" 69 "Trimble Navigation" 316 "ITT Flow Control" 315 "Icom Incorporated" 314 "CSM GmbH" 313 "Ilmor Engineering, Inc." 312 "Lectronix, Inc." 311 "Patrick Power Products" 310 "TECNORD srl" 309 "Krauss-Maffei Wegmann GmbH & Co. KG" 308 "Cyntrx" 307 "MAS Technologies" 306 "Sleipner Motor AB" 305 "NovAtel Inc" 304 "EmpirBus AB" 303 "CTS Corporation" 302 "Nissin Kogyo Co., LTD" 301 "Parker Hannifin (UK) Ltd FDE group" 300 "Systron Donner Automotive" 299 "Rauch" 298 "Holley Performance" 297 "Zonar Systems Inc" 296 "micro dynamics GmbH" 295 "BEP Marine" 294 "Grayhill Inc." 293 "Spyder Controls Corp." 292 "IKUSI - Angel Iglesias S.A." 291 "Groeneveld Transport Efficiency BV" 290 "Kuebler GmbH" 289 "Watlow" 288 "Mitsubishi FUSO Truck & Bus Corp." 287 "NTech Industries, Inc" 286 "Coelmo srl" 285 "Sea Recovery Corp" 284 "Mobile Tech Chile" 283 "CWF Hamilton & Co Ltd" 282 "Medallion Instrumentation Systems" 281 "Precision Governors LLC" 280 "Leica Geosystems Pty Ltd" 279 "Geometris LP" 278 "Takata Electronics" 277 "LHP Telematics" 276 "Aqua-Hot Heating Systems" 275 "Navico Egersund AS" 274 "LTW Technology Co., LTD" 273 "Active Research Limited" 272 "Gross Mechanical Laboratories, Inc" 271 "Cole Hersee" 270 "Tennant" 269 "Saft America Inc.,  Space & Defense Division" 268 "Accurate Technologies" 267 "Red Lion Controls, Inc" 266 "International Thermal Research Ltd" 265 "MTS Sensor Technologie GmbH" 264 "Autolync" 213 "CNH Belgium N.V." 212 "Sure Power Industries, Inc" 211 "DNA Group" 210 "Iteris, Inc." 209 "Bell Equip. Co. SA (PTY) LTD" 208 "Drew Technologies, Inc" 207 "Otto Engineering" 206 "port GmbH" 205 "SmarTire Systems Inc" 204 "The Morey Corporation" 203 "MILtronik GmbH" 202 "Curtis Instruments, Inc" 201 "Disenos y Tecnologia S.A." 200 "MGM Brakes" 199 "Actia Corp" 198 "Mystic Valley Communications" 197 "Mechron Power Systems" 196 "LEMKEN GmbH & Co KG" 195 "General Engine Products" 194 "TriMark Corporation" 193 "Jeppesen Marine" 192 "Floscan" 191 "XRS Corporation (formerly XATA Corporation)" 190 "Hella KGaA Hueck & Co" 189 "QUALCOMM" 188 "EMP Corp" 187 "Air-Weigh" 186 "Altronic, Inc" 185 "Beede Electrical Instrument Company" 184 "EIA Electronics" 183 "KDS Controls, Inc" 182 "Vehicle Systems Engineering B.V." 181 "Coretronics, Inc." 180 "Smart Power Systems" 179 "TeeJet Technologies Springfield (formerly Midwest Technologies Illinois, LLC)" 178 "Continental Automotive GmbH (formerly Siemens VDO Automotive AG)" 177 "Diagnostic Systems Associates" 176 "Moritz Aerospace" 175 "Veris Technologies, Inc." 174 "AB Volvo Penta" 173 "Ryeso, Inc." 172 "Yanmar Co., Ltd. (formerly Yanmar Marine USA)" 171 "Wachendorff Elektronik GmbH & Co. KG" 170 "Computronics Corporation Ltd." 169 "Marlin Technologies Inc." 168 "Xantrex" 167 "JLG Industries Inc" 166 "John Deere Electronic Solutions (formerly Phoenix International)" 165 "CPAC Systems AB" 68 "Scania" 67 "John Deere Coffeyville Works (formerly Funk Manufacturing Company)" 66 "John Deere Construction Equipment Division" 65 "MAN Nutzfahrzeuge AG" 64 "Unused (formerly SpectraPrecision Laserplane, then SpectraPhysics)" 63 "ZF Industries Inc." 62 "Wabco" 61 "Volvo Truck Corp." 60 "Volvo Trucks North America Inc." 59 "VES Inc." 58 "SPX Corporation, OTC Div" 57 "Danfoss  (formerly Sauer Sundstrand Co, then Sauer-Danfoss Co)" 56 "SAIC" 55 "Ryder System Inc." 54 "Meritor Wabco" 53 "Continental Automotive Systems US, Inc. (formerly Rockwell Land Transportation)" 52 "Meritor Automotive, Inc. (formerly Rockwell Automotive)" 51 "Robert Bosch GmbH" 50 "Robert Bosch Corp" 49 "RE America Inc." 48 "Pollak Alphabet" 47 "Phillips Semiconductor" 46 "Noregon Systems, Inc  (formerly Parasoft Computing Solutions)" 45 "PACCAR" 44 "Nippondenso Co. Ltd." 43 "International Truck and Engine Corporation - Vehicle Electronics (formerly Navistar Intl Trans Corp.)" 42 "International Truck and Engine Corporation - Engine Electronics  (formerly Navistar Intl Trans Co., Engine Electronics)" 41 "Motorola Inc." 40 "Motorola AIEG Inc." 39 "Microfirm Inc." 38 "Micro Processor Systems Inc." 37 "Mack Trucks Inc." 36 "Lucas Ind." 35 "Kenworth Truck Co." 34 "Kelsey Hayes Co." 33 "John Deere" 32 "Jacobs Vehicle Systems" 31 "J Pollak Corp" 30 "Isuzu Motors Ltd" 29 "Hino Motors Ltd." 28 "Grote Ind. Inc." 27 "GMC" 26 "General Motors Corp, Service Technology Grp" 25 "Daimler Trucks North America LLC (formerly Freightliner LLC)" 24 "Ford Motor Co., Vehicle Controls" 23 "Ford Motor Co., Heavy Truck" 22 "Ford Motor Co., Electronic Concepts & Systems" 21 "Echlin Inc., Midland Brake Inc." 20 "Eaton Ltd" 19 "Eaton Corp. Trucking Info Services" 18 "Eaton Corp, Transmission Div." 17 "Eaton Corp, Corp Res & Dev" 16 "Eaton Corp" 15 "DICKEY-john Corporation" 14 "Detroit Diesel Corporation" 13 "Delco Electronics" 12 "Deere & Company, Precision Farming" 11 "Dearborn Group Inc." 10 "Cummins Inc (formerly Cummins Engine Co)" 9 "Chrysler Corp." 8 "Caterpillar Inc." 7 "Case Corp." 6 "Berifors Electronics AB" 5 "AMP Inc." 4 "Ametek-Dixson" 3 "Ametek, US Gauge Division" 2 "Allison Transmission, Inc." 1 "Bendix Commercial Vehicle Systems LLC (formerly Allied Signal Inc.)" 0 "Reserved" ;
VAL_ 2566734590 CertLaboratoryType_FirstDef 7 "Not available (not certified) " 0 "Non-certified laboratory/self-test" 1 "AEF certified laboratory " 2 "Reserved " ;
VAL_ 2566734590 MessageRevision 1 "Third and later edition message revision" 0 "Format of message in second edition." ;
VAL_ 2566734590 CertificationReferenceNumber 0 "NotCertified" 1 "CertificationTestPerformed" ;
VAL_ 2566734590 CertTypeTaskController 0 "NotCertified" 1 "CertificationTestPerformed" ;
VAL_ 2566734590 CertTypeTCWorkingSetMaster 0 "NotCertified" 1 "CertificationTestPerformed" ;
VAL_ 2566734590 CertTypeTCWorkingSetMember 0 "NotCertified" 1 "CertificationTestPerformed" ;
VAL_ 2566734590 CertTypeFileServer 0 "NotCertified" 1 "CertificationTestPerformed" ;
VAL_ 2566734590 CertTypeGPSReceiver 0 "NotCertified" 1 "CertificationTestPerformed" ;
VAL_ 2566734590 CertTypeMinimumECU 0 "NotCertified" 1 "CertificationTestPerformed" ;
VAL_ 2566734590 CertTypeTECUClass1 0 "NotCertified" 1 "CertificationTestPerformed" ;
VAL_ 2566734590 CertTypeTECUClass2 0 "NotCertified" 1 "CertificationTestPerformed" ;
VAL_ 2566734590 CertTypeTECUClass3 0 "NotCertified" 1 "CertificationTestPerformed" ;
VAL_ 2566734590 CertTypeClass3ECU 0 "NotCertified" 1 "CertificationTestPerformed" ;
VAL_ 2566734590 CertTypeVirtualTerminal 0 "NotCertified" 1 "CertificationTestPerformed" ;
VAL_ 2566734590 CertTypeVTWorkingSetMaster 0 "NotCertified" 1 "CertificationTestPerformed" ;
VAL_ 2566734590 CertTypeVTWorkingSetMember 0 "NotCertified" 1 "CertificationTestPerformed" ;
VAL_ 2566734590 CertLaboratoryType_SecondDef 3 "Not available (not certified) " 0 "Non-certified Laboratory/self-certification" 1 "AEF certified laboratory " 2 "Reserved " ;
VAL_ 2566734590 TestProtocolRevision 0 "FirstRevision" 1 "SecondRevision" 2 "ThirdRevision" 3 "NotAvailable" ;
VAL_ 2365391616 ImplementOperatingStateCmd 0 "SetImplementToFieldWorkingState" 1 "SetImplementToTransportState" 2 "SetImplementToParkState" 3 "TakeNoAction" ;
VAL_ 2365391614 StopAllImplOpSwitchState 0 "StopImplementOperations" 1 "PermitAllImplementsToON " 2 "ErrorIndication" 3 "NotAvailable " ;
VAL_ 2559835902 NMControlModeIndicator 0 "SetPendingName" 1 "PendingName" 2 "CurrentName" 3 "NameACK" 4 "NameNACK" 5 "ReqPendingName" 6 "ReqCurrentName" 7 "AdoptPendingName" 8 "ReqNameAddressClaim" ;
VAL_ 2559835902 ErrorCode 0 "Security not satisfied" 1 "Item(s) not allowed to change" 2 "Item conflict" 3 "Checksum does not match" 4 "Pending Name not set" 255 "Not Available" 5 "Other" ;
VAL_ 2566704384 DriveStrategyExitReason 0 "No reason/all clear " 1 "Operator presence not detected " 2 "Implement released control of function " 3 "Operator override of function " 4 "Operator control not in valid position" 5 "Remote command timeout" 6 "Remote command out of range/invalid " 7 "Function not calibrated " 8 "Operator control fault" 9 "Function fault " 22 "Vehicle transmission gear does not allow remote commands" 62 "Error " 63 "Not available (parameter not supported) " ;
VAL_ 2566704384 DriveStrategyPriority1 0 "Enable maximum draft power control " 1 "Enable constant PTO speed control" 2 "Enable wheel speed/PTO speed ratio control" 3 "Enable minimum engine speed control" 4 "Enable engine economy control " 5 "Enable maximum hydraulic power control" 6 "Enable maximum electric power control" 253 "Requested mode not supported " 254 "Error or reserved" 255 "Not available/Don't care " ;
VAL_ 2566704384 DriveStrategyPriority2 0 "Enable maximum draft power control " 1 "Enable constant PTO speed control" 2 "Enable wheel speed/PTO speed ratio control" 3 "Enable minimum engine speed control" 4 "Enable engine economy control " 5 "Enable maximum hydraulic power control" 6 "Enable maximum electric power control" 253 "Requested mode not supported " 254 "Error or reserved" 255 "Not available/Don't care " ;
VAL_ 2566704384 DriveStrategyPriority3 0 "Enable maximum draft power control " 1 "Enable constant PTO speed control" 2 "Enable wheel speed/PTO speed ratio control" 3 "Enable minimum engine speed control" 4 "Enable engine economy control " 5 "Enable maximum hydraulic power control" 6 "Enable maximum electric power control" 253 "Requested mode not supported " 254 "Error or reserved" 255 "Not available/Don't care " ;
VAL_ 2566704384 DriveStrategyPriority4 0 "Enable maximum draft power control " 1 "Enable constant PTO speed control" 2 "Enable wheel speed/PTO speed ratio control" 3 "Enable minimum engine speed control" 4 "Enable engine economy control " 5 "Enable maximum hydraulic power control" 6 "Enable maximum electric power control" 253 "Requested mode not supported " 254 "Error or reserved" 255 "Not available/Don't care " ;
VAL_ 2566704384 DriveStrategyRequestState 0 "External Request Accepted. No subsequent operator intervention" 1 "Control override (most recent external request ignored)" 2 "Error indication " 3 "Not available/Not Installed " ;
VAL_ 2365378048 DriveStrategyPriority1Req 0 "Enable maximum draft power control " 1 "Enable constant PTO speed control" 2 "Enable wheel speed/PTO speed ratio control" 3 "Enable minimum engine speed control" 4 "Enable engine economy control " 5 "Enable maximum hydraulic power control" 6 "Enable maximum electric power control" 254 "Error or reserved" 255 "Not available/Don't care " ;
VAL_ 2365378048 DriveStrategyPriority2Req 0 "Enable maximum draft power control " 1 "Enable constant PTO speed control" 2 "Enable wheel speed/PTO speed ratio control" 3 "Enable minimum engine speed control" 4 "Enable engine economy control " 5 "Enable maximum hydraulic power control" 6 "Enable maximum electric power control" 254 "Error or reserved" 255 "Not available/Don't care " ;
VAL_ 2365378048 DriveStrategyPriority3Req 0 "Enable maximum draft power control " 1 "Enable constant PTO speed control" 2 "Enable wheel speed/PTO speed ratio control" 3 "Enable minimum engine speed control" 4 "Enable engine economy control " 5 "Enable maximum hydraulic power control" 6 "Enable maximum electric power control" 254 "Error or reserved" 255 "Not available/Don't care " ;
VAL_ 2365378048 DriveStrategyPriority4Req 0 "Enable maximum draft power control " 1 "Enable constant PTO speed control" 2 "Enable wheel speed/PTO speed ratio control" 3 "Enable minimum engine speed control" 4 "Enable engine economy control " 5 "Enable maximum hydraulic power control" 6 "Enable maximum electric power control" 254 "Error or reserved" 255 "Not available/Don't care " ;
VAL_ 2365378048 RestoreOpDriveStratSetReq 0 "No Request (sent when implement does not want setting restored) " 1 "Restore Operator Drive Strategy Setting " 2 "Error indication " 3 "Not available " ;
VAL_ 2566688510 Functionality 0 "Minimum control function  " 1 "Universal terminal (server)" 2 "Universal terminal working set (client) " 3 "Aux-O inputs " 4 "Aux-O functions " 5 "Aux-N inputs " 6 "Aux-N functions " 7 "Task controller basic (server) " 8 "Task controller basic working set (client)" 9 "Task controller geo (server) " 10 "Task controller geo working set (client) " 11 "Task controller section control (server) " 12 "Task controller section control working set (client)" 13 "Basic Tractor ECU (server) " 14 "Basic Tractor ECU implement set (client) " ;
SG_MUL_VAL_ 2362179326 MinimumProductPressure DDI 195-195;
SG_MUL_VAL_ 2362179326 MaximumProductPressure DDI 196-196;
SG_MUL_VAL_ 2362179326 SetpointPumpOutputPressure DDI 197-197;
SG_MUL_VAL_ 2362179326 ActualPumpOutputPressure DDI 198-198;
SG_MUL_VAL_ 2362179326 MinimumPumpOutputPressure DDI 199-199;
SG_MUL_VAL_ 2362179326 MaximumPumpOutputPressure DDI 200-200;
SG_MUL_VAL_ 2362179326 SetpointTankAgitationPressure DDI 201-201;
SG_MUL_VAL_ 2362179326 ActualTankAgitationPressure DDI 202-202;
SG_MUL_VAL_ 2362179326 MinimumTankAgitationPressure DDI 203-203;
SG_MUL_VAL_ 2362179326 MaximumTankAgitationPressure DDI 204-204;
SG_MUL_VAL_ 2362179326 SCTurnOnTime_ DDI 205-205;
SG_MUL_VAL_ 2362179326 SCTurnOffTime DDI 206-206;
SG_MUL_VAL_ 2362179326 WindSpeed DDI 207-207;
SG_MUL_VAL_ 2362179326 WindDirection DDI 208-208;
SG_MUL_VAL_ 2362179326 AirHumidity DDI 209-209;
SG_MUL_VAL_ 2362179326 SkyConditions DDI 210-210;
SG_MUL_VAL_ 2362179326 LastBaleFlakesPerBale DDI 211-211;
SG_MUL_VAL_ 2362179326 LastBaleAverageMoisture DDI 212-212;
SG_MUL_VAL_ 2362179326 LastBaleAverageStrokesPerFlake DDI 213-213;
SG_MUL_VAL_ 2362179326 LifetimeBaleCount DDI 214-214;
SG_MUL_VAL_ 2362179326 LifetimeWorkingHours DDI 215-215;
SG_MUL_VAL_ 2362179326 ActualBaleHydraulicPressure DDI 216-216;
SG_MUL_VAL_ 2362179326 LastBaleAverageHydraulicPressure DDI 217-217;
SG_MUL_VAL_ 2362179326 SetpointBaleCompressionPlungerLo DDI 218-218;
SG_MUL_VAL_ 2362179326 ActualBaleCompressionPlungerLoad DDI 219-219;
SG_MUL_VAL_ 2362179326 LastBaleAverageBaleCompressionPl DDI 220-220;
SG_MUL_VAL_ 2362179326 LastBaleAppliedPreservative DDI 221-221;
SG_MUL_VAL_ 2362179326 LastBaleTagNumber DDI 222-222;
SG_MUL_VAL_ 2362179326 LastBaleMass DDI 223-223;
SG_MUL_VAL_ 2362179326 DeltaT DDI 224-224;
SG_MUL_VAL_ 2362179326 SetpointWorkingLength DDI 225-225;
SG_MUL_VAL_ 2362179326 ActualWorkingLength DDI 226-226;
SG_MUL_VAL_ 2362179326 MinimumWorkingLength DDI 227-227;
SG_MUL_VAL_ 2362179326 MaximumWorkingLength DDI 228-228;
SG_MUL_VAL_ 2362179326 ActualNetWeight DDI 229-229;
SG_MUL_VAL_ 2362179326 NetWeightState DDI 230-230;
SG_MUL_VAL_ 2362179326 SetpointNetWeight DDI 231-231;
SG_MUL_VAL_ 2362179326 ActualGrossWeight DDI 232-232;
SG_MUL_VAL_ 2362179326 GrossWeightState DDI 233-233;
SG_MUL_VAL_ 2362179326 MinimumGrossWeight DDI 234-234;
SG_MUL_VAL_ 2362179326 MaximumGrossWeight DDI 235-235;
SG_MUL_VAL_ 2362179326 ThreshingEngagementTotalTime DDI 236-236;
SG_MUL_VAL_ 2362179326 ActualHeaderWorkingHeightStatus DDI 237-237;
SG_MUL_VAL_ 2362179326 ActualHeaderRotationalSpeedStatu DDI 238-238;
SG_MUL_VAL_ 2362179326 YieldHoldStatus DDI 239-239;
SG_MUL_VAL_ 2362179326 ActualUnLoadingSystemStatus DDI 240-240;
SG_MUL_VAL_ 2362179326 CropTemperature DDI 241-241;
SG_MUL_VAL_ 2362179326 SetpointSieveClearance DDI 242-242;
SG_MUL_VAL_ 2362179326 ActualSieveClearance DDI 243-243;
SG_MUL_VAL_ 2362179326 MinimumSieveClearance DDI 244-244;
SG_MUL_VAL_ 2362179326 MaximumSieveClearance DDI 245-245;
SG_MUL_VAL_ 2362179326 SetpointChafferClearance DDI 246-246;
SG_MUL_VAL_ 2362179326 ActualChafferClearance DDI 247-247;
SG_MUL_VAL_ 2362179326 MinimumChafferClearance DDI 248-248;
SG_MUL_VAL_ 2362179326 MaximumChafferClearance DDI 249-249;
SG_MUL_VAL_ 2362179326 SetpointConcaveClearance DDI 250-250;
SG_MUL_VAL_ 2362179326 ActualConcaveClearance DDI 251-251;
SG_MUL_VAL_ 2362179326 MinimumConcaveClearance DDI 252-252;
SG_MUL_VAL_ 2362179326 MaximumConcaveClearance DDI 253-253;
SG_MUL_VAL_ 2362179326 SetpointSeparationFanRotationalS DDI 254-254;
SG_MUL_VAL_ 2362179326 ActualSeparationFanRotationalSpe DDI 255-255;
SG_MUL_VAL_ 2362179326 MinimumSeparationFanRotationalSp DDI 256-256;
SG_MUL_VAL_ 2362179326 MaximumSeparationFanRotationalSp DDI 257-257;
SG_MUL_VAL_ 2362179326 HydraulicOilTemperature DDI 258-258;
SG_MUL_VAL_ 2362179326 YieldLagIgnoreTime DDI 259-259;
SG_MUL_VAL_ 2362179326 YieldLeadIgnoreTime DDI 260-260;
SG_MUL_VAL_ 2362179326 AverageYieldMassPerTime DDI 261-261;
SG_MUL_VAL_ 2362179326 AverageCropMoisture DDI 262-262;
SG_MUL_VAL_ 2362179326 AverageYieldMassPerArea DDI 263-263;
SG_MUL_VAL_ 2362179326 ConnectorPivotXOffset DDI 264-264;
SG_MUL_VAL_ 2362179326 RemainingArea DDI 265-265;
SG_MUL_VAL_ 2362179326 LifetimeApplicationTotalMass DDI 266-266;
SG_MUL_VAL_ 2362179326 LifetimeApplicationTotalCount DDI 267-267;
SG_MUL_VAL_ 2362179326 LifetimeYieldTotalVolume DDI 268-268;
SG_MUL_VAL_ 2362179326 LifetimeYieldTotalMass DDI 269-269;
SG_MUL_VAL_ 2362179326 LifetimeYieldTotalCount DDI 270-270;
SG_MUL_VAL_ 2362179326 LifetimeTotalArea DDI 271-271;
SG_MUL_VAL_ 2362179326 LifetimeTotalDistance DDI 272-272;
SG_MUL_VAL_ 2362179326 LifetimeIneffectiveTotalDistance DDI 273-273;
SG_MUL_VAL_ 2362179326 LifetimeEffectiveTotalTime DDI 274-274;
SG_MUL_VAL_ 2362179326 LifetimeIneffectiveTotalTime DDI 275-275;
SG_MUL_VAL_ 2362179326 LifetimeFuelConsumption DDI 276-276;
SG_MUL_VAL_ 2362179326 LifetimeAverageFuelConsumptionPe DDI 277-277;
SG_MUL_VAL_ 2362179326 LifetimeAverageFuelConsumpt_0000 DDI 278-278;
SG_MUL_VAL_ 2362179326 LifetimeYieldTotalDryMass DDI 279-279;
SG_MUL_VAL_ 2362179326 LifetimeYieldTotalSeedCottonMass DDI 280-280;
SG_MUL_VAL_ 2362179326 LifetimeYieldTotalLintCottonMass DDI 281-281;
SG_MUL_VAL_ 2362179326 LifetimeThreshingEngagementTotal DDI 282-282;
SG_MUL_VAL_ 2362179326 PrecutTotalCount DDI 283-283;
SG_MUL_VAL_ 2362179326 UncutTotalCount DDI 284-284;
SG_MUL_VAL_ 2362179326 LifetimePrecutTotalCount DDI 285-285;
SG_MUL_VAL_ 2362179326 LifetimeUncutTotalCount DDI 286-286;
SG_MUL_VAL_ 2362179326 SetpointWorkState DDI 289-289;
SG_MUL_VAL_ 2362179326 SetpointCondensedWorkState1to16 DDI 290-290;
SG_MUL_VAL_ 2362179326 SetpointCondensedWorkState17to32 DDI 291-291;
SG_MUL_VAL_ 2362179326 SetpointCondensedWorkState33to48 DDI 292-292;
SG_MUL_VAL_ 2362179326 SetpointCondensedWorkState49to64 DDI 293-293;
SG_MUL_VAL_ 2362179326 SetpointCondensedWorkState65to80 DDI 294-294;
SG_MUL_VAL_ 2362179326 SetpointCondensedWorkState81to96 DDI 295-295;
SG_MUL_VAL_ 2362179326 SetpointCondensedWorkState97to11 DDI 296-296;
SG_MUL_VAL_ 2362179326 SetpointCondensedWorkState113to1 DDI 297-297;
SG_MUL_VAL_ 2362179326 SetpointCondensedWorkState129to1 DDI 298-298;
SG_MUL_VAL_ 2362179326 SetpointCondensedWorkState145to1 DDI 299-299;
SG_MUL_VAL_ 2362179326 SetpointCondensedWorkState161to1 DDI 300-300;
SG_MUL_VAL_ 2362179326 SetpointCondensedWorkState177to1 DDI 301-301;
SG_MUL_VAL_ 2362179326 SetpointCondensedWorkState193to2 DDI 302-302;
SG_MUL_VAL_ 2362179326 SetpointCondensedWorkState209to2 DDI 303-303;
SG_MUL_VAL_ 2362179326 SetpointCondensedWorkState225to2 DDI 304-304;
SG_MUL_VAL_ 2362179326 SetpointCondensedWorkState241to2 DDI 305-305;
SG_MUL_VAL_ 2362179326 TrueRotationPointXOffset DDI 306-306;
SG_MUL_VAL_ 2362179326 TrueRotationPointYOffset DDI 307-307;
SG_MUL_VAL_ 2362179326 ActualPercentageApplicationRate DDI 308-308;
SG_MUL_VAL_ 2362179326 MinimumPercentageApplicationRate DDI 309-309;
SG_MUL_VAL_ 2362179326 MaximumPercentageApplicationRate DDI 310-310;
SG_MUL_VAL_ 2362179326 RelativeYieldPotential DDI 311-311;
SG_MUL_VAL_ 2362179326 MinimumRelativeYieldPotential DDI 312-312;
SG_MUL_VAL_ 2362179326 MaximumRelativeYieldPotential DDI 313-313;
SG_MUL_VAL_ 2362179326 ActualPercentageCropDryMatter DDI 314-314;
SG_MUL_VAL_ 2362179326 AveragePercentageCropDryMatter DDI 315-315;
SG_MUL_VAL_ 2362179326 EffectiveTotalFuelConsumption DDI 316-316;
SG_MUL_VAL_ 2362179326 IneffectiveTotalFuelConsumption DDI 317-317;
SG_MUL_VAL_ 2362179326 EffectiveTotalDieselExhaustFluid DDI 318-318;
SG_MUL_VAL_ 2362179326 IneffectiveTotalDieselExhaustFlu DDI 319-319;
SG_MUL_VAL_ 2362179326 LastLoadedWeight DDI 320-320;
SG_MUL_VAL_ 2362179326 LastUnloadedWeight DDI 321-321;
SG_MUL_VAL_ 2362179326 PGNBasedData DDI 57342-57342;
SG_MUL_VAL_ 2362179326 RequestDefaultProcessData DDI 57343-57343;
SG_MUL_VAL_ 2362179326 ObjectIdOfFaultyObject DeviceDescriptionMsgType 9-9;
SG_MUL_VAL_ 2362179326 ErrorCodeProcessData1 Command 13-13;
SG_MUL_VAL_ 2362179326 StatusTotalsActive Command 14-14;
SG_MUL_VAL_ 2362179326 Status_TotalsActive Command 15-15;
SG_MUL_VAL_ 2362179326 DateFormatCmd DeviceDescriptionMsgType 2-2, 3-3;
SG_MUL_VAL_ 2362179326 DataDictionaryVersion DDI 0-0;
SG_MUL_VAL_ 2362179326 PeerControlCommand Command 9-9;
SG_MUL_VAL_ 2362179326 DecimalSymbolCmd DeviceDescriptionMsgType 2-2, 3-3;
SG_MUL_VAL_ 2362179326 TimeFormatCmd DeviceDescriptionMsgType 2-2, 3-3;
SG_MUL_VAL_ 2362179326 ImplementSectionControl TechnicalDataMsgType 1-1;
SG_MUL_VAL_ 2362179326 PeerControlAssignment TechnicalDataMsgType 1-1;
SG_MUL_VAL_ 2362179326 TC_GEO_DefinitionPositionBasedCo TechnicalDataMsgType 1-1;
SG_MUL_VAL_ 2362179326 TimeAndPositionForDataLogging TechnicalDataMsgType 1-1;
SG_MUL_VAL_ 2362179326 Documentation TechnicalDataMsgType 1-1;
SG_MUL_VAL_ 2362179326 ErrorCodeChangeDesignator DeviceDescriptionMsgType 13-13;
SG_MUL_VAL_ 2362179326 DesignatorLength DeviceDescriptionMsgType 12-12;
SG_MUL_VAL_ 2362179326 ErrorDetailObjectPoolDelete DeviceDescriptionMsgType 11-11;
SG_MUL_VAL_ 2362179326 DDI_TI Command 4-4;
SG_MUL_VAL_ 2362179326 DDI_DI Command 5-5;
SG_MUL_VAL_ 2362179326 ErrorDDI Command 13-13;
SG_MUL_VAL_ 2362179326 ParentObjectIdOfFaultyObject DeviceDescriptionMsgType 9-9;
SG_MUL_VAL_ 2362179326 ReceivedDataSize DeviceDescriptionMsgType 7-7;
SG_MUL_VAL_ 2362179326 DDI Command 2-2, 3-3, 6-8, 10-10;
SG_MUL_VAL_ 2362179326 BootTimeTC TechnicalDataMsgType 1-1;
SG_MUL_VAL_ 2362179326 PeerControlDDI Command 9-9;
SG_MUL_VAL_ 2362179326 ErrorCodeObjPoolActiveResp4 DeviceDescriptionMsgType 9-9;
SG_MUL_VAL_ 2362179326 LanguageCodeCmd DeviceDescriptionMsgType 2-2, 3-3;
SG_MUL_VAL_ 2362179326 ErrorCodeObjPoolActiveResp3 DeviceDescriptionMsgType 9-9;
SG_MUL_VAL_ 2362179326 ErrorCodeObjPoolActiveResp2 DeviceDescriptionMsgType 9-9;
SG_MUL_VAL_ 2362179326 StructureLabel DeviceDescriptionMsgType 0-0, 1-1;
SG_MUL_VAL_ 2362179326 VersionNumberISO11783Part10 TechnicalDataMsgType 1-1;
SG_MUL_VAL_ 2362179326 RequestTransferDataSize DeviceDescriptionMsgType 4-4;
SG_MUL_VAL_ 2362179326 Status DeviceDescriptionMsgType 5-5;
SG_MUL_VAL_ 2362179326 ErrorCodeObjPoolTransfer DeviceDescriptionMsgType 7-7;
SG_MUL_VAL_ 2362179326 ActivateDeactivateCommand DeviceDescriptionMsgType 8-8;
SG_MUL_VAL_ 2362179326 ErrorCodeObjectPoolDelete DeviceDescriptionMsgType 11-11;
SG_MUL_VAL_ 2362179326 ObjectIdToChange DeviceDescriptionMsgType 12-12;
SG_MUL_VAL_ 2362179326 ObjectIdChanged DeviceDescriptionMsgType 13-13;
SG_MUL_VAL_ 2362179326 ErrorCodeObjPoolActiveResp1 DeviceDescriptionMsgType 9-9;
SG_MUL_VAL_ 2362179326 TechnicalDataMsgType Command 0-0;
SG_MUL_VAL_ 2362179326 DeviceDescriptionMsgType Command 1-1;
SG_MUL_VAL_ 2362179326 ElementNumber Command 2-10;
SG_MUL_VAL_ 2362179326 ErrorElementNumber Command 13-13;
SG_MUL_VAL_ 2362179326 NumberOfControlChannels TechnicalDataMsgType 1-1;
SG_MUL_VAL_ 2559835902 ManufacturerCodeQualifierFlag NMControlModeIndicator 0-0, 4-4, 8-8;
SG_MUL_VAL_ 2559835902 ECUInstanceQualifierFlag NMControlModeIndicator 0-0, 4-4, 8-8;
SG_MUL_VAL_ 2559835902 FunctionInstanceQualifierFlag NMControlModeIndicator 0-0, 4-4, 8-8;
SG_MUL_VAL_ 2559835902 FunctionQualifierFlag NMControlModeIndicator 0-0, 4-4, 8-8;
SG_MUL_VAL_ 2559835902 VehicleSystemQualifierFlag NMControlModeIndicator 0-0, 4-4, 8-8;
SG_MUL_VAL_ 2559835902 VehicleSystemInstanceQualifierFl NMControlModeIndicator 0-0, 4-4, 8-8;
SG_MUL_VAL_ 2559835902 IndustryGroupQualifierFlag NMControlModeIndicator 0-0, 4-4, 8-8;
SG_MUL_VAL_ 2559835902 ArbitraryAddressCapableQualifier NMControlModeIndicator 0-0, 4-4, 8-8;
SG_MUL_VAL_ 2559835902 CommandManufacturerCode NMControlModeIndicator 0-3, 8-8;
SG_MUL_VAL_ 2559835902 CommandECUInstance NMControlModeIndicator 0-3, 8-8;
SG_MUL_VAL_ 2559835902 CommandFunctionInstance NMControlModeIndicator 0-3, 8-8;
SG_MUL_VAL_ 2559835902 CommandFunction NMControlModeIndicator 0-3, 8-8;
SG_MUL_VAL_ 2559835902 CommandVehicleSystem NMControlModeIndicator 0-3, 8-8;
SG_MUL_VAL_ 2559835902 CommandIndustryGroup NMControlModeIndicator 0-3, 8-8;
SG_MUL_VAL_ 2559835902 CommandVehicleSystemInstance NMControlModeIndicator 0-3, 8-8;
SG_MUL_VAL_ 2559835902 CommandArbitraryAddressCapable NMControlModeIndicator 0-3, 8-8;
